[part 1 of 2: package /COM/VECTOR/CFG/WORKFLOW/SYSDESC/SYNC]
AUTOSAR XML (schema 4-2-2)
package /COM/VECTOR/CFG/WORKFLOW/SYSDESC/SYNC
  system SYSTEM
    system mapping MAPPINGS
      data-mappings:
        data-element=COMPOSITIONTYPE.Ford_PwPckTq_D_Stat.Ford_PwPckTq_D_Stat, system-signal=PwPckTq_D_Stat
        data-element=COMPOSITIONTYPE.Ford_Veh_V_ActlBrk.Ford_Veh_V_ActlBrk, system-signal=Veh_V_ActlBrk
        data-element=COMPOSITIONTYPE.Ford_SteMdule_D_Stat.Ford_SteMdule_D_Stat, system-signal=SteMdule_D_Stat
        data-element=COMPOSITIONTYPE.Ford_SteeringColumnTorque.Ford_SteeringColumnTorque, system-signal=SteeringColumnTorque
        data-element=COMPOSITIONTYPE.Ford_VehVActlBrk_No_Cs.Ford_VehVActlBrk_No_Cs, system-signal=VehVActlBrk_No_Cs
        data-element=COMPOSITIONTYPE.Ford_EPAS_Failure.Ford_EPAS_Failure, system-signal=EPAS_Failure
        data-element=COMPOSITIONTYPE.Ford_TrlrHitchLamp_D_Rqst.Ford_TrlrHitchLamp_D_Rqst, system-signal=TrlrHitchLamp_D_Rqst
        data-element=COMPOSITIONTYPE.Ford_SAPPAngleControlStat2.Ford_SAPPAngleControlStat2, system-signal=SAPPAngleControlStat2
        data-element=COMPOSITIONTYPE.Ford_StePinComp_An_Est.Ford_StePinComp_An_Est, system-signal=StePinComp_An_Est
        data-element=COMPOSITIONTYPE.Ford_ElPw_D_Stat.Ford_ElPw_D_Stat, system-signal=ElPw_D_Stat
        data-element=COMPOSITIONTYPE.Ford_Ignition_Status.Ford_Ignition_Status, system-signal=Ignition_Status
        data-element=COMPOSITIONTYPE.Ford_VehVActlBrk_No_Cnt.Ford_VehVActlBrk_No_Cnt, system-signal=VehVActlBrk_No_Cnt
        data-element=COMPOSITIONTYPE.Ford_StePinCompAnEst_D_Qf.Ford_StePinCompAnEst_D_Qf, system-signal=StePinCompAnEst_D_Qf
        data-element=COMPOSITIONTYPE.Ford_VehVTrlrAid_B_Rq.Ford_VehVTrlrAid_B_Rq, system-signal=VehVTrlrAid_B_Rq
        data-element=COMPOSITIONTYPE.Ford_LsmcBrkDecel_D_Stat.Ford_LsmcBrkDecel_D_Stat, system-signal=LsmcBrkDecel_D_Stat
        data-element=COMPOSITIONTYPE.Ford_SteMdule_U_Meas.Ford_SteMdule_U_Meas, system-signal=SteMdule_U_Meas
        data-element=COMPOSITIONTYPE.Ford_StePinAn_No_Cnt.Ford_StePinAn_No_Cnt, system-signal=StePinAn_No_Cnt
        data-element=COMPOSITIONTYPE.Ford_StePinRelInit_An_Sns.Ford_StePinRelInit_An_Sns, system-signal=StePinRelInit_An_Sns
        data-element=COMPOSITIONTYPE.Ford_StePinAn_No_Cs.Ford_StePinAn_No_Cs, system-signal=StePinAn_No_Cs
        data-element=COMPOSITIONTYPE.Ford_Veh_V_RqMxTrlrAid.Ford_Veh_V_RqMxTrlrAid, system-signal=Veh_V_RqMxTrlrAid
        data-element=COMPOSITIONTYPE.Ford_SAPPAngleControlStat5.Ford_SAPPAngleControlStat5, system-signal=SAPPAngleControlStat5
        data-element=COMPOSITIONTYPE.Ford_LatCtlSte_D_Stat.Ford_LatCtlSte_D_Stat, system-signal=LatCtlSte_D_Stat
        data-element=COMPOSITIONTYPE.Ford_StePw_B_Rq.Ford_StePw_B_Rq, system-signal=StePw_B_Rq
        data-element=COMPOSITIONTYPE.Ford_DrvSteActv_B_Stat.Ford_DrvSteActv_B_Stat, system-signal=DrvSteActv_B_Stat
        data-element=COMPOSITIONTYPE.Ford_VehVActlBrk_D_Qf.Ford_VehVActlBrk_D_Qf, system-signal=VehVActlBrk_D_Qf
        data-element=COMPOSITIONTYPE.Ford_ElPw_D_StatStrtStop.Ford_ElPw_D_StatStrtStop, system-signal=ElPw_D_StatStrtStop
        data-element=COMPOSITIONTYPE.Ford_LatCtlLim_D_Stat.Ford_LatCtlLim_D_Stat, system-signal=LatCtlLim_D_Stat
        data-element=COMPOSITIONTYPE.Ford_SteMdule_I_Est.Ford_SteMdule_I_Est, system-signal=SteMdule_I_Est
        data-element=COMPOSITIONTYPE.Ford_SAPPAngleControlStat4.Ford_SAPPAngleControlStat4, system-signal=SAPPAngleControlStat4
        data-element=COMPOSITIONTYPE.Ford_PrplWhlTot2_Tq_Actl.Ford_PrplWhlTot2_Tq_Actl, system-signal=PrplWhlTot2_Tq_Actl
        data-element=COMPOSITIONTYPE.Ford_SAPPAngleControlStat6.Ford_SAPPAngleControlStat6, system-signal=SAPPAngleControlStat6
        data-element=COMPOSITIONTYPE.Ford_SAPPAngleControlStat3.Ford_SAPPAngleControlStat3, system-signal=SAPPAngleControlStat3
        data-element=COMPOSITIONTYPE.Ford_SelDrvMdeSte_D_Stat.Ford_SelDrvMdeSte_D_Stat, system-signal=SelDrvMdeSte_D_Stat
        data-element=COMPOSITIONTYPE.Ford_SAPPAngleControlStat1.Ford_SAPPAngleControlStat1, system-signal=SAPPAngleControlStat1
        data-element=COMPOSITIONTYPE.Ford_BrkTot_Tq_Actl.Ford_BrkTot_Tq_Actl, system-signal=BrkTot_Tq_Actl
        data-element=COMPOSITIONTYPE.Ford_TrlrAidCancl_B_Rq.Ford_TrlrAidCancl_B_Rq, system-signal=TrlrAidCancl_B_Rq
        data-element=COMPOSITIONTYPE.Ford_LaHandsOff_B_Actl.Ford_LaHandsOff_B_Actl, system-signal=LaHandsOff_B_Actl
        data-element=COMPOSITIONTYPE.Ford_CmbbObjDistLong_L_Actl.Ford_CmbbObjDistLong_L_Actl, system-signal=CmbbObjDistLong_L_Actl
        data-element=COMPOSITIONTYPE.Ford_TrlrAidSetup_D2_Stat.Ford_TrlrAidSetup_D2_Stat, system-signal=TrlrAidSetup_D2_Stat
        data-element=COMPOSITIONTYPE.Ford_TrlrAidMsgTxt_D2_Rq.Ford_TrlrAidMsgTxt_D2_Rq, system-signal=TrlrAidMsgTxt_D2_Rq
        data-element=COMPOSITIONTYPE.Ford_DrvSte_Tq_Actl.Ford_DrvSte_Tq_Actl, system-signal=DrvSte_Tq_Actl
        data-element=COMPOSITIONTYPE.Ford_SelDrvMdeChassis2_D_Rq.Ford_SelDrvMdeChassis2_D_Rq, system-signal=SelDrvMdeChassis2_D_Rq
        data-element=COMPOSITIONTYPE.Ford_FileVersionNumber.Ford_FileVersionNumber, system-signal=FileVersionNumber
        data-element=COMPOSITIONTYPE.Ford_LatCtlPath_An_Actl.Ford_LatCtlPath_An_Actl, system-signal=LatCtlPath_An_Actl
        data-element=COMPOSITIONTYPE.Ford_TrlrLampCnnct_B_Actl.Ford_TrlrLampCnnct_B_Actl, system-signal=TrlrLampCnnct_B_Actl
        data-element=COMPOSITIONTYPE.Ford_WhlFr_W_Meas.Ford_WhlFr_W_Meas, system-signal=WhlFr_W_Meas
        data-element=COMPOSITIONTYPE.Ford_WhlRotatFl_No_Cnt.Ford_WhlRotatFl_No_Cnt, system-signal=WhlRotatFl_No_Cnt
        data-element=COMPOSITIONTYPE.Ford_Outside_Air_Temp_Stat.Ford_Outside_Air_Temp_Stat, system-signal=Outside_Air_Temp_Stat
        data-element=COMPOSITIONTYPE.Ford_VehVertComp_A_Actl.Ford_VehVertComp_A_Actl, system-signal=VehVertComp_A_Actl
        data-element=COMPOSITIONTYPE.Ford_TrlrAidEnbl_D2_Rq.Ford_TrlrAidEnbl_D2_Rq, system-signal=TrlrAidEnbl_D2_Rq
        data-element=COMPOSITIONTYPE.Ford_WhlRotatFr_No_Cnt.Ford_WhlRotatFr_No_Cnt, system-signal=WhlRotatFr_No_Cnt
        data-element=COMPOSITIONTYPE.Ford_TurnLghtSwtch_D_Stat.Ford_TurnLghtSwtch_D_Stat, system-signal=TurnLghtSwtch_D_Stat
        data-element=COMPOSITIONTYPE.Ford_CmbbObjRelLat_V_Actl.Ford_CmbbObjRelLat_V_Actl, system-signal=CmbbObjRelLat_V_Actl
        data-element=COMPOSITIONTYPE.Ford_TrlrIdType_D_Stat.Ford_TrlrIdType_D_Stat, system-signal=TrlrIdType_D_Stat
        data-element=COMPOSITIONTYPE.Ford_ApedPos_Pc_ActlArb.Ford_ApedPos_Pc_ActlArb, system-signal=ApedPos_Pc_ActlArb
        data-element=COMPOSITIONTYPE.Ford_StePinOffst_An_Est.Ford_StePinOffst_An_Est, system-signal=StePinOffst_An_Est
        data-element=COMPOSITIONTYPE.Ford_LsmcBrkDecelEnbl_D_Rq.Ford_LsmcBrkDecelEnbl_D_Rq, system-signal=LsmcBrkDecelEnbl_D_Rq
        data-element=COMPOSITIONTYPE.Ford_TrlrHitchYaw_An_Actl.Ford_TrlrHitchYaw_An_Actl, system-signal=TrlrHitchYaw_An_Actl
        data-element=COMPOSITIONTYPE.Ford_StePinOffst_D_Stat.Ford_StePinOffst_D_Stat, system-signal=StePinOffst_D_Stat
        data-element=COMPOSITIONTYPE.Ford_CmbbBrkDis_B_Actl.Ford_CmbbBrkDis_B_Actl, system-signal=CmbbBrkDis_B_Actl
        data-element=COMPOSITIONTYPE.Ford_TrlrAidSetup_D2_Rq.Ford_TrlrAidSetup_D2_Rq, system-signal=TrlrAidSetup_D2_Rq
        data-element=COMPOSITIONTYPE.Ford_Veh_V_ActlEng.Ford_Veh_V_ActlEng, system-signal=Veh_V_ActlEng
        data-element=COMPOSITIONTYPE.Ford_YawStabilityIndex.Ford_YawStabilityIndex, system-signal=YawStabilityIndex
        data-element=COMPOSITIONTYPE.Ford_TrlrTrgtAcquire_D_Stat.Ford_TrlrTrgtAcquire_D_Stat, system-signal=TrlrTrgtAcquire_D_Stat
        data-element=COMPOSITIONTYPE.Ford_CmbbObjDistLat_L_Actl.Ford_CmbbObjDistLat_L_Actl, system-signal=CmbbObjDistLat_L_Actl
        data-element=COMPOSITIONTYPE.Ford_TrlrId_No_Actl.Ford_TrlrId_No_Actl, system-signal=TrlrId_No_Actl
        data-element=COMPOSITIONTYPE.Ford_TrlrYaw_W_Actl.Ford_TrlrYaw_W_Actl, system-signal=TrlrYaw_W_Actl
        data-element=COMPOSITIONTYPE.Ford_BattULo_U_Actl.Ford_BattULo_U_Actl, system-signal=BattULo_U_Actl
        data-element=COMPOSITIONTYPE.Ford_DeliverySubProjectNumber.Ford_DeliverySubProjectNumber, system-signal=DeliverySubProjectNumber
        data-element=COMPOSITIONTYPE.Ford_TrlrBrkActCnnct_B_Actl.Ford_TrlrBrkActCnnct_B_Actl, system-signal=TrlrBrkActCnnct_B_Actl
        data-element=COMPOSITIONTYPE.Ford_FileVersionYear.Ford_FileVersionYear, system-signal=FileVersionYear
        data-element=COMPOSITIONTYPE.Ford_FileVersionMonth.Ford_FileVersionMonth, system-signal=FileVersionMonth
        data-element=COMPOSITIONTYPE.Ford_EsaEnbl_D2_Rq.Ford_EsaEnbl_D2_Rq, system-signal=EsaEnbl_D2_Rq
        data-element=COMPOSITIONTYPE.Ford_StePinOffst_No_Cnt.Ford_StePinOffst_No_Cnt, system-signal=StePinOffst_No_Cnt
        data-element=COMPOSITIONTYPE.Ford_TrlrAidTrgtId_No_Rq.Ford_TrlrAidTrgtId_No_Rq, system-signal=TrlrAidTrgtId_No_Rq
        data-element=COMPOSITIONTYPE.Ford_GearRvrse_D_Actl.Ford_GearRvrse_D_Actl, system-signal=GearRvrse_D_Actl
        data-element=COMPOSITIONTYPE.Ford_TrlrAid_An3_Actl.Ford_TrlrAid_An3_Actl, system-signal=TrlrAid_An3_Actl
        data-element=COMPOSITIONTYPE.Ford_LdwActvStats_D_Req.Ford_LdwActvStats_D_Req, system-signal=LdwActvStats_D_Req
        data-element=COMPOSITIONTYPE.Ford_LsmcBrk_Tq_Rq.Ford_LsmcBrk_Tq_Rq, system-signal=LsmcBrk_Tq_Rq
        data-element=COMPOSITIONTYPE.Ford_VehVActlEng_No_Cs.Ford_VehVActlEng_No_Cs, system-signal=VehVActlEng_No_Cs
        data-element=COMPOSITIONTYPE.Ford_LaActDeny_B_Actl.Ford_LaActDeny_B_Actl, system-signal=LaActDeny_B_Actl
        data-element=COMPOSITIONTYPE.Ford_VehVActlEng_D_Qf.Ford_VehVActlEng_D_Qf, system-signal=VehVActlEng_D_Qf
        data-element=COMPOSITIONTYPE.Ford_TrnRng_D_Rq.Ford_TrnRng_D_Rq, system-signal=TrnRng_D_Rq
        data-element=COMPOSITIONTYPE.Ford_TrlrAnOffstDir_D_Mem.Ford_TrlrAnOffstDir_D_Mem, system-signal=TrlrAnOffstDir_D_Mem
        data-element=COMPOSITIONTYPE.Ford_WhlRotatRr_No_Cnt.Ford_WhlRotatRr_No_Cnt, system-signal=WhlRotatRr_No_Cnt
        data-element=COMPOSITIONTYPE.Ford_GearLvrPos_D_Actl.Ford_GearLvrPos_D_Actl, system-signal=GearLvrPos_D_Actl
        data-element=COMPOSITIONTYPE.Ford_TrlrYawWActl_D_Qf.Ford_TrlrYawWActl_D_Qf, system-signal=TrlrYawWActl_D_Qf
        data-element=COMPOSITIONTYPE.Ford_TrlrRvrse_D_Stat.Ford_TrlrRvrse_D_Stat, system-signal=TrlrRvrse_D_Stat
        data-element=COMPOSITIONTYPE.Ford_LatCtlCurv_No_Actl.Ford_LatCtlCurv_No_Actl, system-signal=LatCtlCurv_No_Actl
        data-element=COMPOSITIONTYPE.Ford_TrlrAn_An_WarnCalc.Ford_TrlrAn_An_WarnCalc, system-signal=TrlrAn_An_WarnCalc
        data-element=COMPOSITIONTYPE.Ford_StePinOffst_No_Cs.Ford_StePinOffst_No_Cs, system-signal=StePinOffst_No_Cs
        data-element=COMPOSITIONTYPE.Ford_BPedDrvAppl_D_QF.Ford_BPedDrvAppl_D_QF, system-signal=BPedDrvAppl_D_QF
        data-element=COMPOSITIONTYPE.Ford_DeliverySipNumber.Ford_DeliverySipNumber, system-signal=DeliverySipNumber
        data-element=COMPOSITIONTYPE.Ford_LatCtlCurv_NoRate_Actl.Ford_LatCtlCurv_NoRate_Actl, system-signal=LatCtlCurv_NoRate_Actl
        data-element=COMPOSITIONTYPE.Ford_LatCtlRng_L_Max.Ford_LatCtlRng_L_Max, system-signal=LatCtlRng_L_Max
        data-element=COMPOSITIONTYPE.Ford_TrlrRvrseCancl_B_Rq.Ford_TrlrRvrseCancl_B_Rq, system-signal=TrlrRvrseCancl_B_Rq
        data-element=COMPOSITIONTYPE.Ford_LaActAvail_D_Actl.Ford_LaActAvail_D_Actl, system-signal=LaActAvail_D_Actl
        data-element=COMPOSITIONTYPE.Ford_TrlrAidSwtch_D_RqDrv.Ford_TrlrAidSwtch_D_RqDrv, system-signal=TrlrAidSwtch_D_RqDrv
        data-element=COMPOSITIONTYPE.Ford_TrlrRvrseMsgTxt_D2_Rq.Ford_TrlrRvrseMsgTxt_D2_Rq, system-signal=TrlrRvrseMsgTxt_D2_Rq
        data-element=COMPOSITIONTYPE.Ford_VehLatComp_A_Actl.Ford_VehLatComp_A_Actl, system-signal=VehLatComp_A_Actl
        data-element=COMPOSITIONTYPE.Ford_DrvSte_D_Stat.Ford_DrvSte_D_Stat, system-signal=DrvSte_D_Stat
        data-element=COMPOSITIONTYPE.Ford_TrlrSnsId_No_Actl.Ford_TrlrSnsId_No_Actl, system-signal=TrlrSnsId_No_Actl
        data-element=COMPOSITIONTYPE.Ford_TrlrAidEnbl_D2_Stat.Ford_TrlrAidEnbl_D2_Stat, system-signal=TrlrAidEnbl_D2_Stat
        data-element=COMPOSITIONTYPE.Ford_GearPos_D_Actl.Ford_GearPos_D_Actl, system-signal=GearPos_D_Actl
        data-element=COMPOSITIONTYPE.Ford_VehYawComp_W_Actl.Ford_VehYawComp_W_Actl, system-signal=VehYawComp_W_Actl
        data-element=COMPOSITIONTYPE.Ford_VehicleGGCCData.Ford_VehicleGGCCData, system-signal=VehicleGGCCData
        data-element=COMPOSITIONTYPE.Ford_LkaDrvOvrrd_D_Rq.Ford_LkaDrvOvrrd_D_Rq, system-signal=LkaDrvOvrrd_D_Rq
        data-element=COMPOSITIONTYPE.Ford_TrlrHitYaw_AnRate_Actl.Ford_TrlrHitYaw_AnRate_Actl, system-signal=TrlrHitYaw_AnRate_Actl
        data-element=COMPOSITIONTYPE.Ford_CmbbDeny_B_ActlBrk.Ford_CmbbDeny_B_ActlBrk, system-signal=CmbbDeny_B_ActlBrk
        data-element=COMPOSITIONTYPE.Ford_OdometerMasterValue.Ford_OdometerMasterValue, system-signal=OdometerMasterValue
        data-element=COMPOSITIONTYPE.Ford_DrvSte_Tq_Rq.Ford_DrvSte_Tq_Rq, system-signal=DrvSte_Tq_Rq
        data-element=COMPOSITIONTYPE.Ford_WhlFl_W_Meas.Ford_WhlFl_W_Meas, system-signal=WhlFl_W_Meas
        data-element=COMPOSITIONTYPE.Ford_TrlrAidTrgtId_No_Actl.Ford_TrlrAidTrgtId_No_Actl, system-signal=TrlrAidTrgtId_No_Actl
        data-element=COMPOSITIONTYPE.Ford_HandsOffCnfm_B_Rq.Ford_HandsOffCnfm_B_Rq, system-signal=HandsOffCnfm_B_Rq
        data-element=COMPOSITIONTYPE.Ford_TrlrAid_D2_Stat.Ford_TrlrAid_D2_Stat, system-signal=TrlrAid_D2_Stat
        data-element=COMPOSITIONTYPE.Ford_CmbbObjColl_T_Actl.Ford_CmbbObjColl_T_Actl, system-signal=CmbbObjColl_T_Actl
        data-element=COMPOSITIONTYPE.Ford_VehLongComp_A_Actl.Ford_VehLongComp_A_Actl, system-signal=VehLongComp_A_Actl
        data-element=COMPOSITIONTYPE.Ford_TrlrHitchYaw_D_Stat.Ford_TrlrHitchYaw_D_Stat, system-signal=TrlrHitchYaw_D_Stat
        data-element=COMPOSITIONTYPE.Ford_TrlrAidCtl_U_RqDrv.Ford_TrlrAidCtl_U_RqDrv, system-signal=TrlrAidCtl_U_RqDrv
        data-element=COMPOSITIONTYPE.Ford_VehOverGnd_V_Est.Ford_VehOverGnd_V_Est, system-signal=VehOverGnd_V_Est
        data-element=COMPOSITIONTYPE.Ford_WhlRotatRl_No_Cnt.Ford_WhlRotatRl_No_Cnt, system-signal=WhlRotatRl_No_Cnt
        data-element=COMPOSITIONTYPE.Ford_EPASExtAngleStatReq.Ford_EPASExtAngleStatReq, system-signal=EPASExtAngleStatReq
        data-element=COMPOSITIONTYPE.Ford_WhlRl_W_Meas.Ford_WhlRl_W_Meas, system-signal=WhlRl_W_Meas
        data-element=COMPOSITIONTYPE.Ford_WhlDirRr_D_Actl.Ford_WhlDirRr_D_Actl, system-signal=WhlDirRr_D_Actl
        data-element=COMPOSITIONTYPE.Ford_TrlrAn_An_MxCalc.Ford_TrlrAn_An_MxCalc, system-signal=TrlrAn_An_MxCalc
        data-element=COMPOSITIONTYPE.Ford_EsaOn_B_Rq.Ford_EsaOn_B_Rq, system-signal=EsaOn_B_Rq
        data-element=COMPOSITIONTYPE.Ford_ExtSteeringAngleReq2.Ford_ExtSteeringAngleReq2, system-signal=ExtSteeringAngleReq2
        data-element=COMPOSITIONTYPE.Ford_WhlDirRl_D_Actl.Ford_WhlDirRl_D_Actl, system-signal=WhlDirRl_D_Actl
        data-element=COMPOSITIONTYPE.Ford_VehVTrlrAid_B_Avail.Ford_VehVTrlrAid_B_Avail, system-signal=VehVTrlrAid_B_Avail
        data-element=COMPOSITIONTYPE.Ford_LatCtlRampType_D_Rq.Ford_LatCtlRampType_D_Rq, system-signal=LatCtlRampType_D_Rq
        data-element=COMPOSITIONTYPE.Ford_AbsActv_B_Actl.Ford_AbsActv_B_Actl, system-signal=AbsActv_B_Actl
        data-element=COMPOSITIONTYPE.Ford_CmbbObjConfdnc_D_Stat.Ford_CmbbObjConfdnc_D_Stat, system-signal=CmbbObjConfdnc_D_Stat
        data-element=COMPOSITIONTYPE.Ford_EngAout_N_Actl.Ford_EngAout_N_Actl, system-signal=EngAout_N_Actl
        data-element=COMPOSITIONTYPE.Ford_LatCtlPathOffst_L_Actl.Ford_LatCtlPathOffst_L_Actl, system-signal=LatCtlPathOffst_L_Actl
        data-element=COMPOSITIONTYPE.Ford_DeliveryNumber.Ford_DeliveryNumber, system-signal=DeliveryNumber
        data-element=COMPOSITIONTYPE.Ford_LifeCycMde_D_Actl.Ford_LifeCycMde_D_Actl, system-signal=LifeCycMde_D_Actl
        data-element=COMPOSITIONTYPE.Ford_SteWhlRelCalib_An_Sns.Ford_SteWhlRelCalib_An_Sns, system-signal=SteWhlRelCalib_An_Sns
        data-element=COMPOSITIONTYPE.Ford_BpedDrvAppl_D_Actl.Ford_BpedDrvAppl_D_Actl, system-signal=BpedDrvAppl_D_Actl
        data-element=COMPOSITIONTYPE.Ford_LaRefAng_No_Req.Ford_LaRefAng_No_Req, system-signal=LaRefAng_No_Req
        data-element=COMPOSITIONTYPE.Ford_TrlrAn_An_TrgtCalc.Ford_TrlrAn_An_TrgtCalc, system-signal=TrlrAn_An_TrgtCalc
        data-element=COMPOSITIONTYPE.Ford_StabCtlBrkActv_B_Actl.Ford_StabCtlBrkActv_B_Actl, system-signal=StabCtlBrkActv_B_Actl
        data-element=COMPOSITIONTYPE.Ford_TrlrAidTrlrId_No_Rq.Ford_TrlrAidTrlrId_No_Rq, system-signal=TrlrAidTrlrId_No_Rq
        data-element=COMPOSITIONTYPE.Ford_TrlrAnOffst_An2_Calc.Ford_TrlrAnOffst_An2_Calc, system-signal=TrlrAnOffst_An2_Calc
        data-element=COMPOSITIONTYPE.Ford_WhlDirFl_D_Actl.Ford_WhlDirFl_D_Actl, system-signal=WhlDirFl_D_Actl
        data-element=COMPOSITIONTYPE.Ford_LaCurvature_No_Calc.Ford_LaCurvature_No_Calc, system-signal=LaCurvature_No_Calc
        data-element=COMPOSITIONTYPE.Ford_VehVActlEng_No_Cnt.Ford_VehVActlEng_No_Cnt, system-signal=VehVActlEng_No_Cnt
        data-element=COMPOSITIONTYPE.Ford_DeliveryIdle.Ford_DeliveryIdle, system-signal=DeliveryIdle
        data-element=COMPOSITIONTYPE.Ford_ApaSys_D_Stat.Ford_ApaSys_D_Stat, system-signal=ApaSys_D_Stat
        data-element=COMPOSITIONTYPE.Ford_LdwActvIntns_D_Req.Ford_LdwActvIntns_D_Req, system-signal=LdwActvIntns_D_Req
        data-element=COMPOSITIONTYPE.Ford_TrlrAidMde_D_Rq.Ford_TrlrAidMde_D_Rq, system-signal=TrlrAidMde_D_Rq
        data-element=COMPOSITIONTYPE.Ford_FileVersionDay.Ford_FileVersionDay, system-signal=FileVersionDay
        data-element=COMPOSITIONTYPE.Ford_HitchToVehAxle_L_Calc.Ford_HitchToVehAxle_L_Calc, system-signal=HitchToVehAxle_L_Calc
        data-element=COMPOSITIONTYPE.Ford_CmbbObjClass_D_Stat.Ford_CmbbObjClass_D_Stat, system-signal=CmbbObjClass_D_Stat
        data-element=COMPOSITIONTYPE.Ford_WhlDirFr_D_Actl.Ford_WhlDirFr_D_Actl, system-signal=WhlDirFr_D_Actl
        data-element=COMPOSITIONTYPE.Ford_LaRampType_B_Req.Ford_LaRampType_B_Req, system-signal=LaRampType_B_Req
        data-element=COMPOSITIONTYPE.Ford_LkaActvStats_D2_Req.Ford_LkaActvStats_D2_Req, system-signal=LkaActvStats_D2_Req
        data-element=COMPOSITIONTYPE.Ford_TrlrAid_AnRate2_Actl.Ford_TrlrAid_AnRate2_Actl, system-signal=TrlrAid_AnRate2_Actl
        data-element=COMPOSITIONTYPE.Ford_HitchToTrlrAxle_L_Calc.Ford_HitchToTrlrAxle_L_Calc, system-signal=HitchToTrlrAxle_L_Calc
        data-element=COMPOSITIONTYPE.Ford_WhlRr_W_Meas.Ford_WhlRr_W_Meas, system-signal=WhlRr_W_Meas
        data-element=COMPOSITIONTYPE.Ford_TrlrRvrseEnbl_D2_Stat.Ford_TrlrRvrseEnbl_D2_Stat, system-signal=TrlrRvrseEnbl_D2_Stat
        data-element=COMPOSITIONTYPE.Ford_LatCtl_D_Rq.Ford_LatCtl_D_Rq, system-signal=LatCtl_D_Rq
        data-element=COMPOSITIONTYPE.Ford_CmbbObjRelLong_V_Actl.Ford_CmbbObjRelLong_V_Actl, system-signal=CmbbObjRelLong_V_Actl
        data-element=COMPOSITIONTYPE.Ford_TjaHandsOnCnfdnc_B_Est.Ford_TjaHandsOnCnfdnc_B_Est, system-signal=TjaHandsOnCnfdnc_B_Est
        data-element=COMPOSITIONTYPE.Ford_ApedPosPcActl_D_Qf.Ford_ApedPosPcActl_D_Qf, system-signal=ApedPosPcActl_D_Qf
        data-element=COMPOSITIONTYPE.Ford_LatCtlPrecision_D_Rq.Ford_LatCtlPrecision_D_Rq, system-signal=LatCtlPrecision_D_Rq
        data-element=COMPOSITIONTYPE.Ford_TrlrAxleToBmpr_L_Actl.Ford_TrlrAxleToBmpr_L_Actl, system-signal=TrlrAxleToBmpr_L_Actl
        data-element=COMPOSITIONTYPE.Ford_EsaOn_B_Stat.Ford_EsaOn_B_Stat, system-signal=EsaOn_B_Stat
        data-element=COMPOSITIONTYPE.Ford_VehYaw_W_Actl.Ford_VehYaw_W_Actl, system-signal=VehYaw_W_Actl
    root-software-compositions:
      root sw composition prototype COMPOSITIONTYPE: flat-map=FLATMAP, software-composition=COMPOSITIONTYPE
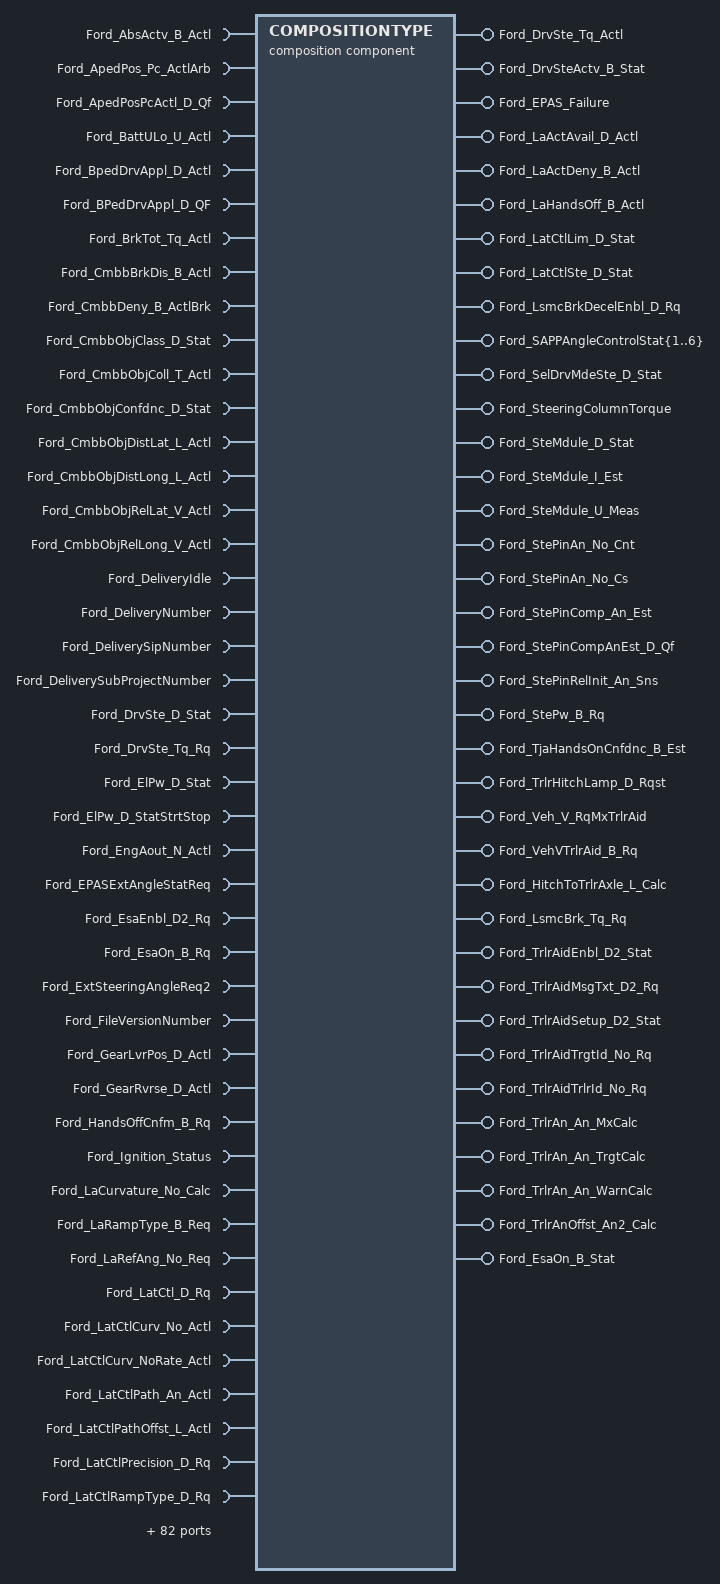
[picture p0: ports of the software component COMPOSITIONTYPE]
  composition sw component type COMPOSITIONTYPE
    30 x provide port:
      Ford_DrvSte_Tq_Actl: nonqueued-sender-com-spec{data-element=Ford_DrvSte_Tq_Actl, init-value=128}, provided-interface=Ford_DrvSte_Tq_Actl
      Ford_DrvSteActv_B_Stat: nonqueued-sender-com-spec{data-element=Ford_DrvSteActv_B_Stat, init-value=0}, provided-interface=Ford_DrvSteActv_B_Stat
      Ford_EPAS_Failure: nonqueued-sender-com-spec{data-element=Ford_EPAS_Failure, init-value=0}, provided-interface=Ford_EPAS_Failure
      Ford_LaActAvail_D_Actl: nonqueued-sender-com-spec{data-element=Ford_LaActAvail_D_Actl, init-value=0}, provided-interface=Ford_LaActAvail_D_Actl
      Ford_LaActDeny_B_Actl: nonqueued-sender-com-spec{data-element=Ford_LaActDeny_B_Actl, init-value=0}, provided-interface=Ford_LaActDeny_B_Actl
      Ford_LaHandsOff_B_Actl: nonqueued-sender-com-spec{data-element=Ford_LaHandsOff_B_Actl, init-value=1}, provided-interface=Ford_LaHandsOff_B_Actl
      Ford_LatCtlLim_D_Stat: nonqueued-sender-com-spec{data-element=Ford_LatCtlLim_D_Stat, init-value=0}, provided-interface=Ford_LatCtlLim_D_Stat
      Ford_LatCtlSte_D_Stat: nonqueued-sender-com-spec{data-element=Ford_LatCtlSte_D_Stat, init-value=0}, provided-interface=Ford_LatCtlSte_D_Stat
      Ford_LsmcBrkDecelEnbl_D_Rq: nonqueued-sender-com-spec{data-element=Ford_LsmcBrkDecelEnbl_D_Rq, init-value=0}, provided-interface=Ford_LsmcBrkDecelEnbl_D_Rq
      Ford_SAPPAngleControlStat{1..6}: nonqueued-sender-com-spec{data-element=Ford_SAPPAngleControlStat{1..6}, init-value=0}, provided-interface=Ford_SAPPAngleControlStat{1..6}
      Ford_SelDrvMdeSte_D_Stat: nonqueued-sender-com-spec{data-element=Ford_SelDrvMdeSte_D_Stat, init-value=0}, provided-interface=Ford_SelDrvMdeSte_D_Stat
      Ford_SteeringColumnTorque: nonqueued-sender-com-spec{data-element=Ford_SteeringColumnTorque, init-value=254}, provided-interface=Ford_SteeringColumnTorque
      Ford_SteMdule_D_Stat: nonqueued-sender-com-spec{data-element=Ford_SteMdule_D_Stat, init-value=0}, provided-interface=Ford_SteMdule_D_Stat
      Ford_SteMdule_I_Est: nonqueued-sender-com-spec{data-element=Ford_SteMdule_I_Est, init-value=4095}, provided-interface=Ford_SteMdule_I_Est
      Ford_SteMdule_U_Meas: nonqueued-sender-com-spec{data-element=Ford_SteMdule_U_Meas, init-value=255}, provided-interface=Ford_SteMdule_U_Meas
      Ford_StePinAn_No_Cnt: nonqueued-sender-com-spec{data-element=Ford_StePinAn_No_Cnt, init-value=0}, provided-interface=Ford_StePinAn_No_Cnt
      Ford_StePinAn_No_Cs: nonqueued-sender-com-spec{data-element=Ford_StePinAn_No_Cs, init-value=0}, provided-interface=Ford_StePinAn_No_Cs
      Ford_StePinComp_An_Est: nonqueued-sender-com-spec{data-element=Ford_StePinComp_An_Est, init-value=16000}, provided-interface=Ford_StePinComp_An_Est
      Ford_StePinCompAnEst_D_Qf: nonqueued-sender-com-spec{data-element=Ford_StePinCompAnEst_D_Qf, init-value=1}, provided-interface=Ford_StePinCompAnEst_D_Qf
      Ford_StePinRelInit_An_Sns: nonqueued-sender-com-spec{data-element=Ford_StePinRelInit_An_Sns, init-value=65535}, provided-interface=Ford_StePinRelInit_An_Sns
      Ford_StePw_B_Rq: nonqueued-sender-com-spec{data-element=Ford_StePw_B_Rq, init-value=0}, provided-interface=Ford_StePw_B_Rq
      Ford_TjaHandsOnCnfdnc_B_Est: nonqueued-sender-com-spec{data-element=Ford_TjaHandsOnCnfdnc_B_Est, init-value=1}, provided-interface=Ford_TjaHandsOnCnfdnc_B_Est
      Ford_TrlrHitchLamp_D_Rqst: nonqueued-sender-com-spec{data-element=Ford_TrlrHitchLamp_D_Rqst, init-value=0}, provided-interface=Ford_TrlrHitchLamp_D_Rqst
      Ford_Veh_V_RqMxTrlrAid: nonqueued-sender-com-spec{data-element=Ford_Veh_V_RqMxTrlrAid, init-value=255}, provided-interface=Ford_Veh_V_RqMxTrlrAid
      Ford_VehVTrlrAid_B_Rq: nonqueued-sender-com-spec{data-element=Ford_VehVTrlrAid_B_Rq, init-value=0}, provided-interface=Ford_VehVTrlrAid_B_Rq
    95 x require port:
      Ford_AbsActv_B_Actl: nonqueued-receiver-com-spec{data-element=Ford_AbsActv_B_Actl, filter=data-filter-type=ALWAYS, init-value=0}, required-interface=Ford_AbsActv_B_Actl
      Ford_ApedPos_Pc_ActlArb: nonqueued-receiver-com-spec{data-element=Ford_ApedPos_Pc_ActlArb, filter=data-filter-type=ALWAYS, init-value=0}, required-interface=Ford_ApedPos_Pc_ActlArb
      Ford_ApedPosPcActl_D_Qf: nonqueued-receiver-com-spec{data-element=Ford_ApedPosPcActl_D_Qf, filter=data-filter-type=ALWAYS, init-value=1}, required-interface=Ford_ApedPosPcActl_D_Qf
      Ford_BattULo_U_Actl: nonqueued-receiver-com-spec{data-element=Ford_BattULo_U_Actl, filter=data-filter-type=ALWAYS, init-value=255}, required-interface=Ford_BattULo_U_Actl
      Ford_BpedDrvAppl_D_Actl: nonqueued-receiver-com-spec{data-element=Ford_BpedDrvAppl_D_Actl, filter=data-filter-type=ALWAYS, init-value=1}, required-interface=Ford_BpedDrvAppl_D_Actl
      Ford_BPedDrvAppl_D_QF: nonqueued-receiver-com-spec{data-element=Ford_BPedDrvAppl_D_QF, filter=data-filter-type=ALWAYS, init-value=1}, required-interface=Ford_BPedDrvAppl_D_QF
      Ford_BrkTot_Tq_Actl: nonqueued-receiver-com-spec{data-element=Ford_BrkTot_Tq_Actl, filter=data-filter-type=ALWAYS, init-value=0}, required-interface=Ford_BrkTot_Tq_Actl
      Ford_CmbbBrkDis_B_Actl: nonqueued-receiver-com-spec{data-element=Ford_CmbbBrkDis_B_Actl, filter=data-filter-type=ALWAYS, init-value=0}, required-interface=Ford_CmbbBrkDis_B_Actl
      Ford_CmbbDeny_B_ActlBrk: nonqueued-receiver-com-spec{data-element=Ford_CmbbDeny_B_ActlBrk, filter=data-filter-type=ALWAYS, init-value=0}, required-interface=Ford_CmbbDeny_B_ActlBrk
      Ford_CmbbObjClass_D_Stat: nonqueued-receiver-com-spec{data-element=Ford_CmbbObjClass_D_Stat, filter=data-filter-type=ALWAYS, init-value=0}, required-interface=Ford_CmbbObjClass_D_Stat
      Ford_CmbbObjColl_T_Actl: nonqueued-receiver-com-spec{data-element=Ford_CmbbObjColl_T_Actl, filter=data-filter-type=ALWAYS, init-value=126}, required-interface=Ford_CmbbObjColl_T_Actl
      Ford_CmbbObjConfdnc_D_Stat: nonqueued-receiver-com-spec{data-element=Ford_CmbbObjConfdnc_D_Stat, filter=data-filter-type=ALWAYS, init-value=0}, required-interface=Ford_CmbbObjConfdnc_D_Stat
      Ford_CmbbObjDistLat_L_Actl: nonqueued-receiver-com-spec{data-element=Ford_CmbbObjDistLat_L_Actl, filter=data-filter-type=ALWAYS, init-value=510}, required-interface=Ford_CmbbObjDistLat_L_Actl
      Ford_CmbbObjDistLong_L_Actl: nonqueued-receiver-com-spec{data-element=Ford_CmbbObjDistLong_L_Actl, filter=data-filter-type=ALWAYS, init-value=1022}, required-interface=Ford_CmbbObjDistLong_L_Actl
      Ford_CmbbObjRelLat_V_Actl: nonqueued-receiver-com-spec{data-element=Ford_CmbbObjRelLat_V_Actl, filter=data-filter-type=ALWAYS, init-value=510}, required-interface=Ford_CmbbObjRelLat_V_Actl
      Ford_CmbbObjRelLong_V_Actl: nonqueued-receiver-com-spec{data-element=Ford_CmbbObjRelLong_V_Actl, filter=data-filter-type=ALWAYS, init-value=1022}, required-interface=Ford_CmbbObjRelLong_V_Actl
      Ford_DeliveryIdle: nonqueued-receiver-com-spec{data-element=Ford_DeliveryIdle, filter=data-filter-type=ALWAYS, init-value=0}, required-interface=Ford_DeliveryIdle
      Ford_DeliveryNumber: nonqueued-receiver-com-spec{data-element=Ford_DeliveryNumber, filter=data-filter-type=ALWAYS, init-value=0}, required-interface=Ford_DeliveryNumber
      Ford_DeliverySipNumber: nonqueued-receiver-com-spec{data-element=Ford_DeliverySipNumber, filter=data-filter-type=ALWAYS, init-value=1507332}, required-interface=Ford_DeliverySipNumber
      Ford_DeliverySubProjectNumber: nonqueued-receiver-com-spec{data-element=Ford_DeliverySubProjectNumber, filter=data-filter-type=ALWAYS, init-value=23072854}, required-interface=Ford_DeliverySubProjectNumber
      Ford_DrvSte_D_Stat: nonqueued-receiver-com-spec{data-element=Ford_DrvSte_D_Stat, filter=data-filter-type=ALWAYS, init-value=0}, required-interface=Ford_DrvSte_D_Stat
      Ford_DrvSte_Tq_Rq: nonqueued-receiver-com-spec{data-element=Ford_DrvSte_Tq_Rq, filter=data-filter-type=ALWAYS, init-value=128}, required-interface=Ford_DrvSte_Tq_Rq
      Ford_ElPw_D_Stat: nonqueued-receiver-com-spec{data-element=Ford_ElPw_D_Stat, filter=data-filter-type=ALWAYS, init-value=0}, required-interface=Ford_ElPw_D_Stat
      Ford_ElPw_D_StatStrtStop: nonqueued-receiver-com-spec{data-element=Ford_ElPw_D_StatStrtStop, filter=data-filter-type=ALWAYS, init-value=0}, required-interface=Ford_ElPw_D_StatStrtStop
      Ford_EngAout_N_Actl: nonqueued-receiver-com-spec{data-element=Ford_EngAout_N_Actl, filter=data-filter-type=ALWAYS, init-value=0}, required-interface=Ford_EngAout_N_Actl
      Ford_EPASExtAngleStatReq: nonqueued-receiver-com-spec{data-element=Ford_EPASExtAngleStatReq, filter=data-filter-type=ALWAYS, init-value=0}, required-interface=Ford_EPASExtAngleStatReq
      Ford_EsaEnbl_D2_Rq: nonqueued-receiver-com-spec{data-element=Ford_EsaEnbl_D2_Rq, filter=data-filter-type=ALWAYS, init-value=0}, required-interface=Ford_EsaEnbl_D2_Rq
      Ford_EsaOn_B_Rq: nonqueued-receiver-com-spec{data-element=Ford_EsaOn_B_Rq, filter=data-filter-type=ALWAYS, init-value=1}, required-interface=Ford_EsaOn_B_Rq
      Ford_ExtSteeringAngleReq2: nonqueued-receiver-com-spec{data-element=Ford_ExtSteeringAngleReq2, filter=data-filter-type=ALWAYS, init-value=0}, required-interface=Ford_ExtSteeringAngleReq2
      Ford_FileVersionNumber: nonqueued-receiver-com-spec{data-element=Ford_FileVersionNumber, filter=data-filter-type=ALWAYS, init-value=5}, required-interface=Ford_FileVersionNumber
      Ford_GearLvrPos_D_Actl: nonqueued-receiver-com-spec{data-element=Ford_GearLvrPos_D_Actl, filter=data-filter-type=ALWAYS, init-value=14}, required-interface=Ford_GearLvrPos_D_Actl
      Ford_GearRvrse_D_Actl: nonqueued-receiver-com-spec{data-element=Ford_GearRvrse_D_Actl, filter=data-filter-type=ALWAYS, init-value=7}, required-interface=Ford_GearRvrse_D_Actl
      Ford_HandsOffCnfm_B_Rq: nonqueued-receiver-com-spec{data-element=Ford_HandsOffCnfm_B_Rq, filter=data-filter-type=ALWAYS, init-value=0}, required-interface=Ford_HandsOffCnfm_B_Rq
      Ford_Ignition_Status: nonqueued-receiver-com-spec{data-element=Ford_Ignition_Status, filter=data-filter-type=ALWAYS, init-value=0}, required-interface=Ford_Ignition_Status
      Ford_LaCurvature_No_Calc: nonqueued-receiver-com-spec{data-element=Ford_LaCurvature_No_Calc, filter=data-filter-type=ALWAYS, init-value=2048}, required-interface=Ford_LaCurvature_No_Calc
      Ford_LaRampType_B_Req: nonqueued-receiver-com-spec{data-element=Ford_LaRampType_B_Req, filter=data-filter-type=ALWAYS, init-value=0}, required-interface=Ford_LaRampType_B_Req
      Ford_LaRefAng_No_Req: nonqueued-receiver-com-spec{data-element=Ford_LaRefAng_No_Req, filter=data-filter-type=ALWAYS, init-value=2048}, required-interface=Ford_LaRefAng_No_Req
      Ford_LatCtl_D_Rq: nonqueued-receiver-com-spec{data-element=Ford_LatCtl_D_Rq, filter=data-filter-type=ALWAYS, init-value=0}, required-interface=Ford_LatCtl_D_Rq
      Ford_LatCtlCurv_No_Actl: nonqueued-receiver-com-spec{data-element=Ford_LatCtlCurv_No_Actl, filter=data-filter-type=ALWAYS, init-value=1000}, required-interface=Ford_LatCtlCurv_No_Actl
      Ford_LatCtlCurv_NoRate_Actl: nonqueued-receiver-com-spec{data-element=Ford_LatCtlCurv_NoRate_Actl, filter=data-filter-type=ALWAYS, init-value=4096}, required-interface=Ford_LatCtlCurv_NoRate_Actl
      Ford_LatCtlPath_An_Actl: nonqueued-receiver-com-spec{data-element=Ford_LatCtlPath_An_Actl, filter=data-filter-type=ALWAYS, init-value=1000}, required-interface=Ford_LatCtlPath_An_Actl
      Ford_LatCtlPathOffst_L_Actl: nonqueued-receiver-com-spec{data-element=Ford_LatCtlPathOffst_L_Actl, filter=data-filter-type=ALWAYS, init-value=512}, required-interface=Ford_LatCtlPathOffst_L_Actl
      Ford_LatCtlPrecision_D_Rq: nonqueued-receiver-com-spec{data-element=Ford_LatCtlPrecision_D_Rq, filter=data-filter-type=ALWAYS, init-value=0}, required-interface=Ford_LatCtlPrecision_D_Rq
      Ford_LatCtlRampType_D_Rq: nonqueued-receiver-com-spec{data-element=Ford_LatCtlRampType_D_Rq, filter=data-filter-type=ALWAYS, init-value=0}, required-interface=Ford_LatCtlRampType_D_Rq
      Ford_LdwActvIntns_D_Req: nonqueued-receiver-com-spec{data-element=Ford_LdwActvIntns_D_Req, filter=data-filter-type=ALWAYS, init-value=0}, required-interface=Ford_LdwActvIntns_D_Req
      Ford_LdwActvStats_D_Req: nonqueued-receiver-com-spec{data-element=Ford_LdwActvStats_D_Req, filter=data-filter-type=ALWAYS, init-value=0}, required-interface=Ford_LdwActvStats_D_Req
      Ford_LkaActvStats_D2_Req: nonqueued-receiver-com-spec{data-element=Ford_LkaActvStats_D2_Req, filter=data-filter-type=ALWAYS, init-value=0}, required-interface=Ford_LkaActvStats_D2_Req
      Ford_LsmcBrkDecel_D_Stat: nonqueued-receiver-com-spec{data-element=Ford_LsmcBrkDecel_D_Stat, filter=data-filter-type=ALWAYS, init-value=0}, required-interface=Ford_LsmcBrkDecel_D_Stat
      Ford_OdometerMasterValue: nonqueued-receiver-com-spec{data-element=Ford_OdometerMasterValue, filter=data-filter-type=ALWAYS, init-value=0}, required-interface=Ford_OdometerMasterValue
      Ford_Outside_Air_Temp_Stat: nonqueued-receiver-com-spec{data-element=Ford_Outside_Air_Temp_Stat, filter=data-filter-type=ALWAYS, init-value=254}, required-interface=Ford_Outside_Air_Temp_Stat
      Ford_PrplWhlTot2_Tq_Actl: nonqueued-receiver-com-spec{data-element=Ford_PrplWhlTot2_Tq_Actl, filter=data-filter-type=ALWAYS, init-value=0}, required-interface=Ford_PrplWhlTot2_Tq_Actl
      Ford_PwPckTq_D_Stat: nonqueued-receiver-com-spec{data-element=Ford_PwPckTq_D_Stat, filter=data-filter-type=ALWAYS, init-value=0}, required-interface=Ford_PwPckTq_D_Stat
      Ford_StabCtlBrkActv_B_Actl: nonqueued-receiver-com-spec{data-element=Ford_StabCtlBrkActv_B_Actl, filter=data-filter-type=ALWAYS, init-value=0}, required-interface=Ford_StabCtlBrkActv_B_Actl
      Ford_StePinOffst_An_Est: nonqueued-receiver-com-spec{data-element=Ford_StePinOffst_An_Est, filter=data-filter-type=ALWAYS, init-value=65534}, required-interface=Ford_StePinOffst_An_Est
      Ford_StePinOffst_D_Stat: nonqueued-receiver-com-spec{data-element=Ford_StePinOffst_D_Stat, filter=data-filter-type=ALWAYS, init-value=0}, required-interface=Ford_StePinOffst_D_Stat
      Ford_SteWhlRelCalib_An_Sns: nonqueued-receiver-com-spec{data-element=Ford_SteWhlRelCalib_An_Sns, filter=data-filter-type=ALWAYS, init-value=0}, required-interface=Ford_SteWhlRelCalib_An_Sns
      Ford_TrlrAidCancl_B_Rq: nonqueued-receiver-com-spec{data-element=Ford_TrlrAidCancl_B_Rq, filter=data-filter-type=ALWAYS, init-value=0}, required-interface=Ford_TrlrAidCancl_B_Rq
      Ford_TrlrAidCtl_U_RqDrv: nonqueued-receiver-com-spec{data-element=Ford_TrlrAidCtl_U_RqDrv, filter=data-filter-type=ALWAYS, init-value=4094}, required-interface=Ford_TrlrAidCtl_U_RqDrv
      Ford_TrlrAidSwtch_D_RqDrv: nonqueued-receiver-com-spec{data-element=Ford_TrlrAidSwtch_D_RqDrv, filter=data-filter-type=ALWAYS, init-value=0}, required-interface=Ford_TrlrAidSwtch_D_RqDrv
      Ford_TrlrAnOffstDir_D_Mem: nonqueued-receiver-com-spec{data-element=Ford_TrlrAnOffstDir_D_Mem, filter=data-filter-type=ALWAYS, init-value=0}, required-interface=Ford_TrlrAnOffstDir_D_Mem
      Ford_TrlrAxleToBmpr_L_Actl: nonqueued-receiver-com-spec{data-element=Ford_TrlrAxleToBmpr_L_Actl, filter=data-filter-type=ALWAYS, init-value=0}, required-interface=Ford_TrlrAxleToBmpr_L_Actl
      Ford_TrlrBrkActCnnct_B_Actl: nonqueued-receiver-com-spec{data-element=Ford_TrlrBrkActCnnct_B_Actl, filter=data-filter-type=ALWAYS, init-value=0}, required-interface=Ford_TrlrBrkActCnnct_B_Actl
      Ford_TrlrId_No_Actl: nonqueued-receiver-com-spec{data-element=Ford_TrlrId_No_Actl, filter=data-filter-type=ALWAYS, init-value=0}, required-interface=Ford_TrlrId_No_Actl
      Ford_TrlrLampCnnct_B_Actl: nonqueued-receiver-com-spec{data-element=Ford_TrlrLampCnnct_B_Actl, filter=data-filter-type=ALWAYS, init-value=0}, required-interface=Ford_TrlrLampCnnct_B_Actl
      Ford_TrlrTrgtAcquire_D_Stat: nonqueued-receiver-com-spec{data-element=Ford_TrlrTrgtAcquire_D_Stat, filter=data-filter-type=ALWAYS, init-value=0}, required-interface=Ford_TrlrTrgtAcquire_D_Stat
      Ford_TrnRng_D_Rq: nonqueued-receiver-com-spec{data-element=Ford_TrnRng_D_Rq, filter=data-filter-type=ALWAYS, init-value=14}, required-interface=Ford_TrnRng_D_Rq
      Ford_TurnLghtSwtch_D_Stat: nonqueued-receiver-com-spec{data-element=Ford_TurnLghtSwtch_D_Stat, filter=data-filter-type=ALWAYS, init-value=0}, required-interface=Ford_TurnLghtSwtch_D_Stat
      Ford_Veh_V_ActlBrk: nonqueued-receiver-com-spec{data-element=Ford_Veh_V_ActlBrk, filter=data-filter-type=ALWAYS, init-value=0}, required-interface=Ford_Veh_V_ActlBrk
      Ford_Veh_V_ActlEng: nonqueued-receiver-com-spec{data-element=Ford_Veh_V_ActlEng, filter=data-filter-type=ALWAYS, init-value=0}, required-interface=Ford_Veh_V_ActlEng
      Ford_VehicleGGCCData: nonqueued-receiver-com-spec{data-element=Ford_VehicleGGCCData, filter=data-filter-type=ALWAYS}, required-interface=Ford_VehicleGGCCData
      Ford_VehLatComp_A_Actl: nonqueued-receiver-com-spec{data-element=Ford_VehLatComp_A_Actl, filter=data-filter-type=ALWAYS, init-value=1022}, required-interface=Ford_VehLatComp_A_Actl
      Ford_VehLongComp_A_Actl: nonqueued-receiver-com-spec{data-element=Ford_VehLongComp_A_Actl, filter=data-filter-type=ALWAYS, init-value=1022}, required-interface=Ford_VehLongComp_A_Actl
      Ford_VehOverGnd_V_Est: nonqueued-receiver-com-spec{data-element=Ford_VehOverGnd_V_Est, filter=data-filter-type=ALWAYS, init-value=0}, required-interface=Ford_VehOverGnd_V_Est
      Ford_VehVActlBrk_D_Qf: nonqueued-receiver-com-spec{data-element=Ford_VehVActlBrk_D_Qf, filter=data-filter-type=ALWAYS, init-value=0}, required-interface=Ford_VehVActlBrk_D_Qf
      Ford_VehVActlBrk_No_Cnt: nonqueued-receiver-com-spec{data-element=Ford_VehVActlBrk_No_Cnt, filter=data-filter-type=ALWAYS, init-value=0}, required-interface=Ford_VehVActlBrk_No_Cnt
      Ford_VehVActlBrk_No_Cs: nonqueued-receiver-com-spec{data-element=Ford_VehVActlBrk_No_Cs, filter=data-filter-type=ALWAYS, init-value=0}, required-interface=Ford_VehVActlBrk_No_Cs
      Ford_VehVActlEng_D_Qf: nonqueued-receiver-com-spec{data-element=Ford_VehVActlEng_D_Qf, filter=data-filter-type=ALWAYS, init-value=0}, required-interface=Ford_VehVActlEng_D_Qf
      Ford_VehVActlEng_No_Cnt: nonqueued-receiver-com-spec{data-element=Ford_VehVActlEng_No_Cnt, filter=data-filter-type=ALWAYS, init-value=0}, required-interface=Ford_VehVActlEng_No_Cnt
      Ford_VehVActlEng_No_Cs: nonqueued-receiver-com-spec{data-element=Ford_VehVActlEng_No_Cs, filter=data-filter-type=ALWAYS, init-value=0}, required-interface=Ford_VehVActlEng_No_Cs
      Ford_VehVertComp_A_Actl: nonqueued-receiver-com-spec{data-element=Ford_VehVertComp_A_Actl, filter=data-filter-type=ALWAYS, init-value=1022}, required-interface=Ford_VehVertComp_A_Actl
      Ford_VehVTrlrAid_B_Avail: nonqueued-receiver-com-spec{data-element=Ford_VehVTrlrAid_B_Avail, filter=data-filter-type=ALWAYS, init-value=0}, required-interface=Ford_VehVTrlrAid_B_Avail
      Ford_VehYawComp_W_Actl: nonqueued-receiver-com-spec{data-element=Ford_VehYawComp_W_Actl, filter=data-filter-type=ALWAYS, init-value=4094}, required-interface=Ford_VehYawComp_W_Actl
      Ford_WhlDirFl_D_Actl: nonqueued-receiver-com-spec{data-element=Ford_WhlDirFl_D_Actl, filter=data-filter-type=ALWAYS, init-value=0}, required-interface=Ford_WhlDirFl_D_Actl
      Ford_WhlDirFr_D_Actl: nonqueued-receiver-com-spec{data-element=Ford_WhlDirFr_D_Actl, filter=data-filter-type=ALWAYS, init-value=0}, required-interface=Ford_WhlDirFr_D_Actl
      Ford_WhlDirRl_D_Actl: nonqueued-receiver-com-spec{data-element=Ford_WhlDirRl_D_Actl, filter=data-filter-type=ALWAYS, init-value=0}, required-interface=Ford_WhlDirRl_D_Actl
      Ford_WhlDirRr_D_Actl: nonqueued-receiver-com-spec{data-element=Ford_WhlDirRr_D_Actl, filter=data-filter-type=ALWAYS, init-value=0}, required-interface=Ford_WhlDirRr_D_Actl
      Ford_WhlFl_W_Meas: nonqueued-receiver-com-spec{data-element=Ford_WhlFl_W_Meas, filter=data-filter-type=ALWAYS, init-value=0}, required-interface=Ford_WhlFl_W_Meas
      Ford_WhlFr_W_Meas: nonqueued-receiver-com-spec{data-element=Ford_WhlFr_W_Meas, filter=data-filter-type=ALWAYS, init-value=0}, required-interface=Ford_WhlFr_W_Meas
      Ford_WhlRl_W_Meas: nonqueued-receiver-com-spec{data-element=Ford_WhlRl_W_Meas, filter=data-filter-type=ALWAYS, init-value=0}, required-interface=Ford_WhlRl_W_Meas
      Ford_WhlRotatFl_No_Cnt: nonqueued-receiver-com-spec{data-element=Ford_WhlRotatFl_No_Cnt, filter=data-filter-type=ALWAYS, init-value=0}, required-interface=Ford_WhlRotatFl_No_Cnt
      Ford_WhlRotatFr_No_Cnt: nonqueued-receiver-com-spec{data-element=Ford_WhlRotatFr_No_Cnt, filter=data-filter-type=ALWAYS, init-value=0}, required-interface=Ford_WhlRotatFr_No_Cnt
      Ford_WhlRotatRl_No_Cnt: nonqueued-receiver-com-spec{data-element=Ford_WhlRotatRl_No_Cnt, filter=data-filter-type=ALWAYS, init-value=0}, required-interface=Ford_WhlRotatRl_No_Cnt
      Ford_WhlRotatRr_No_Cnt: nonqueued-receiver-com-spec{data-element=Ford_WhlRotatRr_No_Cnt, filter=data-filter-type=ALWAYS, init-value=0}, required-interface=Ford_WhlRotatRr_No_Cnt
      Ford_WhlRr_W_Meas: nonqueued-receiver-com-spec{data-element=Ford_WhlRr_W_Meas, filter=data-filter-type=ALWAYS, init-value=0}, required-interface=Ford_WhlRr_W_Meas
      Ford_YawStabilityIndex: nonqueued-receiver-com-spec{data-element=Ford_YawStabilityIndex, filter=data-filter-type=ALWAYS, init-value=256}, required-interface=Ford_YawStabilityIndex
    11 x provide port:
      Ford_HitchToTrlrAxle_L_Calc: nonqueued-sender-com-spec{data-element=Ford_HitchToTrlrAxle_L_Calc, init-value=0}, provided-interface=Ford_HitchToTrlrAxle_L_Calc
      Ford_LsmcBrk_Tq_Rq: nonqueued-sender-com-spec{data-element=Ford_LsmcBrk_Tq_Rq, init-value=0}, provided-interface=Ford_LsmcBrk_Tq_Rq
      Ford_TrlrAidEnbl_D2_Stat: nonqueued-sender-com-spec{data-element=Ford_TrlrAidEnbl_D2_Stat, init-value=0}, provided-interface=Ford_TrlrAidEnbl_D2_Stat
      Ford_TrlrAidMsgTxt_D2_Rq: nonqueued-sender-com-spec{data-element=Ford_TrlrAidMsgTxt_D2_Rq, init-value=0}, provided-interface=Ford_TrlrAidMsgTxt_D2_Rq
      Ford_TrlrAidSetup_D2_Stat: nonqueued-sender-com-spec{data-element=Ford_TrlrAidSetup_D2_Stat, init-value=0}, provided-interface=Ford_TrlrAidSetup_D2_Stat
      Ford_TrlrAidTrgtId_No_Rq: nonqueued-sender-com-spec{data-element=Ford_TrlrAidTrgtId_No_Rq, init-value=0}, provided-interface=Ford_TrlrAidTrgtId_No_Rq
      Ford_TrlrAidTrlrId_No_Rq: nonqueued-sender-com-spec{data-element=Ford_TrlrAidTrlrId_No_Rq, init-value=0}, provided-interface=Ford_TrlrAidTrlrId_No_Rq
      Ford_TrlrAn_An_MxCalc: nonqueued-sender-com-spec{data-element=Ford_TrlrAn_An_MxCalc, init-value=0}, provided-interface=Ford_TrlrAn_An_MxCalc
      Ford_TrlrAn_An_TrgtCalc: nonqueued-sender-com-spec{data-element=Ford_TrlrAn_An_TrgtCalc, init-value=128}, provided-interface=Ford_TrlrAn_An_TrgtCalc
      Ford_TrlrAn_An_WarnCalc: nonqueued-sender-com-spec{data-element=Ford_TrlrAn_An_WarnCalc, init-value=0}, provided-interface=Ford_TrlrAn_An_WarnCalc
      Ford_TrlrAnOffst_An2_Calc: nonqueued-sender-com-spec{data-element=Ford_TrlrAnOffst_An2_Calc, init-value=128}, provided-interface=Ford_TrlrAnOffst_An2_Calc
    31 x require port:
      Ford_ApaSys_D_Stat: nonqueued-receiver-com-spec{data-element=Ford_ApaSys_D_Stat, filter=data-filter-type=ALWAYS, init-value=0}, required-interface=Ford_ApaSys_D_Stat
      Ford_GearPos_D_Actl: nonqueued-receiver-com-spec{data-element=Ford_GearPos_D_Actl, filter=data-filter-type=ALWAYS, init-value=15}, required-interface=Ford_GearPos_D_Actl
      Ford_HitchToVehAxle_L_Calc: nonqueued-receiver-com-spec{data-element=Ford_HitchToVehAxle_L_Calc, filter=data-filter-type=ALWAYS, init-value=255}, required-interface=Ford_HitchToVehAxle_L_Calc
      Ford_LatCtlRng_L_Max: nonqueued-receiver-com-spec{data-element=Ford_LatCtlRng_L_Max, filter=data-filter-type=ALWAYS, init-value=0}, required-interface=Ford_LatCtlRng_L_Max
      Ford_LifeCycMde_D_Actl: nonqueued-receiver-com-spec{data-element=Ford_LifeCycMde_D_Actl, filter=data-filter-type=ALWAYS, init-value=0}, required-interface=Ford_LifeCycMde_D_Actl
      Ford_LkaDrvOvrrd_D_Rq: nonqueued-receiver-com-spec{data-element=Ford_LkaDrvOvrrd_D_Rq, filter=data-filter-type=ALWAYS, init-value=0}, required-interface=Ford_LkaDrvOvrrd_D_Rq
      Ford_SelDrvMdeChassis2_D_Rq: nonqueued-receiver-com-spec{data-element=Ford_SelDrvMdeChassis2_D_Rq, filter=data-filter-type=ALWAYS, init-value=0}, required-interface=Ford_SelDrvMdeChassis2_D_Rq
      Ford_StePinOffst_No_Cnt: nonqueued-receiver-com-spec{data-element=Ford_StePinOffst_No_Cnt, filter=data-filter-type=ALWAYS, init-value=0}, required-interface=Ford_StePinOffst_No_Cnt
      Ford_StePinOffst_No_Cs: nonqueued-receiver-com-spec{data-element=Ford_StePinOffst_No_Cs, filter=data-filter-type=ALWAYS, init-value=0}, required-interface=Ford_StePinOffst_No_Cs
      Ford_TrlrAid_An3_Actl: nonqueued-receiver-com-spec{data-element=Ford_TrlrAid_An3_Actl, filter=data-filter-type=ALWAYS, init-value=720}, required-interface=Ford_TrlrAid_An3_Actl
      Ford_TrlrAid_AnRate2_Actl: nonqueued-receiver-com-spec{data-element=Ford_TrlrAid_AnRate2_Actl, filter=data-filter-type=ALWAYS, init-value=400}, required-interface=Ford_TrlrAid_AnRate2_Actl
      Ford_TrlrAid_D2_Stat: nonqueued-receiver-com-spec{data-element=Ford_TrlrAid_D2_Stat, filter=data-filter-type=ALWAYS, init-value=0}, required-interface=Ford_TrlrAid_D2_Stat
      Ford_TrlrAidEnbl_D2_Rq: nonqueued-receiver-com-spec{data-element=Ford_TrlrAidEnbl_D2_Rq, filter=data-filter-type=ALWAYS, init-value=0}, required-interface=Ford_TrlrAidEnbl_D2_Rq
      Ford_TrlrAidMde_D_Rq: nonqueued-receiver-com-spec{data-element=Ford_TrlrAidMde_D_Rq, filter=data-filter-type=ALWAYS, init-value=0}, required-interface=Ford_TrlrAidMde_D_Rq
      Ford_TrlrAidSetup_D2_Rq: nonqueued-receiver-com-spec{data-element=Ford_TrlrAidSetup_D2_Rq, filter=data-filter-type=ALWAYS, init-value=0}, required-interface=Ford_TrlrAidSetup_D2_Rq
      Ford_TrlrAidTrgtId_No_Actl: nonqueued-receiver-com-spec{data-element=Ford_TrlrAidTrgtId_No_Actl, filter=data-filter-type=ALWAYS, init-value=0}, required-interface=Ford_TrlrAidTrgtId_No_Actl
      Ford_TrlrHitchYaw_An_Actl: nonqueued-receiver-com-spec{data-element=Ford_TrlrHitchYaw_An_Actl, filter=data-filter-type=ALWAYS, init-value=4094}, required-interface=Ford_TrlrHitchYaw_An_Actl
      Ford_TrlrHitchYaw_D_Stat: nonqueued-receiver-com-spec{data-element=Ford_TrlrHitchYaw_D_Stat, filter=data-filter-type=ALWAYS, init-value=0}, required-interface=Ford_TrlrHitchYaw_D_Stat
      Ford_TrlrHitYaw_AnRate_Actl: nonqueued-receiver-com-spec{data-element=Ford_TrlrHitYaw_AnRate_Actl, filter=data-filter-type=ALWAYS, init-value=4094}, required-interface=Ford_TrlrHitYaw_AnRate_Actl
      Ford_TrlrIdType_D_Stat: nonqueued-receiver-com-spec{data-element=Ford_TrlrIdType_D_Stat, filter=data-filter-type=ALWAYS, init-value=0}, required-interface=Ford_TrlrIdType_D_Stat
      Ford_TrlrRvrse_D_Stat: nonqueued-receiver-com-spec{data-element=Ford_TrlrRvrse_D_Stat, filter=data-filter-type=ALWAYS, init-value=0}, required-interface=Ford_TrlrRvrse_D_Stat
      Ford_TrlrRvrseCancl_B_Rq: nonqueued-receiver-com-spec{data-element=Ford_TrlrRvrseCancl_B_Rq, filter=data-filter-type=ALWAYS, init-value=0}, required-interface=Ford_TrlrRvrseCancl_B_Rq
      Ford_TrlrRvrseEnbl_D2_Stat: nonqueued-receiver-com-spec{data-element=Ford_TrlrRvrseEnbl_D2_Stat, filter=data-filter-type=ALWAYS, init-value=0}, required-interface=Ford_TrlrRvrseEnbl_D2_Stat
      Ford_TrlrRvrseMsgTxt_D2_Rq: nonqueued-receiver-com-spec{data-element=Ford_TrlrRvrseMsgTxt_D2_Rq, filter=data-filter-type=ALWAYS, init-value=0}, required-interface=Ford_TrlrRvrseMsgTxt_D2_Rq
      Ford_TrlrSnsId_No_Actl: nonqueued-receiver-com-spec{data-element=Ford_TrlrSnsId_No_Actl, filter=data-filter-type=ALWAYS}, required-interface=Ford_TrlrSnsId_No_Actl
      Ford_TrlrYaw_W_Actl: nonqueued-receiver-com-spec{data-element=Ford_TrlrYaw_W_Actl, filter=data-filter-type=ALWAYS, init-value=65534}, required-interface=Ford_TrlrYaw_W_Actl
      Ford_TrlrYawWActl_D_Qf: nonqueued-receiver-com-spec{data-element=Ford_TrlrYawWActl_D_Qf, filter=data-filter-type=ALWAYS, init-value=1}, required-interface=Ford_TrlrYawWActl_D_Qf
      Ford_FileVersionDay: nonqueued-receiver-com-spec{data-element=Ford_FileVersionDay, filter=data-filter-type=ALWAYS, init-value=48}, required-interface=Ford_FileVersionDay
      Ford_FileVersionMonth: nonqueued-receiver-com-spec{data-element=Ford_FileVersionMonth, filter=data-filter-type=ALWAYS, init-value=17}, required-interface=Ford_FileVersionMonth
      Ford_FileVersionYear: nonqueued-receiver-com-spec{data-element=Ford_FileVersionYear, filter=data-filter-type=ALWAYS, init-value=23}, required-interface=Ford_FileVersionYear
      Ford_VehYaw_W_Actl: required-interface=Ford_VehYaw_W_Actl
    provide port Ford_EsaOn_B_Stat: provided-interface=Ford_EsaOn_B_Stat
    219 x component:
      BswM: type=BswM
      CDD_ChkPtAppl10: type=CDD_ChkPtAppl10
      ComM: type=ComM
      Dem: type=Dem
      Det: type=Det
      EcuM: type=EcuM
      NvM: type=NvM
      Dcm: type=Dcm
      Os_OsCore_CORE0_swc: type=Os_OsCore_CORE0_swc
      WdgM_Appl10: type=WdgM_Appl10
      NxtrMath: type=NxtrMath
      CDD_NvMProxy: type=CDD_NvMProxy
      NvMProxy: type=NvMProxy
      DiagcMgrStub: type=DiagcMgrStub
      DiagcMgrProxyAppl10: type=DiagcMgrProxyAppl10
      DiagcMgr: type=DiagcMgr
      CalRegn01CmnGroupA: type=CalRegn01CmnGroupA
      SysStMod: type=SysStMod
      PwrUpSeq: type=PwrUpSeq
      ShtdwnMech: type=ShtdwnMech
      CDD_FordT3T6McuCfg: type=CDD_FordT3T6McuCfg
      IoHwAb: type=IoHwAb
      PolarityCfg: type=PolarityCfg
      MotAgCorrln: type=MotAgCorrln
      MotAg2Meas: type=MotAg2Meas
      CDD_MotAgCmp: type=CDD_MotAgCmp
      CDD_MotAgArbn: type=CDD_MotAgArbn
      FltInj: type=FltInj
      VehSigCdng: type=VehSigCdng
      CDD_MotVel: type=CDD_MotVel
      CalRegn01Inin00GroupA: type=CalRegn01Inin00GroupA
      CurrMeasCorrln: type=CurrMeasCorrln
      CDD_CurrMeasArbn: type=CDD_CurrMeasArbn
      CDD_CurrMeas: type=CDD_CurrMeas
      DualEcuIdn: type=DualEcuIdn
      BattVltgCorrln: type=BattVltgCorrln
      BattVltg: type=BattVltg
      MotQuadDetn: type=MotQuadDetn
      MotCtrlPrmEstimn: type=MotCtrlPrmEstimn
      HwAgSysArbn: type=HwAgSysArbn
      HwAgSnsrls: type=HwAgSnsrls
      CDD_DmaCfgAndUse: type=CDD_DmaCfgAndUse
      CDD_Adcf0CfgAndUse: type=CDD_Adcf0CfgAndUse
      Adcf1CfgAndUse: type=Adcf1CfgAndUse
      PwrDiscnct: type=PwrDiscnct
      StabyCmp: type=StabyCmp
      RtnPahFwl: type=RtnPahFwl
      Rtn: type=Rtn
      InertiaCmpVel: type=InertiaCmpVel
      DampgPahSum: type=DampgPahSum
      Dampg: type=Dampg
      AssiSumLim: type=AssiSumLim
      AssiPahSum: type=AssiPahSum
      AssiHiFrq: type=AssiHiFrq
      Assi: type=Assi
      VehSpdLimr: type=VehSpdLimr
      TqLoa: type=TqLoa
      HysCmp: type=HysCmp
      EotProtn: type=EotProtn
      EotLrng: type=EotLrng
      SysPrfmncSts: type=SysPrfmncSts
      SysFricLrng: type=SysFricLrng
      PosnTrakgServo: type=PosnTrakgServo
      MotRplCoggCfg: type=MotRplCoggCfg
      DrvrTqEstimn: type=DrvrTqEstimn
      CmplncErr: type=CmplncErr
      CDD_MotRplCoggCmd: type=CDD_MotRplCoggCmd
      CDD_MotCtrlMgr: type=CDD_MotCtrlMgr
      Swp: type=Swp
      StOutpCtrl: type=StOutpCtrl
      CDD_NxtrTi: type=CDD_NxtrTi
      TunSelnAuthy: type=TunSelnAuthy
      CDD_VrfyCritReg: type=CDD_VrfyCritReg
      HwAg1Meas: type=HwAg1Meas
      CDD_McuDiagc: type=CDD_McuDiagc
      MotRefMdl: type=MotRefMdl
      MotCurrRegCfg: type=MotCurrRegCfg
      MotCurrPeakEstimn: type=MotCurrPeakEstimn
      CDD_MotCurrRegVltgLimr: type=CDD_MotCurrRegVltgLimr
      TmplMonr: type=TmplMonr
      PwrSply: type=PwrSply
      GateDrv0Ctrl: type=GateDrv0Ctrl
      CDD_MotAg6Meas: type=CDD_MotAg6Meas
      CDD_MotAg5Meas: type=CDD_MotAg5Meas
      HwTqCorrln: type=HwTqCorrln
      HwTqArbn: type=HwTqArbn
      TEstimn: type=TEstimn
      PwrLimr: type=PwrLimr
      LimrCdng: type=LimrCdng
      HiLoadStallLimr: type=HiLoadStallLimr
      EotProtnFwl: type=EotProtnFwl
      DutyCycThermProtn: type=DutyCycThermProtn
      MotTqTranlDampg: type=MotTqTranlDampg
      MotTqCmdSca: type=MotTqCmdSca
      CmnMfgSrv: type=CmnMfgSrv
      DiagSrv: type=DiagSrv
      TunSelnMngt: type=TunSelnMngt
      NxtrSwIds: type=NxtrSwIds
      CDD_XcpIf: type=CDD_XcpIf
      ImcSigArbn: type=ImcSigArbn
      ImcArbn: type=ImcArbn
      CDD_Uart1CfgAndUse: type=CDD_Uart1CfgAndUse
      CDD_Uart0CfgAndUse: type=CDD_Uart0CfgAndUse
      CDD_SinVltgGenn: type=CDD_SinVltgGenn
      LoaMgr: type=LoaMgr
      HwAgCorrln: type=HwAgCorrln
      HwAgArbn: type=HwAgArbn
      ElecPwrCns: type=ElecPwrCns
      DualCtrlrOutpMgr: type=DualCtrlrOutpMgr
      EcuTMeas: type=EcuTMeas
      CDD_MotAgSwCal: type=CDD_MotAgSwCal
      CDD_HwTq1Meas: type=CDD_HwTq1Meas
      MotVelCtrl: type=MotVelCtrl
      CDD_HwTq8Meas: type=CDD_HwTq8Meas
      CDD_GtmCfgAndUse: type=CDD_GtmCfgAndUse
      FordMsg5B5BusHiSpd: type=FordMsg5B5BusHiSpd
      FordMsg430BusHiSpd: type=FordMsg430BusHiSpd
      FordMsg41EBusHiSpd: type=FordMsg41EBusHiSpd
      FordMsg41ABusHiSpd: type=FordMsg41ABusHiSpd
      FordMsg417BusHiSpd: type=FordMsg417BusHiSpd
      FordMsg415BusHiSpd: type=FordMsg415BusHiSpd
      FordMsg40ABusHiSpd: type=FordMsg40ABusHiSpd
      FordMsg3B3BusHiSpd: type=FordMsg3B3BusHiSpd
      FordMsg217BusHiSpd: type=FordMsg217BusHiSpd
      FordMsg167BusHiSpd: type=FordMsg167BusHiSpd
      FordMsg082BusHiSpd: type=FordMsg082BusHiSpd
      FordMsg07EBusHiSpd: type=FordMsg07EBusHiSpd
      CDD_SyncCrc: type=CDD_SyncCrc
      CDD_RamMem: type=CDD_RamMem
      CDD_McuCoreCfgAndDiagc: type=CDD_McuCoreCfgAndDiagc
      CDD_GuardCfgAndDiagc: type=CDD_GuardCfgAndDiagc
      CDD_FlsMem: type=CDD_FlsMem
      CDD_ExcpnHndlg: type=CDD_ExcpnHndlg
      CDD_EcmOutpAndDiagc: type=CDD_EcmOutpAndDiagc
      CDD_ClkCfgAndMon: type=CDD_ClkCfgAndMon
      FordMsg414BusHiSpd: type=FordMsg414BusHiSpd
      FordMsg202BusHiSpd: type=FordMsg202BusHiSpd
      HwTq9Meas: type=HwTq9Meas
      HwTq10Meas: type=HwTq10Meas
      CustDiag: type=CustDiag
      CalRegn02Rt05GroupA: type=CalRegn02Rt05GroupA
      CalRegn02Rt04GroupA: type=CalRegn02Rt04GroupA
      CalRegn02Rt03GroupA: type=CalRegn02Rt03GroupA
      CalRegn02Rt02GroupA: type=CalRegn02Rt02GroupA
      CalRegn02Rt01GroupA: type=CalRegn02Rt01GroupA
      CalRegn02Rt00GroupA: type=CalRegn02Rt00GroupA
      CalRegn02Inin00GroupA: type=CalRegn02Inin00GroupA
      CalRegn02CmnGroupA: type=CalRegn02CmnGroupA
      AAACalRegn02Rt05GroupA_Dummy: type=AAACalRegn02Rt01GroupA_Dummy
      AAACalRegn02Rt04GroupA_Dummy: type=AAACalRegn02Rt01GroupA_Dummy
      AAACalRegn02Rt03GroupA_Dummy: type=AAACalRegn02Rt01GroupA_Dummy
      AAACalRegn02Rt02GroupA_Dummy: type=AAACalRegn02Rt01GroupA_Dummy
      AAACalRegn02Rt01GroupA_Dummy: type=AAACalRegn02Rt01GroupA_Dummy
      AAACalRegn02Rt00GroupA_Dummy: type=AAACalRegn02Rt01GroupA_Dummy
      FordVltgIf: type=FordVltgIf
      FordVehSpdArbn: type=FordVehSpdArbn
      FordSysSt: type=FordSysSt
      FordHwTqCdng: type=FordHwTqCdng
      FordHwAgArbn: type=FordHwAgArbn
      FordCanDtcInhb: type=FordCanDtcInhb
      NxtrCalIds: type=NxtrCalIds
      StackMeas: type=StackMeas
      FordDualEcuFltDiagcCom: type=FordDualEcuFltDiagcCom
      CDD_CoreVltgMonr: type=CDD_CoreVltgMonr
      CalRegn02Rt05GroupB: type=CalRegn02Rt05GroupB
      CalRegn02Rt04GroupB: type=CalRegn02Rt04GroupB
      CalRegn02Rt03GroupB: type=CalRegn02Rt03GroupB
      CalRegn02Rt02GroupB: type=CalRegn02Rt02GroupB
      CalRegn02Rt01GroupB: type=CalRegn02Rt01GroupB
      CalRegn02Rt00GroupB: type=CalRegn02Rt00GroupB
      CalRegn02Inin00GroupB: type=CalRegn02Inin00GroupB
      CalRegn02Inin00: type=CalRegn02Inin00
      CalRegn02CmnGroupB: type=CalRegn02CmnGroupB
      CalRegn02Cmn: type=CalRegn02Cmn
      CalRegn01Rt05: type=CalRegn01Rt05
      CalRegn01Rt04: type=CalRegn01Rt04
      CalRegn01Rt03: type=CalRegn01Rt03
      CalRegn01Rt02: type=CalRegn01Rt02
      CalRegn01Rt01: type=CalRegn01Rt01
      CalRegn01Rt00: type=CalRegn01Rt00
      CalRegn01Inin00GroupD: type=CalRegn01Inin00GroupD
      CalRegn01Inin00GroupB: type=CalRegn01Inin00GroupB
      CalRegn01Inin00: type=CalRegn01Inin00
      CalRegn01Cmn: type=CalRegn01Cmn
      AAACalRegn02Rt05GroupB_Dummy: type=AAACalRegn02Rt01GroupB_Dummy
      AAACalRegn02Rt04GroupB_Dummy: type=AAACalRegn02Rt01GroupB_Dummy
      AAACalRegn02Rt03GroupB_Dummy: type=AAACalRegn02Rt01GroupB_Dummy
      AAACalRegn02Rt02GroupB_Dummy: type=AAACalRegn02Rt01GroupB_Dummy
      AAACalRegn02Rt01GroupB_Dummy: type=AAACalRegn02Rt01GroupB_Dummy
      AAACalRegn02Rt00GroupB_Dummy: type=AAACalRegn02Rt01GroupB_Dummy
      AAACalRegn01Rt05_Dummy: type=AAACalRegn01Rt01_Dummy
      AAACalRegn01Rt04_Dummy: type=AAACalRegn01Rt01_Dummy
      AAACalRegn01Rt03_Dummy: type=AAACalRegn01Rt01_Dummy
      AAACalRegn01Rt02_Dummy: type=AAACalRegn01Rt01_Dummy
      AAACalRegn01Rt01_Dummy: type=AAACalRegn01Rt01_Dummy
      AAACalRegn01Rt00_Dummy: type=AAACalRegn01Rt01_Dummy
      FordMsg3D3BusHiSpd: type=FordMsg3D3BusHiSpd
      FordMsg213BusHiSpd: type=FordMsg213BusHiSpd
      FordMsg091BusHiSpd: type=FordMsg091BusHiSpd
      FordMsg083BusHiSpd: type=FordMsg083BusHiSpd
      FordMsg443BusHiSpd: type=FordMsg443BusHiSpd
      FordMsg3CCBusHiSpd: type=FordMsg3CCBusHiSpd
      FordMsg3CABusHiSpd: type=FordMsg3CABusHiSpd
      FordMsg07DBusHiSpd: type=FordMsg07DBusHiSpd
      CDD_FordBlaBoxIfCmp2: type=CDD_FordBlaBoxIfCmp2
      CDD_FordBlaBoxIfCmp1: type=CDD_FordBlaBoxIfCmp1
      CDD_FordBlaBoxIfCmn: type=CDD_FordBlaBoxIfCmn
      FordMsg230BusHiSpd: type=FordMsg230BusHiSpd
      FordMsg216BusHiSpd: type=FordMsg216BusHiSpd
      FordMsg47ABusHiSpd: type=FordMsg47ABusHiSpd
      FordMsg459BusHiSpd: type=FordMsg459BusHiSpd
      FordMsg215BusHiSpd: type=FordMsg215BusHiSpd
      FordMsg3D7BusHiSpd: type=FordMsg3D7BusHiSpd
      FordMotTqCmdOvrlLimr: type=FordMotTqCmdOvrlLimr
      FordHwTqCmdOvrlLimr: type=FordHwTqCmdOvrlLimr
      FordCmdArbn: type=FordCmdArbn
      FordMsg2FDBusHiSpd: type=FordMsg2FDBusHiSpd
      FordMsg077BusHiSpd: type=FordMsg077BusHiSpd
      FordMsg4B0BusHiSpd: type=FordMsg4B0BusHiSpd
    connect WdgM_Appl10.alive_SE_100ms_Appl10_ChkPt_100ms_Appl10_End -> CDD_ChkPtAppl10.ChkPt_100ms_Appl10_End
    connect WdgM_Appl10.alive_SE_100ms_Appl10_ChkPt_100ms_Appl10_Strt -> CDD_ChkPtAppl10.ChkPt_100ms_Appl10_Strt
    connect WdgM_Appl10.alive_SE_10ms_Appl10_ChkPt_10ms_Appl10_End -> CDD_ChkPtAppl10.ChkPt_10ms_Appl10_End
    connect WdgM_Appl10.alive_SE_10ms_Appl10_ChkPt_10ms_Appl10_Strt -> CDD_ChkPtAppl10.ChkPt_10ms_Appl10_Strt
    connect WdgM_Appl10.alive_SE_2ms_Appl10_ChkPt_2ms_Appl10_End -> CDD_ChkPtAppl10.ChkPt_2ms_Appl10_End
    connect WdgM_Appl10.alive_SE_2ms_Appl10_ChkPt_2ms_Appl10_Strt -> CDD_ChkPtAppl10.ChkPt_2ms_Appl10_Strt
    connect WdgM_Appl10.alive_SE_4ms_Appl10_ChkPt_4ms_Appl10_End -> CDD_ChkPtAppl10.ChkPt_4ms_Appl10_End
    connect WdgM_Appl10.alive_SE_4ms_Appl10_ChkPt_4ms_Appl10_Strt -> CDD_ChkPtAppl10.ChkPt_4ms_Appl10_Strt
    connect NvMProxy.PSProxy_Rte_NvmBlock_CDD_NvMProxy_ShtdwnClsChk -> CDD_NvMProxy.ShtdwnClsChkBlk
    connect DiagcMgr.ClrDiagcFlgProxy -> DiagcMgrProxyAppl10.ClrDiagcFlgProxy
    connect DiagcMgr.DiagcMgrIninCore -> DiagcMgrProxyAppl10.DiagcMgrIninCore
    connect DiagcMgr.GetNtcActvCore -> DiagcMgrProxyAppl10.GetNtcActvCore
    connect DiagcMgr.GetNtcQlfrStsCore -> DiagcMgrProxyAppl10.GetNtcQlfrStsCore
    connect DiagcMgr.GetNtcStsCore -> DiagcMgrProxyAppl10.GetNtcStsCore
    connect DiagcMgr.SetNtcStsCore -> DiagcMgrProxyAppl10.SetNtcStsCore
    connect DiagcMgrProxyAppl10.SetNtcSts10 -> CDD_NvMProxy.SetNtcSts
    connect DiagcMgrProxyAppl10.GetDiagcDataAppl10 -> DiagcMgr.GetDiagcDataAppl10
    connect DiagcMgrProxyAppl10.GetNtcDebCntrAppl10 -> DiagcMgr.GetNtcDebCntrAppl10
    connect DiagcMgrProxyAppl10.GetNtcInfoAppl10 -> DiagcMgr.GetNtcInfoAppl10
    connect DiagcMgrProxyAppl10.SetNtcSts10 -> NxtrMath.SetNtcSts
    connect DiagcMgrStub.GetDiagcDataStub -> DiagcMgr.GetDiagcDataAppl{0..9}
    connect DiagcMgrStub.GetNtcDebCntrStub -> DiagcMgr.GetNtcDebCntrAppl{0..9}
    connect DiagcMgrStub.GetNtcInfoStub -> DiagcMgr.GetNtcInfoAppl{0..9}
    connect NvMProxy.PSProxy_Rte_NvmBlock_DiagcMgr_DiagcMgrLtchCntrAry -> DiagcMgr.DiagcMgrLtchCntrAry
    connect NvMProxy.PSProxy_Rte_NvmBlock_DiagcMgr_DiagcMgrNtcFltAry -> DiagcMgr.DiagcMgrNtcFltAry
    connect NvMProxy.PSProxy_SnpshtDataAry -> DiagcMgr.SnpshtDataAry
    connect DiagcMgrProxyAppl10.SetNtcSts10 -> DiagcMgr.SetNtcSts
    connect DiagcMgr.SysStFltOutpReqDi -> SysStMod.SysStFltOutpReqDi
    connect PwrUpSeq.StrtUpSt -> SysStMod.StrtUpSt
    connect PwrUpSeq.SysStWrmIninCmpl -> SysStMod.SysStWrmIninCmpl
    connect SysStMod.SysSt -> PwrUpSeq.SysSt
    connect PwrUpSeq.StrtUpSt -> ShtdwnMech.StrtUpSt
    connect IoHwAb.SetGpioPwrTurnOffCtrl -> PwrUpSeq.IoHwAb_SetGpioPwrTurnOffCtrl
    connect IoHwAb.SetGpioSysFlt2A -> ShtdwnMech.IoHwAb_SetGpioSysFlt2A
    connect CDD_FordT3T6McuCfg.MotAg2Cos -> MotAg2Meas.MotAg2Cos
    connect CDD_FordT3T6McuCfg.MotAg2CosAdcFaild -> MotAg2Meas.MotAg2CosAdcFaild
    connect CDD_FordT3T6McuCfg.MotAg2Sin -> MotAg2Meas.MotAg2Sin
    connect CDD_FordT3T6McuCfg.MotAg2SinAdcFaild -> MotAg2Meas.MotAg2SinAdcFaild
    connect DiagcMgrProxyAppl10.GetNtcQlfrSts10 -> MotAg2Meas.GetNtcQlfrSts
    connect DiagcMgrProxyAppl10.SetNtcSts10 -> MotAg2Meas.SetNtcSts
    connect DiagcMgrProxyAppl10.GetNtcQlfrSts10 -> MotAgCorrln.GetNtcQlfrSts
    connect DiagcMgrProxyAppl10.SetNtcSts10 -> MotAgCorrln.SetNtcSts
    connect MotAg2Meas.MotAg2Mecl -> MotAgCorrln.MotAgCMecl
    connect MotAg2Meas.MotAg2MeclQlfr -> MotAgCorrln.MotAgCMeclQlfr
    connect MotAg2Meas.MotAg2MeclRollgCntr -> MotAgCorrln.MotAgCMeclRollgCntr
    connect PolarityCfg.AssiMechPolarity -> CDD_MotAgCmp.AssiMechPolarity
    connect PolarityCfg.MotAgMecl2Polarity -> MotAg2Meas.MotAgMecl2Polarity
    connect NvMProxy.PSProxy_Rte_NvmBlock_PolarityCfg_PolarityCfgSaved -> PolarityCfg.PolarityCfgSaved
    connect FltInj.FltInj_f32 -> MotAg2Meas.FltInj_f32
    connect FltInj.FltInj_u08 -> MotAgCorrln.FltInj_u08
    connect FltInj.FltInj_f32 -> VehSigCdng.FltInj_f32
    connect PolarityCfg.AssiMechPolarity -> CDD_MotVel.AssiMechPolarity
    connect CDD_CurrMeas.MotCurrEolCalSt -> CurrMeasCorrln.MotCurrEolCalSt
    connect CDD_CurrMeas.CurrMeasWrmIninTestCmpl -> PwrUpSeq.CurrMeasWrmIninTestCmpl
    connect CDD_MotVel.MotVelMrf -> CDD_CurrMeas.MotVelMrf
    connect DiagcMgrProxyAppl10.GetNtcQlfrSts10 -> CDD_CurrMeas.GetNtcQlfrSts
    connect DiagcMgrProxyAppl10.SetNtcSts10 -> CDD_CurrMeas.SetNtcSts
    connect FltInj.FltInj_f32 -> CDD_CurrMeas.FltInj_f32
    connect FltInj.FltInj_u08 -> CDD_CurrMeas.FltInj_u08
    connect FltInj.FltInj_u08 -> CurrMeasCorrln.FltInj_u08
    connect PwrUpSeq.StrtUpSt -> CDD_CurrMeas.StrtUpSt
    connect SysStMod.SysSt -> CDD_CurrMeas.SysSt
    connect SysStMod.SysSt -> CurrMeasCorrln.SysSt
    connect VehSigCdng.VehSpdVld -> CDD_CurrMeas.VehSpdVld
    connect DiagcMgrProxyAppl10.GetNtcQlfrSts10 -> CurrMeasCorrln.GetNtcQlfrSts
    connect DiagcMgrProxyAppl10.SetNtcSts10 -> CurrMeasCorrln.SetNtcSts
    connect BattVltg.BrdgVltg -> CDD_CurrMeas.BrdgVltg
    connect BattVltg.BrdgVltg -> DiagcMgr.BrdgVltg
    connect BattVltgCorrln.BattSwdVltgCorrlnSts -> BattVltg.BattSwdVltgCorrlnSts
    connect CDD_FordT3T6McuCfg.BattVltg -> BattVltg.BattVltg
    connect CDD_FordT3T6McuCfg.BattVltgSwd1 -> BattVltg.BattVltgSwd1
    connect CDD_FordT3T6McuCfg.BattVltg -> BattVltgCorrln.BattVltg
    connect CDD_FordT3T6McuCfg.BattVltgAdcFaild -> BattVltgCorrln.BattVltgAdcFaild
    connect CDD_FordT3T6McuCfg.BattVltgSwd1 -> BattVltgCorrln.BattVltgSwd1
    connect CDD_FordT3T6McuCfg.BattVltgSwd1AdcFaild -> BattVltgCorrln.BattVltgSwd1AdcFaild
    connect DiagcMgrProxyAppl10.GetNtcQlfrSts10 -> BattVltgCorrln.GetNtcQlfrSts
    connect DiagcMgrProxyAppl10.SetNtcSts10 -> BattVltgCorrln.SetNtcSts
    connect DiagcMgrProxyAppl10.SetNtcSts10 -> DualEcuIdn.SetNtcSts
    connect DualEcuIdn.EcuId -> CDD_FordT3T6McuCfg.EcuId
    connect IoHwAb.GetGpioEcuIdnPin1 -> DualEcuIdn.IoHwAb_GetGpioEcuIdnPin1
    connect IoHwAb.GetGpioEcuIdnPin2 -> DualEcuIdn.IoHwAb_GetGpioEcuIdnPin2
    connect PwrUpSeq.StrtUpSt -> BattVltgCorrln.StrtUpSt
    connect SysStMod.SysSt -> BattVltgCorrln.SysSt
    connect CDD_MotAgCmp.MotAgCumvAlgndCrf -> HwAgSnsrls.MotAgCumvAlgndCrf
    connect CDD_MotAgCmp.MotAgCumvAlgndVld -> HwAgSnsrls.MotAgCumvAlgndVld
    connect CDD_MotAgCmp.MotAgCumvAlgndMrf -> MotQuadDetn.MotAgCumvAlgndMrf
    connect DiagcMgrProxyAppl10.GetNtcQlfrSts10 -> HwAgSnsrls.GetNtcQlfrSts
    connect DiagcMgrProxyAppl10.SetNtcSts10 -> HwAgSysArbn.SetNtcSts
    connect FltInj.FltInj_f32 -> HwAgSysArbn.FltInj_f32
    connect HwAgSnsrls.HwAgSnsrls -> HwAgSysArbn.HwAgSnsrls
    connect HwAgSnsrls.HwAgSnsrlsConf -> HwAgSysArbn.HwAgSnsrlsConf
    connect HwAgSysArbn.HwVel -> FltInj.HwVel
    connect HwAgSysArbn.PinionAg -> HwAgSnsrls.PinionAg
    connect HwAgSysArbn.PinionAgConf -> HwAgSnsrls.PinionAgConf
    connect VehSigCdng.VehSpdVld -> HwAgSnsrls.VehSpdVld
    connect VehSigCdng.VehYawRate -> HwAgSnsrls.VehYawRate
    connect NvMProxy.PSProxy_Rte_NvmBlock_CDD_CurrMeas_CurrMeasEolGainCalSetABC -> CDD_CurrMeas.CurrMeasEolGainCalSetABC
    connect NvMProxy.PSProxy_Rte_NvmBlock_CDD_CurrMeas_CurrMeasEolOffsCalSetABC -> CDD_CurrMeas.CurrMeasEolOffsCalSetABC
    connect NvMProxy.PSProxy_Rte_NvmBlock_CDD_MotAgCmp_MotAgCmpMotAgBackEmf -> CDD_MotAgCmp.MotAgCmpMotAgBackEmf
    connect NvMProxy.PSProxy_Rte_NvmBlock_HwAgSnsrls_StordLstPrm -> HwAgSnsrls.NvmStordLstPrm
    connect NvMProxy.PSProxy_Rte_NvmBlock_MotAg2Meas_MotAg2EolPrm -> MotAg2Meas.MotAg2EolPrm
    connect Adcf1CfgAndUse.Adcf1EnaCnvn -> CDD_DmaCfgAndUse.Adc1CfgAndUseAdc1EnaCnvn
    connect DiagcMgr.CnvSnpshtData_f32 -> PwrDiscnct.CnvSnpshtData_f32
    connect DiagcMgrProxyAppl10.SetNtcStsAndSnpshtData10 -> PwrDiscnct.SetNtcStsAndSnpshtData
    connect PwrDiscnct.PwrDiscnctATestCmpl -> PwrUpSeq.PwrDiscnctATestCmpl
    connect PwrDiscnct.PwrDiscnctBTestCmpl -> PwrUpSeq.PwrDiscnctBTestCmpl
    connect PwrUpSeq.StrtUpSt -> PwrDiscnct.StrtUpSt
    connect SysStMod.SysSt -> PwrDiscnct.SysSt
    connect CDD_FordT3T6McuCfg.BattVltgAdcFaild -> PwrDiscnct.BattVltgAdcFaild
    connect CDD_FordT3T6McuCfg.BattVltgSwd1 -> PwrDiscnct.BattVltgSwd1
    connect CDD_FordT3T6McuCfg.ChrgPmpDiag -> PwrDiscnct.ChrgPmpDiag
    connect CDD_FordT3T6McuCfg.ChrgPmpDiagAdcFaild -> PwrDiscnct.ChrgPmpDiagAdcFaild
    connect CDD_FordT3T6McuCfg.PwrDiscnctSwtDiag -> PwrDiscnct.PwrDiscnctSwtDiag
    connect CDD_MotVel.MotVelMrf -> PwrDiscnct.MotVelMrf
    connect CDD_FordT3T6McuCfg.BattVltg -> PwrDiscnct.BattVltg
    connect Assi.AssiCmdBas -> AssiPahSum.AssiCmdBas
    connect Assi.AssiCmdBas -> Dampg.AssiCmdBas
    connect Assi.AssiCmdBas -> InertiaCmpVel.AssiCmdBas
    connect AssiHiFrq.AssiHiFrqCmd -> AssiPahSum.AssiHiFrqCmd
    connect AssiPahSum.AssiCmdSum -> StabyCmp.AssiCmdSum
    connect CalRegn01CmnGroupA.DampgQuadHwTqBacklsh -> Dampg.DampgQuadHwTqBacklsh
    connect CalRegn01CmnGroupA.DampgQuadMotVelBacklsh -> Dampg.DampgQuadMotVelBacklsh
    connect CalRegn01Inin00GroupA.AssiPahSumHysCmpLim -> AssiPahSum.AssiPahSumHysCmpLim
    connect CalRegn01Inin00GroupA.DampgHydBasCoeff{1..4} -> Dampg.DampgHydBasCoeff{1..4}
    connect CalRegn01Inin00GroupA.DampgHydOutpLim -> Dampg.DampgHydOutpLim
    connect CalRegn01Inin00GroupA.DampgMotVelLpFilFrq -> Dampg.DampgMotVelLpFilFrq
    connect CalRegn01Inin00GroupA.DampgQuad13Mplr -> Dampg.DampgQuad13Mplr
    connect CalRegn01Inin00GroupA.DampgQuad24Mplr -> Dampg.DampgQuad24Mplr
    connect CalRegn01Inin00GroupA.DampgQuadHwTqLpFilFrq -> Dampg.DampgQuadHwTqLpFilFrq
    connect CalRegn01Inin00GroupA.DampgQuadMotVelLpFilFrq -> Dampg.DampgQuadMotVelLpFilFrq
    connect CalRegn01Inin00GroupA.DampgQuadScaLpFilFrq -> Dampg.DampgQuadScaLpFilFrq
    connect CalRegn01Inin00GroupA.DampgTScaX -> Dampg.DampgTScaX
    connect CalRegn01Inin00GroupA.DampgTScaY -> Dampg.DampgTScaY
    connect CDD_MotVel.MotVelMrf -> AssiSumLim.MotVelMrf
    connect Dampg.DampgCmdBas -> DampgPahSum.DampgCmdBas
    connect DampgPahSum.DampgCmd -> AssiSumLim.DampgCmd
    connect DiagcMgrProxyAppl10.GetNtcQlfrSts10 -> AssiSumLim.GetNtcQlfrSts
    connect DiagcMgrProxyAppl10.SetNtcSts10 -> AssiSumLim.SetNtcSts
    connect DiagcMgrProxyAppl10.SetNtcSts10 -> RtnPahFwl.SetNtcSts
    connect FltInj.FltInj_f32 -> Assi.FltInj_f32
    connect FltInj.FltInj_f32 -> Dampg.FltInj_f32
    connect FltInj.FltInj_f32 -> InertiaCmpVel.FltInj_f32
    connect FltInj.FltInj_f32 -> Rtn.FltInj_f32
    connect FltInj.FltInj_f32 -> StabyCmp.FltInj_f32
    connect HwAgSysArbn.HwVel -> Rtn.HwVel
    connect InertiaCmpVel.InertiaCmpVelCmd -> DampgPahSum.InertiaCmpVelCmd
    connect Rtn.RtnCmd -> RtnPahFwl.RtnCmd
    connect RtnPahFwl.RtnCmdLimd -> AssiSumLim.RtnCmd
    connect StabyCmp.AssiCmd -> AssiSumLim.AssiCmd
    connect VehSigCdng.VehLgtA -> InertiaCmpVel.VehLgtA
    connect VehSigCdng.VehSpdVld -> Rtn.VehSpdVld
    connect Assi.AssiCmdBas -> HysCmp.AssiCmdBas
    connect DiagcMgrProxyAppl10.GetNtcQlfrSts10 -> EotLrng.GetNtcQlfrSts
    connect DiagcMgrProxyAppl10.SetNtcSts10 -> EotLrng.SetNtcSts
    connect EotLrng.HwAgCcwDetd -> EotProtn.HwAgCcwDetd
    connect EotLrng.HwAgCwDetd -> EotProtn.HwAgCwDetd
    connect EotLrng.HwAgEotCcw -> EotProtn.HwAgEotCcw
    connect EotLrng.HwAgEotCw -> EotProtn.HwAgEotCw
    connect EotLrng.HwAgEotCcw -> VehSpdLimr.HwAgEotCcw
    connect EotLrng.HwAgEotCw -> VehSpdLimr.HwAgEotCw
    connect FltInj.FltInj_f32 -> HysCmp.FltInj_f32
    connect HwAgSysArbn.PinionAgConf -> TqLoa.PinionAgConf
    connect HysCmp.HysCmpCmd -> AssiPahSum.HysCmpCmd
    connect TqLoa.TqLoaCmd -> AssiSumLim.TqLoaCmd
    connect VehSigCdng.VehLatA -> TqLoa.VehLatA
    connect VehSigCdng.VehLatAVld -> TqLoa.VehLatAVld
    connect VehSigCdng.VehSpdVld -> TqLoa.VehSpdVld
    connect NvMProxy.PSProxy_Rte_NvmBlock_EotLrng_EotNvmData -> EotLrng.EotNvmData
    connect NvMProxy.PSProxy_Rte_NvmBlock_EotLrng_MaxHwAgCwAndCcw -> EotLrng.MaxHwAgCwAndCcw
    connect CDD_FordT3T6McuCfg.BattVltg -> SysPrfmncSts.BattVltg
    connect CDD_MotVel.MotVelMrf -> MotRplCoggCfg.MotVelMrf
    connect CmplncErr.CmplncErrMotToPinion -> HwAgSnsrls.CmplncErrMotToPinion
    connect CmplncErr.CmplncErrPinionToHw -> HwAgSysArbn.CmplncErrPinionToHw
    connect DiagcMgrProxyAppl10.GetNtcQlfrSts10 -> SysFricLrng.GetNtcQlfrSts
    connect DiagcMgrProxyAppl10.SetNtcSts10 -> SysFricLrng.SetNtcSts
    connect DiagcMgrProxyAppl10.GetNtcQlfrSts10 -> SysPrfmncSts.GetNtcQlfrSts
    connect FltInj.FltInj_f32 -> SysFricLrng.FltInj_f32
    connect HwAgSysArbn.HwVel -> SysFricLrng.HwVel
    connect MotCtrlPrmEstimn.MotBackEmfConEstimd -> MotRplCoggCfg.MotBackEmfConEstimd
    connect MotCtrlPrmEstimn.MotInduDaxEstimd -> MotRplCoggCfg.MotInduDaxEstimd
    connect MotCtrlPrmEstimn.MotInduQaxEstimd -> MotRplCoggCfg.MotInduQaxEstimd
    connect PolarityCfg.AssiMechPolarity -> DrvrTqEstimn.AssiMechPolarity
    connect SysFricLrng.SysFricOffs -> HysCmp.SysFricOffs
    connect SysStMod.SysSt -> SysPrfmncSts.SysSt
    connect VehSigCdng.VehLatA -> SysFricLrng.VehLatA
    connect VehSigCdng.VehSpdVld -> SysFricLrng.VehSpdVld
    connect VehSigCdng.VehSpdVld -> SysPrfmncSts.VehSpdVld
    connect NvMProxy.PSProxy_Rte_NvmBlock_CDD_MotRplCoggCmd_MotCoggCmdY -> CDD_MotRplCoggCmd.MotCoggCmdY
    connect NvMProxy.PSProxy_Rte_NvmBlock_MotRplCoggCfg_MotRplCoggPrm -> MotRplCoggCfg.MotRplCoggPrm
    connect NvMProxy.PSProxy_Rte_NvmBlock_SysFricLrng_FricLrngData -> SysFricLrng.FricLrngData
    connect NvMProxy.PSProxy_Rte_NvmBlock_SysFricLrng_FricNonLrngData -> SysFricLrng.FricNonLrngData
    connect BattVltg.BrdgVltg -> CDD_MotCtrlMgr.BrdgVltg
    connect CDD_CurrMeas.CurrMeasWrmIninTestCmpl -> CDD_MotCtrlMgr.CurrMeasWrmIninTestCmpl
    connect CDD_CurrMeas.MotCurrQlfr1 -> CDD_MotCtrlMgr.MotCurrQlfr1
    connect CDD_FordT3T6McuCfg.MotCurrAdcVlyAAdcFaild -> CDD_MotCtrlMgr.MotCurrAdcVlyAAdcFaild
    connect CDD_FordT3T6McuCfg.MotCurrAdcVlyBAdcFaild -> CDD_MotCtrlMgr.MotCurrAdcVlyBAdcFaild
    connect CDD_FordT3T6McuCfg.MotCurrAdcVlyCAdcFaild -> CDD_MotCtrlMgr.MotCurrAdcVlyCAdcFaild
    connect CDD_MotCtrlMgr.MotCurrAdcVlyA -> CDD_CurrMeas.MotCurrAdcVlyA
    connect CDD_MotCtrlMgr.MotCurrAdcVlyB -> CDD_CurrMeas.MotCurrAdcVlyB
    connect CDD_MotCtrlMgr.MotCurrAdcVlyC -> CDD_CurrMeas.MotCurrAdcVlyC
    connect CDD_MotCtrlMgr.Ntc5DErrCnt -> CDD_CurrMeas.Ntc5DErrCnt
    connect CDD_MotCtrlMgr.MotAgCumvAlgndMrfRev -> CDD_MotAgCmp.MotAgCumvAlgndMrfRev
    connect CDD_MotCtrlMgr.MotAgCumvInid -> CDD_MotAgCmp.MotAgCumvInid
    connect CDD_MotCtrlMgr.MotAgBuf -> CDD_MotVel.MotAgBuf
    connect CDD_MotCtrlMgr.MotAgBufIdx -> CDD_MotVel.MotAgBufIdx
    connect CDD_MotCtrlMgr.MotAgTiBuf -> CDD_MotVel.MotAgTiBuf
    connect CDD_MotCtrlMgr.MotCurrCorrdA -> CurrMeasCorrln.MotCurrCorrdA
    connect CDD_MotCtrlMgr.MotCurrCorrdB -> CurrMeasCorrln.MotCurrCorrdB
    connect CDD_MotCtrlMgr.MotCurrCorrdC -> CurrMeasCorrln.MotCurrCorrdC
    connect CDD_MotCtrlMgr.MotCurrRollgCntr1 -> CurrMeasCorrln.MotCurrRollgCntr1
    connect CDD_MotVel.MotVelMrf -> CDD_MotCtrlMgr.MotVelMrf
    connect CurrMeasCorrln.CurrMeasCorrlnSts -> CDD_MotCtrlMgr.CurrMeasCorrlnSts
    connect MotAgCorrln.MotAgMeclCorrlnSt -> CDD_MotCtrlMgr.MotAgMeclCorrlnSt
    connect MotRplCoggCfg.MotAgElecDlyRpl -> CDD_MotCtrlMgr.MotAgElecDlyRpl
    connect MotRplCoggCfg.MotCurrQaxToMotTqGain -> CDD_MotCtrlMgr.MotCurrQaxToMotTqGain
    connect MotRplCoggCfg.MotTqRplCoggOrder1Mgn -> CDD_MotCtrlMgr.MotTqRplCoggOrder1Mgn
    connect MotRplCoggCfg.MotTqRplCoggOrder1Pha -> CDD_MotCtrlMgr.MotTqRplCoggOrder1Pha
    connect MotRplCoggCfg.MotTqRplCoggOrder2Mgn -> CDD_MotCtrlMgr.MotTqRplCoggOrder2Mgn
    connect MotRplCoggCfg.MotTqRplCoggOrder2Pha -> CDD_MotCtrlMgr.MotTqRplCoggOrder2Pha
    connect MotRplCoggCfg.MotTqRplCoggOrder3Mgn -> CDD_MotCtrlMgr.MotTqRplCoggOrder3Mgn
    connect MotRplCoggCfg.MotTqRplCoggOrder3Pha -> CDD_MotCtrlMgr.MotTqRplCoggOrder3Pha
    connect PolarityCfg.MotElecMeclPolarity -> CDD_MotCtrlMgr.MotElecMeclPolarity
    connect SysStMod.SysSt -> CDD_MotCtrlMgr.SysSt
    connect AssiSumLim.MotTqCmd -> Swp.MotTqCmd
    connect CDD_DmaCfgAndUse.DmaEna2MilliSecToMotCtrlTrf -> CDD_MotCtrlMgr.DmaEna2MilliSecToMotCtrlTrf
    connect CDD_DmaCfgAndUse.DmaWaitForMotCtrlTo2MilliSecTrf -> CDD_MotCtrlMgr.DmaWaitForMotCtrlTo2MilliSecTrf
    connect CDD_NxtrTi.GetRefTmr1MicroSec32bit -> CDD_DmaCfgAndUse.GetRefTmr1MicroSec32bit
    connect CDD_NxtrTi.GetTiSpan1MicroSec32bit -> CDD_DmaCfgAndUse.GetTiSpan1MicroSec32bit
    connect CDD_NxtrTi.GetRefTmr1MicroSec32bit -> CDD_FordT3T6McuCfg.GetRefTmr1MicroSec32bit
    connect CDD_NxtrTi.GetTiSpan1MicroSec32bit -> CDD_FordT3T6McuCfg.GetTiSpan1MicroSec32bit
    connect CDD_NxtrTi.GetRefTmr100MicroSec32bit -> EotLrng.GetRefTmr100MicroSec32bit
    connect CDD_NxtrTi.GetTiSpan100MicroSec32bit -> EotLrng.GetTiSpan100MicroSec32bit
    connect CDD_NxtrTi.GetRefTmr100MicroSec32bit -> FltInj.GetRefTmr100MicroSec32bit
    connect CDD_NxtrTi.GetTiSpan100MicroSec32bit -> FltInj.GetTiSpan100MicroSec32bit
    connect CDD_NxtrTi.GetRefTmr100MicroSec32bit -> HwAgSnsrls.GetRefTmr100MicroSec32bit
    connect CDD_NxtrTi.GetTiSpan100MicroSec32bit -> HwAgSnsrls.GetTiSpan100MicroSec32bit
    connect CDD_NxtrTi.GetRefTmr100MicroSec32bit -> HwAgSysArbn.GetRefTmr100MicroSec32bit
    connect CDD_NxtrTi.GetTiSpan100MicroSec32bit -> HwAgSysArbn.GetTiSpan100MicroSec32bit
    connect CDD_NxtrTi.GetRefTmr100MicroSec32bit -> Swp.GetRefTmr100MicroSec32bit
    connect CDD_NxtrTi.GetTiSpan100MicroSec32bit -> Swp.GetTiSpan100MicroSec32bit
    connect CDD_NxtrTi.GetRefTmr100MicroSec32bit -> SysFricLrng.GetRefTmr100MicroSec32bit
    connect CDD_NxtrTi.GetTiSpan100MicroSec32bit -> SysFricLrng.GetTiSpan100MicroSec32bit
    connect DiagcMgr.DiagcStsCtrldShtDwnFltPrsnt -> StOutpCtrl.DiagcStsCtrldShtDwnFltPrsnt
    connect DiagcMgr.SysDiMotTqCmdSca -> StOutpCtrl.SysDiMotTqCmdSca
    connect DiagcMgr.SysDiRampRate -> StOutpCtrl.SysDiRampRate
    connect DiagcMgrProxyAppl10.SetNtcSts10 -> CDD_NxtrTi.SetNtcSts
    connect StOutpCtrl.SysMotTqCmdSca -> EotProtn.SysMotTqCmdSca
    connect Swp.HwTqSwp -> VehSigCdng.HwTq
    connect VehSigCdng.VehSpd -> Swp.VehSpd
    connect VehSigCdng.VehSpdVld -> Swp.VehSpdVld
    connect CalRegn01CmnGroupA.TunSelnAuthyHwTqY -> TunSelnAuthy.TunSelnAuthyHwTqY
    connect CalRegn01CmnGroupA.TunSelnAuthyHwVelY -> TunSelnAuthy.TunSelnAuthyHwVelY
    connect CalRegn01CmnGroupA.TunSelnAuthyTunSelnRtDiCmd -> TunSelnAuthy.TunSelnAuthyTunSelnRtDiCmd
    connect CalRegn01Inin00GroupA.TunSelnAuthyVehSpdX -> TunSelnAuthy.TunSelnAuthyVehSpdX
    connect DiagcMgrProxyAppl10.SetNtcSts10 -> CDD_VrfyCritReg.SetNtcSts
    connect HwAgSysArbn.HwVel -> TunSelnAuthy.HwVel
    connect NvMProxy.PSProxy_Rte_NvmBlock_CDD_VrfyCritReg_MCalReadVrfyCritRegFltNvmInfo -> CDD_VrfyCritReg.MCalWrVrfyRegFltInfoStorg
    connect CDD_FordT3T6McuCfg.HwAg1SnsrTyp -> HwAg1Meas.HwAg1SnsrTyp
    connect CDD_McuDiagc.LoopCntr2MilliSec -> CDD_MotCtrlMgr.LoopCntr2MilliSec
    connect CDD_MotCtrlMgr.FastLoopCntr -> CDD_McuDiagc.FastLoopCntr
    connect CDD_MotCtrlMgr.SlowLoopCntr -> CDD_McuDiagc.SlowLoopCntr
    connect CDD_NxtrTi.GetRefTmr1MicroSec32bit -> HwAg1Meas.GetRefTmr1MicroSec32bit
    connect CDD_NxtrTi.GetTiSpan1MicroSec32bit -> HwAg1Meas.GetTiSpan1MicroSec32bit
    connect DiagcMgrProxyAppl10.SetNtcSts10 -> CDD_McuDiagc.SetNtcSts
    connect DiagcMgrProxyAppl10.GetNtcQlfrSts10 -> HwAg1Meas.GetNtcQlfrSts
    connect DiagcMgrProxyAppl10.SetNtcSts10 -> HwAg1Meas.SetNtcSts
    connect IoHwAb.SetFctPrphlHwAg1 -> HwAg1Meas.IoHwAb_SetFctPrphlHwAg1
    connect PolarityCfg.HwAg1Polarity -> HwAg1Meas.HwAg1Polarity
    connect NvMProxy.PSProxy_Rte_NvmBlock_HwAg1Meas_HwAg1IfFltLtch -> HwAg1Meas.HwAg1IfFltLtch
    connect NvMProxy.PSProxy_Rte_NvmBlock_HwAg1Meas_HwAg1Offs -> HwAg1Meas.HwAg1Offs
    connect BattVltg.BrdgVltg -> MotRefMdl.BrdgVltg
    connect CDD_CurrMeas.MotCurrEolCalSt -> MotCurrRegCfg.MotCurrEolCalSt
    connect CDD_MotVel.MotVelMrf -> MotCurrRegCfg.MotVelMrf
    connect CDD_MotVel.MotVelMrf -> MotRefMdl.MotVelMrf
    connect MotCtrlPrmEstimn.MotInduDaxEstimd -> MotCurrRegCfg.MotInduDaxEstimd
    connect MotCtrlPrmEstimn.MotInduQaxEstimd -> MotCurrRegCfg.MotInduQaxEstimd
    connect MotCtrlPrmEstimn.MotREstimd -> MotCurrRegCfg.MotREstimd
    connect MotCtrlPrmEstimn.MotBackEmfConEstimd -> MotRefMdl.MotBackEmfConEstimd
    connect MotCtrlPrmEstimn.MotInduDaxEstimd -> MotRefMdl.MotInduDaxEstimd
    connect MotCtrlPrmEstimn.MotInduQaxEstimd -> MotRefMdl.MotInduQaxEstimd
    connect MotCtrlPrmEstimn.MotREstimd -> MotRefMdl.MotREstimd
    connect MotQuadDetn.MotQuad -> MotRefMdl.MotQuad
    connect MotRefMdl.MotCurrDaxCmd -> MotCtrlPrmEstimn.MotCurrDaxCmd
    connect MotRefMdl.MotCurrQaxCmd -> MotCtrlPrmEstimn.MotCurrQaxCmd
    connect MotRefMdl.MotCurrDaxCmd -> MotCurrPeakEstimn.MotCurrDaxCmd
    connect MotRefMdl.MotCurrQaxCmd -> MotCurrPeakEstimn.MotCurrQaxCmd
    connect MotRefMdl.MotCurrDaxCmd -> MotRplCoggCfg.MotCurrDaxCmd
    connect MotRefMdl.MotCurrQaxCmd -> MotRplCoggCfg.MotCurrQaxCmd
    connect CDD_MotCtrlMgr.MotCurrDax -> MotCurrPeakEstimn.MotCurrDax
    connect CDD_MotCtrlMgr.MotCurrQax -> MotCurrPeakEstimn.MotCurrQax
    connect MotCtrlPrmEstimn.MotInduDaxEstimdIvs -> CDD_MotCtrlMgr.MotInduDaxEstimdIvs
    connect MotCtrlPrmEstimn.MotInduQaxEstimdIvs -> CDD_MotCtrlMgr.MotInduQaxEstimdIvs
    connect MotCtrlPrmEstimn.MotREstimd -> CDD_MotCtrlMgr.MotREstimd
    connect MotCurrRegCfg.MotAgElecDly -> CDD_MotCtrlMgr.MotAgElecDly
    connect MotCurrRegCfg.MotDampgDax -> CDD_MotCtrlMgr.MotDampgDax
    connect MotCurrRegCfg.MotDampgQax -> CDD_MotCtrlMgr.MotDampgQax
    connect MotCurrRegCfg.MotIntglGainDax -> CDD_MotCtrlMgr.MotIntglGainDax
    connect MotCurrRegCfg.MotIntglGainQax -> CDD_MotCtrlMgr.MotIntglGainQax
    connect MotCurrRegCfg.MotPropGainDax -> CDD_MotCtrlMgr.MotPropGainDax
    connect MotCurrRegCfg.MotPropGainQax -> CDD_MotCtrlMgr.MotPropGainQax
    connect MotRefMdl.MotBackEmfVltg -> CDD_MotCtrlMgr.MotBackEmfVltg
    connect MotRefMdl.MotCurrDaxCmd -> CDD_MotCtrlMgr.MotCurrDaxCmd
    connect MotRefMdl.MotCurrDaxMax -> CDD_MotCtrlMgr.MotCurrDaxMax
    connect MotRefMdl.MotCurrQaxCmd -> CDD_MotCtrlMgr.MotCurrQaxCmd
    connect MotRefMdl.MotReacncDax -> CDD_MotCtrlMgr.MotReacncDax
    connect MotRefMdl.MotReacncQax -> CDD_MotCtrlMgr.MotReacncQax
    connect MotRefMdl.MotVltgDaxFf -> CDD_MotCtrlMgr.MotVltgDaxFf
    connect MotRefMdl.MotVltgQaxFf -> CDD_MotCtrlMgr.MotVltgQaxFf
    connect CDD_FordT3T6McuCfg.MotAg5CosAdcFaild -> CDD_MotAg5Meas.MotAg5CosAdcFaild
    connect CDD_FordT3T6McuCfg.MotAg5SinAdcFaild -> CDD_MotAg5Meas.MotAg5SinAdcFaild
    connect CDD_FordT3T6McuCfg.MotAg6CosAdcFaild -> CDD_MotAg6Meas.MotAg6CosAdcFaild
    connect CDD_FordT3T6McuCfg.MotAg6SinAdcFaild -> CDD_MotAg6Meas.MotAg6SinAdcFaild
    connect CDD_MotAg5Meas.MotAg5CosRtAmpRecpr -> CDD_MotCtrlMgr.MotAg5CosRtAmpRecpr
    connect CDD_MotAg5Meas.MotAg5CosRtOffs -> CDD_MotCtrlMgr.MotAg5CosRtOffs
    connect CDD_MotAg5Meas.MotAg5MeclQlfr -> CDD_MotCtrlMgr.MotAg5MeclQlfr
    connect CDD_MotAg5Meas.MotAg5SinRtAmpRecpr -> CDD_MotCtrlMgr.MotAg5SinRtAmpRecpr
    connect CDD_MotAg5Meas.MotAg5SinRtOffs -> CDD_MotCtrlMgr.MotAg5SinRtOffs
    connect CDD_MotAg5Meas.MotAg5MeclQlfr -> MotAgCorrln.MotAgAMeclQlfr
    connect CDD_MotAg5Meas.MotAg5MeclRollgCntr -> MotAgCorrln.MotAgAMeclRollgCntr
    connect CDD_MotAg6Meas.MotAg6CosRtAmpRecpr -> CDD_MotCtrlMgr.MotAg6CosRtAmpRecpr
    connect CDD_MotAg6Meas.MotAg6CosRtOffs -> CDD_MotCtrlMgr.MotAg6CosRtOffs
    connect CDD_MotAg6Meas.MotAg6MeclQlfr -> CDD_MotCtrlMgr.MotAg6MeclQlfr
    connect CDD_MotAg6Meas.MotAg6SinRtAmpRecpr -> CDD_MotCtrlMgr.MotAg6SinRtAmpRecpr
    connect CDD_MotAg6Meas.MotAg6SinRtOffs -> CDD_MotCtrlMgr.MotAg6SinRtOffs
    connect CDD_MotAg6Meas.MotAg6MeclQlfr -> MotAgCorrln.MotAgBMeclQlfr
    connect CDD_MotAg6Meas.MotAg6MeclRollgCntr -> MotAgCorrln.MotAgBMeclRollgCntr
    connect CDD_MotCtrlMgr.MotAg5Cos -> CDD_MotAg5Meas.MotAg5Cos
    connect CDD_MotCtrlMgr.MotAg5Sin -> CDD_MotAg5Meas.MotAg5Sin
    connect CDD_MotCtrlMgr.MotAg6Cos -> CDD_MotAg6Meas.MotAg6Cos
    connect CDD_MotCtrlMgr.MotAg6Sin -> CDD_MotAg6Meas.MotAg6Sin
    connect CDD_MotCtrlMgr.MotAg5Mecl -> MotAgCorrln.MotAgAMecl
    connect CDD_MotCtrlMgr.MotAg6Mecl -> MotAgCorrln.MotAgBMecl
    connect CDD_MotVel.MotVelMrf -> CDD_MotAg5Meas.MotVelMrf
    connect CDD_MotVel.MotVelMrf -> CDD_MotAg6Meas.MotVelMrf
    connect CDD_NxtrTi.GetRefTmr1MicroSec32bit -> CDD_MotAg5Meas.GetRefTmr1MicroSec32bit
    connect CDD_NxtrTi.GetRefTmr1MicroSec32bit -> TmplMonr.GetRefTmr1MicroSec32bit
    connect CDD_NxtrTi.GetTiSpan1MicroSec32bit -> TmplMonr.GetTiSpan1MicroSec32bit
    connect DiagcMgr.CnvSnpshtData_f32 -> CDD_MotAg5Meas.CnvSnpshtData_f32
    connect DiagcMgr.CnvSnpshtData_logl -> CDD_MotAg5Meas.CnvSnpshtData_logl
    connect DiagcMgr.CnvSnpshtData_f32 -> CDD_MotAg6Meas.CnvSnpshtData_f32
    connect DiagcMgr.CnvSnpshtData_logl -> CDD_MotAg6Meas.CnvSnpshtData_logl
    connect DiagcMgrProxyAppl10.GetNtcQlfrSts10 -> CDD_MotAg5Meas.GetNtcQlfrSts
    connect DiagcMgrProxyAppl10.SetNtcStsAndSnpshtData10 -> CDD_MotAg5Meas.SetNtcStsAndSnpshtData
    connect DiagcMgrProxyAppl10.GetNtcQlfrSts10 -> CDD_MotAg6Meas.GetNtcQlfrSts
    connect DiagcMgrProxyAppl10.SetNtcStsAndSnpshtData10 -> CDD_MotAg6Meas.SetNtcStsAndSnpshtData
    connect DiagcMgrProxyAppl10.GetNtcQlfrSts10 -> GateDrv0Ctrl.GetNtcQlfrSts
    connect DiagcMgrProxyAppl10.SetNtcSts10 -> GateDrv0Ctrl.SetNtcSts
    connect DiagcMgrProxyAppl10.SetNtcSts10 -> PwrSply.SetNtcSts
    connect DiagcMgrProxyAppl10.SetNtcSts10 -> TmplMonr.SetNtcSts
    connect GateDrv0Ctrl.DiagcStsIvtr1Inactv -> BattVltgCorrln.DiagcStsIvtr1Inactv
    connect GateDrv0Ctrl.DiagcStsIvtr1Inactv -> CDD_CurrMeas.DiagcStsIvtr1Inactv
    connect GateDrv0Ctrl.DiagcStsIvtr1Inactv -> CDD_MotCtrlMgr.DiagcStsIvtr1Inactv
    connect GateDrv0Ctrl.DiagcStsIvtr1Inactv -> CurrMeasCorrln.DiagcStsIvtr1Inactv
    connect GateDrv0Ctrl.MotDrvr0IninTestCmpl -> PwrUpSeq.MotDrvr0IninTestCmpl
    connect GateDrv0Ctrl.DiagcStsIvtr1Inactv -> ShtdwnMech.DiagcStsIvtr1Inactv
    connect IoHwAb.SetGpioSysFlt2A -> GateDrv0Ctrl.IoHwAb_SetGpioSysFlt2A
    connect IoHwAb.GetGpioPwrOutpEnaFb -> TmplMonr.IoHwAb_GetGpioPwrOutpEnaFb
    connect IoHwAb.SetGpioTmplMonrWdg -> TmplMonr.IoHwAb_SetGpioTmplMonrWdg
    connect PwrUpSeq.StrtUpSt -> GateDrv0Ctrl.StrtUpSt
    connect PwrUpSeq.StrtUpSt -> TmplMonr.StrtUpSt
    connect SysStMod.SysSt -> GateDrv0Ctrl.SysSt
    connect SysStMod.SysSt -> PwrSply.SysSt
    connect SysStMod.SysSt -> TmplMonr.SysSt
    connect TmplMonr.TmplMonrIninTestCmpl -> PwrUpSeq.TmplMonIninTestCmpl
    connect NvMProxy.PSProxy_Rte_NvmBlock_CDD_MotAg5Meas_MotAg5EolPrm -> CDD_MotAg5Meas.MotAg5EolPrm
    connect NvMProxy.PSProxy_Rte_NvmBlock_CDD_MotAg5Meas_MotAg5StVari -> CDD_MotAg5Meas.MotAg5StVari
    connect NvMProxy.PSProxy_Rte_NvmBlock_CDD_MotAg6Meas_MotAg6EolPrm -> CDD_MotAg6Meas.MotAg6EolPrm
    connect NvMProxy.PSProxy_Rte_NvmBlock_CDD_MotAg6Meas_MotAg6StVari -> CDD_MotAg6Meas.MotAg6StVari
    connect CDD_MotAg5Meas.MotAg5MeclRollgCntr -> CDD_MotCtrlMgr.MotAg5MeclRollgCntr
    connect CDD_MotAg6Meas.MotAg6MeclRollgCntr -> CDD_MotCtrlMgr.MotAg6MeclRollgCntr
    connect SysStMod.SysSt -> DiagcMgr.SysSt
    connect CDD_MotVel.MotVelVld -> HwAgSysArbn.MotVelVld
    connect MotAgCorrln.MotAgMeclIdptSig -> CDD_MotVel.MotAgMeclIdptSig
    connect NvMProxy.PSProxy_Rte_NvmBlock_MotCtrlPrmEstimn_MotPrmNom -> MotCtrlPrmEstimn.MotPrmNom
    connect DiagcMgrProxyAppl10.GetNtcQlfrSts10 -> HwTqCorrln.GetNtcQlfrSts
    connect DiagcMgrProxyAppl10.SetNtcSts10 -> HwTqCorrln.SetNtcSts
    connect FltInj.FltInj_u08 -> HwTqCorrln.FltInj_u08
    connect HwTqArbn.HwTq -> Swp.HwTq
    connect HwTqCorrln.HwTqCorrlnSts -> HwTqArbn.HwTqCorrlnSts
    connect AssiSumLim.MotTqCmdLimdPreStall -> HiLoadStallLimr.MotTqCmdLimdPreStall
    connect BattVltg.BrdgVltg -> PwrLimr.BrdgVltg
    connect CDD_MotVel.MotVelMrf -> PwrLimr.MotVelMrf
    connect CDD_NxtrTi.GetRefTmr100MicroSec32bit -> PwrLimr.GetRefTmr100MicroSec32bit
    connect CDD_NxtrTi.GetTiSpan100MicroSec32bit -> PwrLimr.GetTiSpan100MicroSec32bit
    connect DiagcMgr.SysStFltOutpReqDi -> StOutpCtrl.SysStFltOutpReqDi
    connect DiagcMgrProxyAppl10.SetNtcSts10 -> DutyCycThermProtn.SetNtcSts
    connect DiagcMgrProxyAppl10.SetNtcSts10 -> EotProtnFwl.SetNtcSts
    connect DiagcMgrProxyAppl10.SetNtcSts10 -> PwrLimr.SetNtcSts
    connect DutyCycThermProtn.ThermLimSlowFilMax -> Assi.ThermLimSlowFilMax
    connect DutyCycThermProtn.ThermRednFac -> AssiSumLim.ThermRednFac
    connect DutyCycThermProtn.ThermMotTqLim -> LimrCdng.ThermMotTqLim
    connect DutyCycThermProtn.DutyCycThermProtnMaxOutp -> SysPrfmncSts.DutyCycThermProtnMaxOutp
    connect DutyCycThermProtn.ThermDutyCycProtnLoadDptLim -> SysPrfmncSts.ThermDutyCycProtnLoadDptLim
    connect DutyCycThermProtn.ThermDutyCycProtnTDptLim -> SysPrfmncSts.ThermDutyCycProtnTDptLim
    connect EotProtn.EotActvCmd -> EotProtnFwl.EotActvCmd
    connect EotProtn.EotAssiSca -> LimrCdng.EotAssiSca
    connect EotProtn.EotMotTqLim -> LimrCdng.EotMotTqLim
    connect EotProtnFwl.EotActvCmdLimd -> AssiSumLim.EotActvCmd
    connect EotProtnFwl.EotDampgCmdLimd -> AssiSumLim.EotDampgCmd
    connect FltInj.FltInj_f32 -> LimrCdng.FltInj_f32
    connect HiLoadStallLimr.StallMotTqLim -> LimrCdng.StallMotTqLim
    connect HiLoadStallLimr.StallMotTqLim -> SysPrfmncSts.StallMotTqLim
    connect HwAgSysArbn.PinionAgConf -> EotProtnFwl.PinionAgConf
    connect HwAgSysArbn.HwVel -> TEstimn.HwVel
    connect LimrCdng.EotAssiScaCdnd -> AssiSumLim.EotAssiSca
    connect LimrCdng.EotMotTqLimCdnd -> AssiSumLim.EotMotTqLim
    connect LimrCdng.StallMotTqLimCdnd -> AssiSumLim.StallMotTqLim
    connect LimrCdng.SysMotTqCmdScaCdnd -> AssiSumLim.SysMotTqCmdSca
    connect LimrCdng.ThermMotTqLimCdnd -> AssiSumLim.ThermMotTqLim
    connect LimrCdng.VehSpdMotTqLimCdnd -> AssiSumLim.VehSpdMotTqLim
    connect MotCtrlPrmEstimn.MotBackEmfConEstimd -> PwrLimr.MotBackEmfConEstimd
    connect MotCurrPeakEstimn.MotCurrPeakEstimd -> DutyCycThermProtn.MotCurrPeakEstimd
    connect MotCurrPeakEstimn.MotCurrPeakEstimdFild -> DutyCycThermProtn.MotCurrPeakEstimdFild
    connect MotCurrPeakEstimn.MotCurrPeakEstimd -> TEstimn.MotCurrPeakEstimd
    connect PwrLimr.PwrLimrRednFac -> AssiSumLim.PwrLimrRednFac
    connect PwrLimr.MotTqCmdPwrLimd -> DrvrTqEstimn.MotTqCmdPwrLimd
    connect StOutpCtrl.SysMotTqCmdSca -> LimrCdng.SysMotTqCmdSca
    connect TEstimn.AssiMechT -> Dampg.AssiMechT
    connect TEstimn.MotFetT -> DutyCycThermProtn.MotFetT
    connect TEstimn.MotMagT -> DutyCycThermProtn.MotMagT
    connect TEstimn.MotWidgT -> DutyCycThermProtn.MotWidgT
    connect TEstimn.AssiMechT -> HysCmp.AssiMechT
    connect TEstimn.MotFetT -> MotCtrlPrmEstimn.MotFetT
    connect TEstimn.MotMagT -> MotCtrlPrmEstimn.MotMagT
    connect TEstimn.MotWidgT -> MotCtrlPrmEstimn.MotWidgT
    connect TEstimn.AssiMechT -> Rtn.AssiMechT
    connect TEstimn.AssiMechT -> SysFricLrng.AssiMechT
    connect VehSpdLimr.VehSpdMotTqLim -> LimrCdng.VehSpdMotTqLim
    connect CDD_NxtrTi.GetRefTmr100MicroSec32bit -> MotTqTranlDampg.GetRefTmr100MicroSec32bit
    connect CDD_NxtrTi.GetTiSpan100MicroSec32bit -> MotTqTranlDampg.GetTiSpan100MicroSec32bit
    connect DiagcMgr.DiagcStsCtrldShtDwnFltPrsnt -> MotTqTranlDampg.DiagcStsCtrldShtDwnFltPrsnt
    connect MotTqCmdSca.MotTqCmdMrfScad -> DiagcMgr.MotTqCmdMrfScad
    connect MotTqCmdSca.MotTqCmdMrfScad -> MotRefMdl.MotTqCmdMrfScad
    connect MotTqCmdSca.MotTqCmdMrfScad -> MotRplCoggCfg.MotTqCmdMrfScad
    connect MotTqTranlDampg.MotTqCmdCrfDampd -> CmplncErr.MotTqCmdCrf
    connect MotTqTranlDampg.MotTqCmdCrfDampd -> HwAgSnsrls.MotTqCmdCrf
    connect MotTqTranlDampg.MotTqCmdMrfDampd -> PwrLimr.MotTqCmdMrf
    connect MotTqTranlDampg.MotTqTranlDampgCmpl -> StOutpCtrl.MotTqTranlDampgCmpl
    connect MotTqTranlDampg.MotTqCmdCrfDampd -> SysFricLrng.MotTqCmdCrf
    connect PolarityCfg.AssiMechPolarity -> MotTqTranlDampg.AssiMechPolarity
    connect Swp.MotTqCmdSwp -> MotTqTranlDampg.MotTqCmdCrf
    connect SysStMod.SysSt -> MotTqTranlDampg.SysSt
    connect NvMProxy.PSProxy_Rte_NvmBlock_DutyCycThermProtn_FilStVal -> DutyCycThermProtn.FilStVal
    connect NvMProxy.PSProxy_Rte_NvmBlock_MotTqCmdSca_MotTqScaFac -> MotTqCmdSca.MotTqScaFac
    connect AssiSumLim.SetManTqCmd -> CmnMfgSrv.SetManTqCmd
    connect BattVltg.BrdgVltg -> CmnMfgSrv.BrdgVltg
    connect CDD_CurrMeas.CurrMeasEolGainReq -> CmnMfgSrv.CurrMeasEolGainReq
    connect CDD_CurrMeas.CurrMeasEolGainStsReq -> CmnMfgSrv.CurrMeasEolGainStReq
    connect CDD_CurrMeas.CurrMeasEolOffsReq -> CmnMfgSrv.CurrMeasEolOffsReq
    connect CDD_CurrMeas.CurrMeasEolOffsStsReq -> CmnMfgSrv.CurrMeasEolOffsStReq
    connect CDD_MotAgCmp.MotAgCmpBackEmfRead -> CmnMfgSrv.MotAgCmpBackEmfRead
    connect CDD_MotAgCmp.MotAgCmpBackEmfWr -> CmnMfgSrv.MotAgCmpBackEmfWr
    connect CDD_MotAgCmp.MotAgCumvAlgndMrf -> CmnMfgSrv.MotAgCumvAlgndMrf
    connect CDD_MotCtrlMgr.MotCurrDax -> CmnMfgSrv.MotCurrDax
    connect CDD_MotCtrlMgr.MotCurrQax -> CmnMfgSrv.MotCurrQax
    connect CDD_MotRplCoggCmd.GetMotCoggCmdPrm -> CmnMfgSrv.GetMotCoggCmdPrm
    connect CDD_MotRplCoggCmd.SetMotCoggCmdPrm -> CmnMfgSrv.SetMotCoggCmdPrm
    connect CDD_MotVel.MotVelMrf -> CmnMfgSrv.MotVelMrf
    connect CDD_NxtrTi.GetRefTmr100MicroSec32bit -> CmnMfgSrv.GetRefTmr100MicroSec32bit1
    connect CDD_NxtrTi.GetTiSpan100MicroSec32bit -> CmnMfgSrv.GetTiSpan100MicroSec32bit1
    connect CmnMfgSrv.AssiLnrGain -> Assi.AssiLnrGain
    connect CmnMfgSrv.AssiLnrGainEna -> Assi.AssiLnrGainEna
    connect CmnMfgSrv.DampgCmdBasDi -> Dampg.DampgCmdBasDi
    connect CmnMfgSrv.IgnCntr -> DiagcMgr.IgnCntr
    connect CmnMfgSrv.MfgDiagcInhb -> DiagcMgr.MfgDiagcInhb
    connect CmnMfgSrv.MfgEnaSt -> DiagcMgr.MfgEnaSt
    connect CmnMfgSrv.DutyCycThermProtnDi -> DutyCycThermProtn.DutyCycThermProtnDi
    connect CmnMfgSrv.EotProtnDi -> EotProtn.EotProtnDi
    connect CmnMfgSrv.EotProtnDi -> EotProtnFwl.EotProtnDi
    connect CmnMfgSrv.MfgEnaSt -> EotProtnFwl.MfgEnaSt
    connect CmnMfgSrv.StallMotTqLimDi -> HiLoadStallLimr.StallMotTqLimDi
    connect CmnMfgSrv.HysCmpCmdDi -> HysCmp.HysCmpCmdDi
    connect CmnMfgSrv.InertiaCmpVelCmdDi -> InertiaCmpVel.InertiaCmpVelCmdDi
    connect CmnMfgSrv.RtnCmdDi -> Rtn.RtnCmdDi
    connect CmnMfgSrv.MfgEnaSt -> RtnPahFwl.MfgEnaSt
    connect CmnMfgSrv.RtnCmdDi -> RtnPahFwl.RtnCmdDi
    connect CmnMfgSrv.SysMotTqCmdRampRateDi -> StOutpCtrl.SysMotTqCmdRampRateDi
    connect CmnMfgSrv.FricLrngDi -> SysFricLrng.FricLrngDi
    connect CmnMfgSrv.SysStImdtTranReqOff -> SysStMod.SysStImdtTranReqOff
    connect CmnMfgSrv.AssiMechTEstimnDi -> TEstimn.AssiMechTEstimnDi
    connect CmnMfgSrv.VehSpdOvrd -> VehSigCdng.VehSpdOvrd
    connect CmnMfgSrv.VehSpdOvrdEna -> VehSigCdng.VehSpdOvrdEna
    connect DiagcMgr.ClrAllDiagc -> CmnMfgSrv.ClrAllDiagc
    connect DiagcMgr.ClrSnpshtData -> CmnMfgSrv.ClrSnpshtData
    connect DiagcMgr.ReadNtcFltAry -> CmnMfgSrv.ReadNtcFltAry
    connect DiagcMgr.ReadNtcInfoAndDebCntr -> CmnMfgSrv.ReadNtcInfoAndDebCntr
    connect EotLrng.GetHwAgOverTrvlCnt -> CmnMfgSrv.GetHwAgOverTrvlCnt
    connect EotLrng.RstHwAgOverTrvlCnt -> CmnMfgSrv.RstHwAgOverTrvlCnt
    connect EotLrng.RstMaxHwAgCwAndCcw -> CmnMfgSrv.RstMaxHwAgCwAndCcw
    connect EotLrng.RtnMaxHwAgCwAndCcw -> CmnMfgSrv.RtnMaxHwAgCwAndCcw
    connect EotLrng.SerlComRstEot -> CmnMfgSrv.SerlComRstEot
    connect EotLrng.SetHwAgOverTrvlCnt -> CmnMfgSrv.SetHwAgOverTrvlCnt
    connect HwAg1Meas.HwAg1 -> CmnMfgSrv.HwAg1
    connect HwAg1Meas.HwAg1ClrLtch -> CmnMfgSrv.HwAg1ClrLtch
    connect HwAg1Meas.HwAg1ClrTrim -> CmnMfgSrv.HwAg1MeasHwAg1ClrTrim
    connect HwAg1Meas.HwAg1ReadTrim -> CmnMfgSrv.HwAg1MeasHwAg1ReadTrim
    connect HwAg1Meas.HwAg1TrimPrfmdSts -> CmnMfgSrv.HwAg1MeasHwAg1TrimPrfmdSts
    connect HwAg1Meas.HwAg1WrTrim -> CmnMfgSrv.HwAg1MeasHwAg1WrTrim
    connect HwAgSnsrls.FSnsrlsHwCentr -> CmnMfgSrv.FSnsrlsHwCentr
    connect HwAgSnsrls.RstSnsrlsHwCentr -> CmnMfgSrv.RstSnsrlsHwCentr
    connect HwAgSysArbn.PinionAg -> CmnMfgSrv.PinionAg
    connect MotAg2Meas.MotAg2Mecl -> CmnMfgSrv.MotAg2Mecl
    connect MotCtrlPrmEstimn.GetMotPrmNomEol -> CmnMfgSrv.GetMotPrmNomEol
    connect MotCtrlPrmEstimn.SetMotPrmNomEol -> CmnMfgSrv.SetMotPrmNomEol
    connect MotRplCoggCfg.GetMotRplCoggPrm -> CmnMfgSrv.GetMotRplCoggPrm
    connect MotRplCoggCfg.SetMotRplCoggPrm -> CmnMfgSrv.SetMotRplCoggPrm
    connect MotTqCmdSca.GetMotTqCmdSca -> CmnMfgSrv.GetMotTqCmdSca
    connect MotTqCmdSca.SetMotTqCmdSca -> CmnMfgSrv.SetMotTqCmdSca
    connect PolarityCfg.PolarityCfgRead -> CmnMfgSrv.PolarityCfgRead
    connect PolarityCfg.PolarityCfgWr -> CmnMfgSrv.PolarityCfgWr
    connect SysFricLrng.ClrFricLrngOperMod -> CmnMfgSrv.ClrFricLrngOperMod
    connect SysFricLrng.GetFricData -> CmnMfgSrv.GetFricData
    connect SysFricLrng.GetFricLrngData -> CmnMfgSrv.GetFricLrngData
    connect SysFricLrng.GetFricOffsOutpDi -> CmnMfgSrv.GetFricOffsOutpDi
    connect SysFricLrng.InitFricLrngTbl -> CmnMfgSrv.InitFricLrngTbl
    connect SysFricLrng.SetFricData -> CmnMfgSrv.SetFricData
    connect SysFricLrng.SetFricLrngData -> CmnMfgSrv.SetFricLrngData
    connect SysFricLrng.SetFricOffsOutpDi -> CmnMfgSrv.SetFricOffsOutpDi
    connect SysStMod.SysSt -> CmnMfgSrv.SysSt
    connect NvMProxy.PSProxy_Rte_NvmBlock_CmnMfgSrv_CcaHwPartNr -> CmnMfgSrv.NvmCcaHwPartNr
    connect NvMProxy.PSProxy_Rte_NvmBlock_CmnMfgSrv_CcaSerlNr -> CmnMfgSrv.NvmCcaSerlNr
    connect NvMProxy.PSProxy_Rte_NvmBlock_CmnMfgSrv_DiRestore -> CmnMfgSrv.NvmDiRestore
    connect NvMProxy.PSProxy_Rte_NvmBlock_CmnMfgSrv_EpsSysSerlNr -> CmnMfgSrv.NvmEpsSysSerlNr
    connect NvMProxy.PSProxy_Rte_NvmBlock_CmnMfgSrv_IgnCntr -> CmnMfgSrv.NvmIgnCntr
    connect NvMProxy.PSProxy_Rte_NvmBlock_CmnMfgSrv_MfgTmpBuf{0..4} -> CmnMfgSrv.NvmMfgTmpBuf{0..4}
    connect NvMProxy.PSProxy_Rte_NvmBlock_CmnMfgSrv_NxtrMfgEnaCntr -> CmnMfgSrv.NvmMfgEnaCntr
    connect NvMProxy.PSProxy_Rte_NvmBlock_CmnMfgSrv_SeedKey -> CmnMfgSrv.NvmSeedKey
    connect DiagcMgrProxyAppl10.GetNtcSts10 -> CmnMfgSrv.GetNtcSts
    connect HwAg1Meas.HwAg1AutTrim -> CmnMfgSrv.HwAg1MeasHwAg1AutoTrim
    connect CmnMfgSrv.CmnMfgSrvCmnMfgSrvMaiFct -> DiagSrv.CmnMfgSrvCmnMfgSrvMaiFct
    connect DiagSrv.DataServices_DIDRange_NexteerDidRangeFD00toFD39 -> Dcm.DataServices_DIDRange_NexteerDidRangeFD00toFD39
    connect DiagSrv.DataServices_DIDRange_NexteerDidRangeFD43toFEFF -> Dcm.DataServices_DIDRange_NexteerDidRangeFD43toFEFF
    connect DiagcMgrProxyAppl10.SetNtcSts10 -> TunSelnMngt.SetNtcSts
    connect NxtrSwIds.NxtrSwIdsPsrInfoRd -> CmnMfgSrv.NxtrSwIdsPsrInfoRd
    connect NxtrSwIds.NxtrSwIdsSwBuildDateTiRd -> CmnMfgSrv.NxtrSwIdsSwBuildDateTiRd
    connect NxtrSwIds.NxtrSwIdsSwRelInfoRd -> CmnMfgSrv.NxtrSwIdsSwRelInfoRd
    connect NxtrSwIds.NxtrSwIdsSwRelNrRd -> CmnMfgSrv.NxtrSwIdsSwRelNrRd
    connect NxtrSwIds.NxtrSwIdsSwRelVerRd -> CmnMfgSrv.NxtrSwIdsSwRelVerRd
    connect TunSelnAuthy.RtCalChgReq -> TunSelnMngt.RtCalChgReq
    connect CmnMfgSrv.MfgEnaSt -> CDD_XcpIf.MfgEnaSt
    connect TunSelnAuthy.XcpCalChgReq -> CDD_XcpIf.XcpCalChgReq
    connect TunSelnMngt.ActvGroup -> CDD_XcpIf.ActvGroup
    connect TunSelnMngt.ActvIninIdx -> CDD_XcpIf.ActvIninIdx
    connect TunSelnMngt.ActvRtIdx -> CDD_XcpIf.ActvRtIdx
    connect TunSelnMngt.CalCopySts -> CDD_XcpIf.CalCopySts
    connect TunSelnMngt.CopyCalPageReq -> CDD_XcpIf.CopyCalPageReq
    connect TunSelnMngt.GetCalPageReq -> CDD_XcpIf.GetCalPageReq
    connect TunSelnMngt.GetSegInfoReq -> CDD_XcpIf.GetSegInfoReq
    connect TunSelnMngt.OnlineTunRamAdrMpg -> CDD_XcpIf.OnlineTunRamAdrMpg
    connect TunSelnMngt.SetCalPageReq -> CDD_XcpIf.SetCalPageReq
    connect NvMProxy.PSProxy_Rte_NvmBlock_DiagcMgr_DiagcMgrApplCrc -> DiagcMgr.DiagcMgrApplCrc
    connect DiagSrv.RoutineServices_RTN_Nexteer_FD70_Clear_Nexteer_Trouble_Codes -> Dcm.RoutineServices_RTN_Nexteer_FD70_Clear_Nexteer_Trouble_Codes
    connect DiagSrv.RoutineServices_RTN_Nexteer_FDF0_Current_Gain_Auto_Trim -> Dcm.RoutineServices_RTN_Nexteer_FDF0_Current_Gain_Auto_Trim
    connect DiagSrv.RoutineServices_RTN_Nexteer_FDF1_Current_Offset_Auto_Trim -> Dcm.RoutineServices_RTN_Nexteer_FDF1_Current_Offset_Auto_Trim
    connect CDD_FordT3T6McuCfg.MotDrvr1IninTestCmpl -> PwrUpSeq.MotDrvr1IninTestCmpl
    connect IoHwAb.GetGpioMotDrvr0Diag -> GateDrv0Ctrl.IoHwAb_GetGpioMotDrvr0Diag
    connect IoHwAb.SetGpioGateDrv0Rst -> GateDrv0Ctrl.IoHwAb_SetGpioGateDrv0Rst
    connect CalRegn01Inin00GroupA.ImcSigArbnPullCmpLongTermArbnOffsLim -> ImcSigArbn.ImcSigArbnPullCmpLongTermArbnOffsLim
    connect CalRegn01Inin00GroupA.ImcSigArbnPullCmpShoTermArbnOffsLim -> ImcSigArbn.ImcSigArbnPullCmpShoTermArbnOffsLim
    connect CDD_MotVel.MotVelCrf -> ImcSigArbn.MotVelCrf
    connect CDD_NxtrTi.GetRefTmr100MicroSec32bit -> ImcArbn.GetRefTmr100MicroSec32bit
    connect CDD_NxtrTi.GetTiSpan100MicroSec32bit -> ImcArbn.GetTiSpan100MicroSec32bit
    connect CDD_NxtrTi.GetRefTmr100MicroSec32bit -> ImcSigArbn.GetRefTmr100MicroSec32bit
    connect CDD_NxtrTi.GetTiSpan100MicroSec32bit -> ImcSigArbn.GetTiSpan100MicroSec32bit
    connect DiagcMgrProxyAppl10.SetNtcSts10 -> ImcArbn.SetNtcSts
    connect DiagcMgrProxyAppl10.SetNtcSts10 -> ImcSigArbn.SetNtcSts
    connect DualEcuIdn.EcuId -> ImcSigArbn.EcuIdn
    connect ImcArbn.GetTxRateGroup -> CDD_Uart0CfgAndUse.GetTxRateGroup
    connect ImcArbn.SetRxSigGroup -> CDD_Uart0CfgAndUse.SetRxSigGroup
    connect ImcArbn.GetTxRateGroup -> CDD_Uart1CfgAndUse.GetTxRateGroup
    connect ImcArbn.SetRxSigGroup -> CDD_Uart1CfgAndUse.SetRxSigGroup
    connect ImcArbn.GetSigImcData_u08 -> DualEcuIdn.GetSigImcData_u08
    connect ImcArbn.GetSigImcData_f32 -> ImcSigArbn.GetImcSigData_f32
    connect ImcArbn.GetSigImcData_logl -> ImcSigArbn.GetImcSigData_logl
    connect ImcArbn.GetSigImcData_u08 -> ImcSigArbn.GetImcSigData_u08
    connect PosnTrakgServo.PosnServoIntgtrSt -> ImcSigArbn.PosnServoIntgtrSt
    connect VehSigCdng.VehSpd -> ImcSigArbn.VehSpd
    connect DualEcuIdn.EcuId -> ImcArbn.EcuId
    connect SysStMod.SysSt -> ImcArbn.SysSt
    connect VehSigCdng.VehSpd -> ImcArbn.VehSpd
    connect PolarityCfg.MotElecMeclPolarity -> CDD_SinVltgGenn.MotElecMeclPolarity
    connect CDD_MotCtrlMgr.PhaOnTiSumA -> GateDrv0Ctrl.PhaOnTiSumA
    connect CDD_MotCtrlMgr.PhaOnTiSumB -> GateDrv0Ctrl.PhaOnTiSumB
    connect CDD_MotCtrlMgr.PhaOnTiSumC -> GateDrv0Ctrl.PhaOnTiSumC
    connect VehSigCdng.VehSpd -> CDD_MotCtrlMgr.VehSpd
    connect BattVltg.BrdgVltg -> ElecPwrCns.BrdgVltg
    connect CalRegn01CmnGroupA.ElecPwrCnsPrstcPwrLoss -> ElecPwrCns.ElecPwrCnsPrstcPwrLoss
    connect CDD_MotCtrlMgr.MotCurrDax -> ElecPwrCns.MotCurrDax
    connect CDD_MotCtrlMgr.MotCurrQax -> ElecPwrCns.MotCurrQax
    connect CDD_NxtrTi.GetRefTmr100MicroSec32bit -> DualCtrlrOutpMgr.GetRefTmr100MicroSec32bit
    connect CDD_NxtrTi.GetTiSpan100MicroSec32bit -> DualCtrlrOutpMgr.GetTiSpan100MicroSec32bit
    connect CmnMfgSrv.LoaScaDi -> LoaMgr.LoaScaDi
    connect CurrMeasCorrln.CurrMeasIdptSig -> LoaMgr.CurrMeasIdptSig
    connect DiagcMgrProxyAppl10.SetNtcSts10 -> LoaMgr.SetNtcSts
    connect FltInj.FltInj_u08 -> HwAgCorrln.FltInj_u08
    connect GateDrv0Ctrl.DiagcStsIvtr1Inactv -> LoaMgr.DiagcStsIvtr1Inactv
    connect HwAg1Meas.HwAg1 -> HwAgArbn.HwAgA
    connect HwAg1Meas.HwAg1Qlfr -> HwAgArbn.HwAgAQlfr
    connect HwAg1Meas.HwAg1RollgCntr -> HwAgArbn.HwAgARollgCntr
    connect HwAg1Meas.HwAg1Qlfr -> HwAgCorrln.HwAgAQlfr
    connect HwAg1Meas.HwAg1RollgCntr -> HwAgCorrln.HwAgARollgCntr
    connect HwAgCorrln.HwAgCorrlnSt -> HwAgArbn.HwAgCorrlnSt
    connect HwAgCorrln.HwAgIdptSig -> HwAgSysArbn.HwAgIdptSig
    connect HwTqCorrln.HwTqIdptSig -> LoaMgr.HwTqIdptSig
    connect ImcArbn.GetSigImcData_logl -> DualCtrlrOutpMgr.GetSigImcData_logl
    connect ImcSigArbn.ImcSysSt -> DualCtrlrOutpMgr.ImcSysSt
    connect LoaMgr.HwTqLoaMtgtnEna -> AssiSumLim.HwTqLoaMtgtnEna
    connect LoaMgr.LoaSt -> MotTqTranlDampg.LoaSt
    connect LoaMgr.LoaRateLim -> StOutpCtrl.LoaRateLim
    connect LoaMgr.LoaSca -> StOutpCtrl.LoaSca
    connect LoaMgr.LoaSt -> SysPrfmncSts.LoaSt
    connect LoaMgr.MotAgLoaMtgtnEna -> TqLoa.MotAgLoaMtgtnEna
    connect MotAgCorrln.MotAgMeclIdptSig -> LoaMgr.MotAgMeclIdptSig
    connect MotRefMdl.MotCurrDaxCmd -> ElecPwrCns.MotCurrDaxCmd
    connect MotRefMdl.MotCurrQaxCmd -> ElecPwrCns.MotCurrQaxCmd
    connect SysStMod.SysSt -> DualCtrlrOutpMgr.SysSt
    connect TqLoa.TqLoaAvl -> LoaMgr.TqLoaAvl
    connect CDD_FordT3T6McuCfg.EcuT -> EcuTMeas.EcuT
    connect CDD_FordT3T6McuCfg.EcuTAdcFaild -> EcuTMeas.EcuTAdcFaild
    connect CDD_NxtrTi.GetRefTmr1MicroSec32bit -> CDD_HwTq1Meas.GetRefTmr1MicroSec32bit
    connect CDD_NxtrTi.GetTiSpan1MicroSec32bit -> CDD_HwTq1Meas.GetTiSpan1MicroSec32bit
    connect DiagcMgr.CnvSnpshtData_f32 -> EcuTMeas.CnvSnpshtData_f32
    connect DiagcMgr.CnvSnpshtData_logl -> EcuTMeas.CnvSnpshtData_logl
    connect DiagcMgrProxyAppl10.GetNtcQlfrSts10 -> CDD_HwTq1Meas.GetNtcQlfrSts
    connect DiagcMgrProxyAppl10.SetNtcSts10 -> CDD_HwTq1Meas.SetNtcSts
    connect DiagcMgrProxyAppl10.GetNtcActv10 -> EcuTMeas.GetNtcActv
    connect DiagcMgrProxyAppl10.SetNtcStsAndSnpshtData10 -> EcuTMeas.SetNtcStsAndSnpshtData
    connect DiagcMgrProxyAppl10.SetNtcStsAndSnpshtData10 -> GateDrv0Ctrl.SetNtcStsAndSnpshtData
    connect EcuTMeas.EcuTFild -> CmnMfgSrv.EcuTFild
    connect EcuTMeas.EcuTFild -> DiagcMgr.EcuTFild
    connect EcuTMeas.DiagcStsLimdTPrfmnc -> DutyCycThermProtn.DiagcStsLimdTPrfmnc
    connect EcuTMeas.EcuTFild -> DutyCycThermProtn.EcuTFild
    connect EcuTMeas.EcuTFild -> SysPrfmncSts.EcuTFild
    connect EcuTMeas.EcuTFild -> TEstimn.EcuTFild
    connect CDD_FordT3T6McuCfg.MotAg2Cos -> CDD_MotCtrlMgr.MotAg2Cos
    connect CDD_FordT3T6McuCfg.MotAg2CosAdcFaild -> CDD_MotCtrlMgr.MotAg2CosAdcFaild
    connect CDD_FordT3T6McuCfg.MotAg2Sin -> CDD_MotCtrlMgr.MotAg2Sin
    connect CDD_FordT3T6McuCfg.MotAg2SinAdcFaild -> CDD_MotCtrlMgr.MotAg2SinAdcFaild
    connect CDD_FordT3T6McuCfg.MotAg5CosAdcFaild -> CDD_MotCtrlMgr.MotAg5CosAdcFaild
    connect CDD_FordT3T6McuCfg.MotAg5SinAdcFaild -> CDD_MotCtrlMgr.MotAg5SinAdcFaild
    connect CDD_FordT3T6McuCfg.MotAg6CosAdcFaild -> CDD_MotCtrlMgr.MotAg6CosAdcFaild
    connect CDD_FordT3T6McuCfg.MotAg6SinAdcFaild -> CDD_MotCtrlMgr.MotAg6SinAdcFaild
    connect EcuTMeas.EcuTFild -> CDD_MotCtrlMgr.EcuTFild
    connect GateDrv0Ctrl.IvtrFetFltPha -> CDD_MotCtrlMgr.IvtrFetFltPha
    connect GateDrv0Ctrl.IvtrFetFltTyp -> CDD_MotCtrlMgr.IvtrFetFltTyp
    connect NvMProxy.PSProxy_Rte_NvmBlock_CDD_HwTq1Meas_HwTq1Offs -> CDD_HwTq1Meas.HwTq1Offs
    connect CDD_CurrMeas.CurrMeasGainReadReqSngIvtr -> CmnMfgSrv.CurrMeasGainReadReqSngIvtr
    connect CDD_CurrMeas.CurrMeasGainWrReqSngIvtr -> CmnMfgSrv.CurrMeasGainWrReqSngIvtr
    connect CDD_CurrMeas.CurrMeasOffsReadReqSngIvtr -> CmnMfgSrv.CurrMeasOffsReadReqSngIvtr
    connect CDD_CurrMeas.CurrMeasOffsWrReqSngIvtr -> CmnMfgSrv.CurrMeasOffsWrReqSngIvtr
    connect CDD_MotAg5Meas.MotAg5EolPrmRead -> CmnMfgSrv.MotAg5EolPrmRead
    connect CDD_MotAg5Meas.MotAg5EolPrmWr -> CmnMfgSrv.MotAg5EolPrmWr
    connect CDD_MotAg6Meas.MotAg6EolPrmRead -> CmnMfgSrv.MotAg6EolPrmRead
    connect CDD_MotAg6Meas.MotAg6EolPrmWr -> CmnMfgSrv.MotAg6EolPrmWr
    connect CDD_MotAgSwCal.SwCalGetPrm -> CmnMfgSrv.SwCalGetPrm
    connect CDD_MotAgSwCal.SwCalSetPrm -> CmnMfgSrv.SwCalSetPrm
    connect CDD_MotAgSwCal.SwCalStop -> CmnMfgSrv.SwCalStop
    connect CDD_MotAgSwCal.SwCalStrt -> CmnMfgSrv.SwCalStrt
    connect CmnMfgSrv.SwCalStsCallBack -> CDD_MotAgSwCal.SwCalStsCallBack
    connect DiagSrv.DataServices_Data_Nexteer_IoControl_FD40_Manual_Torque_Command -> Dcm.DataServices_Data_Nexteer_IoControl_FD40_Manual_Torque_Command
    connect DiagSrv.DataServices_Data_Nexteer_IoControl_FD41_Assist_Linear_Gain -> Dcm.DataServices_Data_Nexteer_IoControl_FD41_Assist_Linear_Gain
    connect DiagSrv.RoutineServices_RTN_Nexteer_F100_Request_System_State_Enable -> Dcm.RoutineServices_RTN_Nexteer_F100_Request_System_State_Enable
    connect DiagSrv.RoutineServices_RTN_Nexteer_F151_Defeat_Loss_of_Assist_Scale -> Dcm.RoutineServices_RTN_Nexteer_F151_Defeat_Loss_of_Assist_Scale
    connect DiagSrv.RoutineServices_RTN_Nexteer_FD81_Handwheel_Angle_1_Auto_Trim -> Dcm.RoutineServices_RTN_Nexteer_FD81_Handwheel_Angle_1_Auto_Trim
    connect DiagSrv.RoutineServices_RTN_Nexteer_FD85_Handwheel_Angle_1_Clear_Trim -> Dcm.RoutineServices_RTN_Nexteer_FD85_Handwheel_Angle_1_Clear_Trim
    connect DiagSrv.RoutineServices_RTN_Nexteer_FDA0_Handwheel_Torque_Sensor_0_Auto_Trim -> Dcm.RoutineServices_RTN_Nexteer_FDA0_Handwheel_Torque_Sensor_0_Auto_Trim
    connect DiagSrv.RoutineServices_RTN_Nexteer_FDA1_Handwheel_Torque_Sensor_1_Auto_Trim -> Dcm.RoutineServices_RTN_Nexteer_FDA1_Handwheel_Torque_Sensor_1_Auto_Trim
    connect DiagSrv.RoutineServices_RTN_Nexteer_FDA8_Handwheel_Torque_Sensor_0_Clear_Trim -> Dcm.RoutineServices_RTN_Nexteer_FDA8_Handwheel_Torque_Sensor_0_Clear_Trim
    connect DiagSrv.RoutineServices_RTN_Nexteer_FDA9_Handwheel_Torque_Sensor_1_Clear_Trim -> Dcm.RoutineServices_RTN_Nexteer_FDA9_Handwheel_Torque_Sensor_1_Clear_Trim
    connect DiagSrv.RoutineServices_RTN_Nexteer_FDC2_Software_Based_Motor_Calibration -> Dcm.RoutineServices_RTN_Nexteer_FDC2_Software_Based_Motor_Calibration
    connect DiagSrv.RoutineServices_RTN_Nexteer_FE20_Motor_Velocity_Control -> Dcm.RoutineServices_RTN_Nexteer_FE20_Motor_Velocity_Control
    connect AssiSumLim.SetManTqCmd -> MotVelCtrl.SetManTqCmd
    connect CDD_NxtrTi.GetRefTmr100MicroSec32bit -> MotVelCtrl.GetRefTmr100MicroSec32bit
    connect CDD_NxtrTi.GetTiSpan100MicroSec32bit -> MotVelCtrl.GetTiSpan100MicroSec32bit
    connect MotAg2Meas.MotAg2MeasEolPrmRead -> CmnMfgSrv.MotAgMeasEolPrmRead
    connect MotAg2Meas.MotAg2MeasEolPrmWr -> CmnMfgSrv.MotAgMeasEolPrmWr
    connect MotVelCtrl.GetCtrlPrm -> CmnMfgSrv.GetCtrlPrm
    connect MotVelCtrl.SetCtrlPrm -> CmnMfgSrv.SetCtrlPrm
    connect MotVelCtrl.StopCtrl -> CmnMfgSrv.StopCtrl
    connect MotVelCtrl.StrtCtrl -> CmnMfgSrv.StrtCtrl
    connect CDD_NxtrTi.GetRefTmr1MicroSec32bit -> CDD_HwTq8Meas.GetRefTmr1MicroSec32bit
    connect CDD_NxtrTi.GetTiSpan1MicroSec32bit -> CDD_HwTq8Meas.GetTiSpan1MicroSec32bit
    connect DiagcMgr.CnvSnpshtData_u08 -> CDD_HwTq8Meas.CnvSnpshtData_u08
    connect DiagcMgrProxyAppl10.GetNtcQlfrSts10 -> CDD_HwTq8Meas.GetNtcQlfrSts
    connect DiagcMgrProxyAppl10.SetNtcStsAndSnpshtData10 -> CDD_HwTq8Meas.SetNtcStsAndSnpshtData
    connect FltInj.FltInj_f32 -> CDD_HwTq8Meas.FltInj_f32
    connect FltInj.FltInj_u08 -> CDD_HwTq8Meas.FltInj_u08
    connect NvMProxy.PSProxy_Rte_NvmBlock_CDD_HwTq8Meas_HwTq8Offs -> CDD_HwTq8Meas.HwTq8Offs
    connect HwAgSysArbn.PinionAgConf -> EotLrng.HwAgAuthy
    connect HwAgSysArbn.PinionAgConf -> EotProtn.HwAgAuthy
    connect HwAgSysArbn.PinionAgConf -> Rtn.HwAgAuthySca
    connect HwAgSysArbn.PinionAgConf -> SysFricLrng.HwAgAuthy
    connect HwAgSysArbn.PinionAgConf -> VehSpdLimr.HwAgAuthy
    connect HwAgSysArbn.HwAgFinal -> CmnMfgSrv.HwAg
    connect PwrLimr.MotTqCmdPwrLimd -> MotTqCmdSca.MotTqCmdMrf
    connect DiagSrv.RoutineServices_RTN_Nexteer_F119_Defeat_Duty_Cycle_Thermal_Protection -> Dcm.RoutineServices_RTN_Nexteer_F119_Defeat_Duty_Cycle_Thermal_Protection
    connect CDD_CurrMeas.MotCurrEolCalSt -> CDD_GtmCfgAndUse.MotCurrEolCalSt
    connect CDD_GtmCfgAndUse.PhaOnTiMeasdA -> GateDrv0Ctrl.PhaOnTiMeasdA
    connect CDD_GtmCfgAndUse.PhaOnTiMeasdB -> GateDrv0Ctrl.PhaOnTiMeasdB
    connect CDD_GtmCfgAndUse.PhaOnTiMeasdC -> GateDrv0Ctrl.PhaOnTiMeasdC
    connect IoHwAb.SetFctGpioPhaALowrCmd -> CDD_GtmCfgAndUse.IoHwAb_SetFctGpioPhaALowrCmd
    connect IoHwAb.SetFctGpioPhaAUpprCmd -> CDD_GtmCfgAndUse.IoHwAb_SetFctGpioPhaAUpprCmd
    connect IoHwAb.SetFctGpioPhaBLowrCmd -> CDD_GtmCfgAndUse.IoHwAb_SetFctGpioPhaBLowrCmd
    connect IoHwAb.SetFctGpioPhaBUpprCmd -> CDD_GtmCfgAndUse.IoHwAb_SetFctGpioPhaBUpprCmd
    connect IoHwAb.SetFctGpioPhaCLowrCmd -> CDD_GtmCfgAndUse.IoHwAb_SetFctGpioPhaCLowrCmd
    connect IoHwAb.SetFctGpioPhaCUpprCmd -> CDD_GtmCfgAndUse.IoHwAb_SetFctGpioPhaCUpprCmd
    connect IoHwAb.SetFctPeriphPhaALowrCmd -> CDD_GtmCfgAndUse.IoHwAb_SetFctPeriphPhaALowrCmd
    connect IoHwAb.SetFctPeriphPhaAUpprCmd -> CDD_GtmCfgAndUse.IoHwAb_SetFctPeriphPhaAUpprCmd
    connect IoHwAb.SetFctPeriphPhaBLowrCmd -> CDD_GtmCfgAndUse.IoHwAb_SetFctPeriphPhaBLowrCmd
    connect IoHwAb.SetFctPeriphPhaBUpprCmd -> CDD_GtmCfgAndUse.IoHwAb_SetFctPeriphPhaBUpprCmd
    connect IoHwAb.SetFctPeriphPhaCLowrCmd -> CDD_GtmCfgAndUse.IoHwAb_SetFctPeriphPhaCLowrCmd
    connect IoHwAb.SetFctPeriphPhaCUpprCmd -> CDD_GtmCfgAndUse.IoHwAb_SetFctPeriphPhaCUpprCmd
    connect IoHwAb.SetGpioPhaALowrCmd -> CDD_GtmCfgAndUse.IoHwAb_SetGpioPhaALowrCmd
    connect IoHwAb.SetGpioPhaAUpprCmd -> CDD_GtmCfgAndUse.IoHwAb_SetGpioPhaAUpprCmd
    connect IoHwAb.SetGpioPhaBLowrCmd -> CDD_GtmCfgAndUse.IoHwAb_SetGpioPhaBLowrCmd
    connect IoHwAb.SetGpioPhaBUpprCmd -> CDD_GtmCfgAndUse.IoHwAb_SetGpioPhaBUpprCmd
    connect IoHwAb.SetGpioPhaCLowrCmd -> CDD_GtmCfgAndUse.IoHwAb_SetGpioPhaCLowrCmd
    connect IoHwAb.SetGpioPhaCUpprCmd -> CDD_GtmCfgAndUse.IoHwAb_SetGpioPhaCUpprCmd
    connect SysStMod.SysSt -> CDD_GtmCfgAndUse.SysSt
    connect CDD_CurrMeas.MotCurrEolCalSt -> CDD_MotCtrlMgr.MotCurrEolCalSt
    connect PolarityCfg.MotAgMecl5Polarity -> CDD_MotCtrlMgr.MotAgMecl5Polarity
    connect PolarityCfg.MotAgMecl6Polarity -> CDD_MotCtrlMgr.MotAgMecl6Polarity
    connect StOutpCtrl.SysStReqDi -> SysStMod.SysStReqDi
    connect EotProtn.EotDampgCmd -> EotProtnFwl.EotDampgCmd
    connect GateDrv0Ctrl.IvtrFetFltTyp -> LoaMgr.IvtrFetFltTyp
    connect LoaMgr.MotAndThermProtnLoaMod -> DualCtrlrOutpMgr.MotAndThermProtnLoaMod
    connect CDD_MotCtrlMgr.MotVltgDax -> ElecPwrCns.MotVltgDax
    connect CDD_MotCtrlMgr.MotVltgQax -> ElecPwrCns.MotVltgQax
    connect LoaMgr.MotAndThermProtnLoaMod -> CDD_MotCtrlMgr.MotAndThermProtnLoaMod
    connect LoaMgr.MotAndThermProtnLoaMod -> DutyCycThermProtn.MotAndThermProtnLoaMod
    connect LoaMgr.MotAndThermProtnLoaMod -> ElecPwrCns.MotAndThermProtnLoaMod
    connect LoaMgr.MotAndThermProtnLoaMod -> HiLoadStallLimr.MotAndThermProtnLoaMod
    connect LoaMgr.MotAndThermProtnLoaMod -> MotCtrlPrmEstimn.MotAndThermProtnLoaMod
    connect LoaMgr.MotAndThermProtnLoaMod -> MotCurrPeakEstimn.MotAndThermProtnLoaMod
    connect LoaMgr.MotAndThermProtnLoaMod -> MotCurrRegCfg.MotAndThermProtnLoaMod
    connect LoaMgr.MotAndThermProtnLoaMod -> MotRefMdl.MotAndThermProtnLoaMod
    connect LoaMgr.MotAndThermProtnLoaMod -> PwrLimr.MotAndThermProtnLoaMod
    connect CDD_NxtrTi.GetRefTmr100MicroSec32bit -> FordMsg167BusHiSpd.GetRefTmr100MicroSec32bit
    connect CDD_NxtrTi.GetTiSpan100MicroSec32bit -> FordMsg167BusHiSpd.GetTiSpan100MicroSec32bit
    connect CDD_NxtrTi.GetRefTmr100MicroSec32bit -> FordMsg217BusHiSpd.GetRefTmr100MicroSec32bit
    connect CDD_NxtrTi.GetTiSpan100MicroSec32bit -> FordMsg217BusHiSpd.GetTiSpan100MicroSec32bit
    connect CDD_NxtrTi.GetRefTmr100MicroSec32bit -> FordMsg3B3BusHiSpd.GetRefTmr100MicroSec32bit
    connect CDD_NxtrTi.GetTiSpan100MicroSec32bit -> FordMsg3B3BusHiSpd.GetTiSpan100MicroSec32bit
    connect CDD_NxtrTi.GetRefTmr100MicroSec32bit -> FordMsg40ABusHiSpd.GetRefTmr100MicroSec32bit
    connect CDD_NxtrTi.GetTiSpan100MicroSec32bit -> FordMsg40ABusHiSpd.GetTiSpan100MicroSec32bit
    connect CDD_NxtrTi.GetRefTmr100MicroSec32bit -> FordMsg415BusHiSpd.GetRefTmr100MicroSec32bit
    connect CDD_NxtrTi.GetTiSpan100MicroSec32bit -> FordMsg415BusHiSpd.GetTiSpan100MicroSec32bit
    connect CDD_NxtrTi.GetRefTmr100MicroSec32bit -> FordMsg41ABusHiSpd.GetRefTmr100MicroSec32bit
    connect CDD_NxtrTi.GetTiSpan100MicroSec32bit -> FordMsg41ABusHiSpd.GetTiSpan100MicroSec32bit
    connect CDD_NxtrTi.GetRefTmr100MicroSec32bit -> FordMsg41EBusHiSpd.GetRefTmr100MicroSec32bit
    connect CDD_NxtrTi.GetTiSpan100MicroSec32bit -> FordMsg41EBusHiSpd.GetTiSpan100MicroSec32bit
    connect CDD_NxtrTi.GetRefTmr100MicroSec32bit -> FordMsg430BusHiSpd.GetRefTmr100MicroSec32bit
    connect CDD_NxtrTi.GetTiSpan100MicroSec32bit -> FordMsg430BusHiSpd.GetTiSpan100MicroSec32bit
    connect DiagcMgr.ClrDiagcFlgProxy -> FordMsg167BusHiSpd.ClrDiagcFlgProxy
    connect DiagcMgr.ClrDiagcFlgProxy -> FordMsg217BusHiSpd.ClrDiagcFlgProxy
    connect DiagcMgr.ClrDiagcFlgProxy -> FordMsg3B3BusHiSpd.ClrDiagcFlgProxy
    connect DiagcMgr.ClrDiagcFlgProxy -> FordMsg40ABusHiSpd.ClrDiagcFlgProxy
    connect DiagcMgr.ClrDiagcFlgProxy -> FordMsg415BusHiSpd.ClrDiagcFlgProxy
    connect DiagcMgr.ClrDiagcFlgProxy -> FordMsg41ABusHiSpd.ClrDiagcFlgProxy
    connect DiagcMgr.ClrDiagcFlgProxy -> FordMsg41EBusHiSpd.ClrDiagcFlgProxy
    connect DiagcMgrProxyAppl10.SetNtcSts10 -> FordMsg167BusHiSpd.SetNtcSts
    connect DiagcMgrProxyAppl10.SetNtcSts10 -> FordMsg217BusHiSpd.SetNtcSts
    connect DiagcMgrProxyAppl10.SetNtcSts10 -> FordMsg3B3BusHiSpd.SetNtcSts
    connect DiagcMgrProxyAppl10.SetNtcSts10 -> FordMsg40ABusHiSpd.SetNtcSts
    connect DiagcMgrProxyAppl10.SetNtcSts10 -> FordMsg415BusHiSpd.SetNtcSts
    connect DiagcMgrProxyAppl10.SetNtcSts10 -> FordMsg41ABusHiSpd.SetNtcSts
    connect DiagcMgrProxyAppl10.SetNtcSts10 -> FordMsg41EBusHiSpd.SetNtcSts
    connect DiagcMgrProxyAppl10.SetNtcSts10 -> FordMsg430BusHiSpd.SetNtcSts
    delegate FordMsg082BusHiSpd.Ford_DrvSteActv_B_Stat1 <-> outer port Ford_DrvSteActv_B_Stat
    delegate FordMsg167BusHiSpd.Ford_ElPw_D_Stat1 <-> outer port Ford_ElPw_D_Stat
    delegate FordMsg167BusHiSpd.Ford_ElPw_D_StatStrtStop1 <-> outer port Ford_ElPw_D_StatStrtStop
    delegate FordMsg082BusHiSpd.Ford_EPAS_Failure1 <-> outer port Ford_EPAS_Failure
    delegate FordMsg417BusHiSpd.Ford_EsaOn_B_Stat1 <-> outer port Ford_EsaOn_B_Stat
    delegate FordMsg3B3BusHiSpd.Ford_Ignition_Status1 <-> outer port Ford_Ignition_Status
    delegate FordMsg417BusHiSpd.Ford_LatCtlLim_D_Stat1 <-> outer port Ford_LatCtlLim_D_Stat
    delegate FordMsg417BusHiSpd.Ford_LatCtlSte_D_Stat1 <-> outer port Ford_LatCtlSte_D_Stat
    delegate FordMsg415BusHiSpd.Ford_LsmcBrkDecel_D_Stat1 <-> outer port Ford_LsmcBrkDecel_D_Stat
    delegate FordMsg167BusHiSpd.Ford_PrplWhlTot2_Tq_Actl <-> outer port Ford_PrplWhlTot2_Tq_Actl
    delegate FordMsg167BusHiSpd.Ford_PwPckTq_D_Stat1 <-> outer port Ford_PwPckTq_D_Stat
    delegate FordMsg082BusHiSpd.Ford_SAPPAngleControlStat{1..6}_1 <-> outer port Ford_SAPPAngleControlStat{1..6}
    delegate FordMsg417BusHiSpd.Ford_SelDrvMdeSte_D_Stat1 <-> outer port Ford_SelDrvMdeSte_D_Stat
    delegate FordMsg082BusHiSpd.Ford_SteeringColumnTorque <-> outer port Ford_SteeringColumnTorque
    delegate FordMsg082BusHiSpd.Ford_SteMdule_D_Stat1 <-> outer port Ford_SteMdule_D_Stat
    delegate FordMsg082BusHiSpd.Ford_SteMdule_I_Est <-> outer port Ford_SteMdule_I_Est
    delegate FordMsg082BusHiSpd.Ford_SteMdule_U_Meas <-> outer port Ford_SteMdule_U_Meas
    delegate FordMsg07EBusHiSpd.Ford_StePinAn_No_Cnt <-> outer port Ford_StePinAn_No_Cnt
    delegate FordMsg07EBusHiSpd.Ford_StePinAn_No_Cs <-> outer port Ford_StePinAn_No_Cs
    delegate FordMsg07EBusHiSpd.Ford_StePinComp_An_Est <-> outer port Ford_StePinComp_An_Est
    delegate FordMsg07EBusHiSpd.Ford_StePinCompAnEst_D_Qf <-> outer port Ford_StePinCompAnEst_D_Qf
    delegate FordMsg07EBusHiSpd.Ford_StePinRelInit_An_Sns <-> outer port Ford_StePinRelInit_An_Sns
    delegate FordMsg07EBusHiSpd.Ford_StePw_B_Rq <-> outer port Ford_StePw_B_Rq
    delegate FordMsg082BusHiSpd.Ford_TrlrHitchLamp_D_Rqst1 <-> outer port Ford_TrlrHitchLamp_D_Rqst
    delegate FordMsg415BusHiSpd.Ford_Veh_V_ActlBrk <-> outer port Ford_Veh_V_ActlBrk
    delegate FordMsg082BusHiSpd.Ford_Veh_V_RqMxTrlrAid <-> outer port Ford_Veh_V_RqMxTrlrAid
    delegate FordMsg415BusHiSpd.Ford_VehVActlBrk_D_Qf1 <-> outer port Ford_VehVActlBrk_D_Qf
    delegate FordMsg415BusHiSpd.Ford_VehVActlBrk_No_Cnt <-> outer port Ford_VehVActlBrk_No_Cnt
    delegate FordMsg415BusHiSpd.Ford_VehVActlBrk_No_Cs <-> outer port Ford_VehVActlBrk_No_Cs
    delegate FordMsg082BusHiSpd.Ford_VehVTrlrAid_B_Rq1 <-> outer port Ford_VehVTrlrAid_B_Rq
    connect CDD_EcmOutpAndDiagc.CtrlErrOut -> TmplMonr.CtrlErrOut
    connect CDD_ExcpnHndlg.GetMcuDiagcSpplData -> DiagcMgr.GetMcuDiagcSpplData
    connect CDD_FlsMem.SwApplCrc -> DiagcMgr.SwApplCrc
    connect CDD_FlsMem.CodFlsCrcChkCmpl -> PwrUpSeq.CodFlsCrcChkCmpl
    connect CDD_NxtrTi.GetTiSpan100MicroSec32bit -> CDD_FlsMem.GetTiSpan100MicroSec32bit
    connect CDD_SyncCrc.ResvCrcHwUnit -> CDD_FlsMem.ResvCrcHwUnit
    connect DiagcMgrProxyAppl10.SetNtcSts10 -> CDD_ExcpnHndlg.SetNtcSts
    connect DiagcMgrProxyAppl10.SetNtcStsAndSnpshtData10 -> CDD_ExcpnHndlg.SetNtcStsAndSnpshtData
    connect DiagcMgrProxyAppl10.SetNtcSts10 -> CDD_FlsMem.SetNtcSts
    connect DiagcMgrProxyAppl10.SetNtcSts10 -> CDD_RamMem.SetNtcSts
    connect LoaMgr.MotAndThermProtnLoaMod -> TEstimn.MotAndThermProtnLoaMod
    connect NvMProxy.PSProxy_Rte_NvmBlock_TEstimn_TFilStVal -> TEstimn.TFilStVal
    connect CDD_NxtrTi.GetRefTmr100MicroSec32bit -> FordMsg202BusHiSpd.GetRefTmr100MicroSec32bit
    connect CDD_NxtrTi.GetTiSpan100MicroSec32bit -> FordMsg202BusHiSpd.GetTiSpan100MicroSec32bit
    connect CDD_NxtrTi.GetRefTmr100MicroSec32bit -> FordMsg414BusHiSpd.GetRefTmr100MicroSec32bit
    connect CDD_NxtrTi.GetTiSpan100MicroSec32bit -> FordMsg414BusHiSpd.GetTiSpan100MicroSec32bit
    connect DiagcMgr.ClrDiagcFlgProxy -> FordMsg202BusHiSpd.ClrDiagcFlgProxy
    connect DiagcMgrProxyAppl10.SetNtcSts10 -> FordMsg202BusHiSpd.SetNtcSts
    delegate FordMsg082BusHiSpd.Ford_DrvSte_Tq_Actl <-> outer port Ford_DrvSte_Tq_Actl
    delegate FordMsg202BusHiSpd.Ford_GearRvrse_D_Actl1 <-> outer port Ford_GearRvrse_D_Actl
    delegate FordMsg3B3BusHiSpd.Ford_LifeCycMde_D_Actl1 <-> outer port Ford_LifeCycMde_D_Actl
    delegate FordMsg430BusHiSpd.Ford_OdometerMasterValue <-> outer port Ford_OdometerMasterValue
    delegate FordMsg41EBusHiSpd.Ford_SelDrvMdeChassis2_D_Rq1 <-> outer port Ford_SelDrvMdeChassis2_D_Rq
    delegate FordMsg414BusHiSpd.Ford_StePinOffst_An_Est <-> outer port Ford_StePinOffst_An_Est
    delegate FordMsg414BusHiSpd.Ford_StePinOffst_D_Stat <-> outer port Ford_StePinOffst_D_Stat
    delegate FordMsg414BusHiSpd.Ford_StePinOffst_No_Cnt <-> outer port Ford_StePinOffst_No_Cnt
    delegate FordMsg414BusHiSpd.Ford_StePinOffst_No_Cs <-> outer port Ford_StePinOffst_No_Cs
    delegate FordMsg417BusHiSpd.Ford_TrlrAidEnbl_D2_Stat1 <-> outer port Ford_TrlrAidEnbl_D2_Stat
    delegate FordMsg417BusHiSpd.Ford_TrlrAidMsgTxt_D2_Rq1 <-> outer port Ford_TrlrAidMsgTxt_D2_Rq
    delegate FordMsg202BusHiSpd.Ford_Veh_V_ActlEng <-> outer port Ford_Veh_V_ActlEng
    delegate FordMsg40ABusHiSpd.Ford_VehGGCCData <-> outer port Ford_VehicleGGCCData
    delegate FordMsg202BusHiSpd.Ford_VehVActlEng_D_Qf1 <-> outer port Ford_VehVActlEng_D_Qf
    delegate FordMsg202BusHiSpd.Ford_VehVActlEng_No_Cnt <-> outer port Ford_VehVActlEng_No_Cnt
    delegate FordMsg202BusHiSpd.Ford_VehVActlEng_No_Cs <-> outer port Ford_VehVActlEng_No_Cs
    delegate FordMsg202BusHiSpd.Ford_VehVTrlrAid_B_Avail1 <-> outer port Ford_VehVTrlrAid_B_Avail
    delegate FordMsg217BusHiSpd.Ford_WhlFl_W_Meas <-> outer port Ford_WhlFl_W_Meas
    delegate FordMsg217BusHiSpd.Ford_WhlFr_W_Meas <-> outer port Ford_WhlFr_W_Meas
    delegate FordMsg217BusHiSpd.Ford_WhlRl_W_Meas <-> outer port Ford_WhlRl_W_Meas
    delegate FordMsg217BusHiSpd.Ford_WhlRr_W_Meas <-> outer port Ford_WhlRr_W_Meas
    connect CDD_GtmCfgAndUse.GtmGetSent1Data -> HwTq10Meas.GtmGetSent1Data
    connect CDD_GtmCfgAndUse.GtmGetSent0Data -> HwTq9Meas.GtmGetSent0Data
    connect DiagcMgrProxyAppl10.GetNtcQlfrSts10 -> HwTq10Meas.GetNtcQlfrSts
    connect DiagcMgrProxyAppl10.SetNtcSts10 -> HwTq10Meas.SetNtcSts
    connect DiagcMgrProxyAppl10.SetNtcStsAndSnpshtData10 -> HwTq10Meas.SetNtcStsAndSnpshtData
    connect DiagcMgrProxyAppl10.GetNtcQlfrSts10 -> HwTq9Meas.GetNtcQlfrSts
    connect DiagcMgrProxyAppl10.SetNtcSts10 -> HwTq9Meas.SetNtcSts
    connect DiagcMgrProxyAppl10.SetNtcStsAndSnpshtData10 -> HwTq9Meas.SetNtcStsAndSnpshtData
    connect HwTq10Meas.HwTq10 -> HwTqArbn.HwTqD
    connect HwTq10Meas.HwTq10Qlfr -> HwTqArbn.HwTqDQlfr
    connect HwTq10Meas.HwTq10RollgCntr -> HwTqArbn.HwTqDRollgCntr
    connect HwTq10Meas.HwTq10 -> HwTqCorrln.HwTqD
    connect HwTq10Meas.HwTq10Qlfr -> HwTqCorrln.HwTqDQlfr
    connect HwTq10Meas.HwTq10RollgCntr -> HwTqCorrln.HwTqDRollgCntr
    connect HwTq9Meas.HwTq9 -> HwTqArbn.HwTqC
    connect HwTq9Meas.HwTq9Qlfr -> HwTqArbn.HwTqCQlfr
    connect HwTq9Meas.HwTq9RollgCntr -> HwTqArbn.HwTqCRollgCntr
    connect HwTq9Meas.HwTq9 -> HwTqCorrln.HwTqC
    connect HwTq9Meas.HwTq9Qlfr -> HwTqCorrln.HwTqCQlfr
    connect HwTq9Meas.HwTq9RollgCntr -> HwTqCorrln.HwTqCRollgCntr
    connect PolarityCfg.HwTq3Polarity -> HwTq10Meas.HwTq10Polarity
    connect PolarityCfg.HwTq2Polarity -> HwTq9Meas.HwTq9Polarity
    connect NvMProxy.PSProxy_Rte_NvmBlock_HwTq9Meas_HwTq9Offs -> HwTq9Meas.HwTq9Offs
    connect NvMProxy.PSProxy_Rte_NvmBlock_HwTq10Meas_HwTq10Offs -> HwTq10Meas.HwTq10Offs
    connect CDD_HwTq1Meas.HwTq1 -> CmnMfgSrv.HwTq1
    connect CDD_HwTq1Meas.HwTq1MeasHwTq1AutTrim -> CmnMfgSrv.HwTq1MeasHwTq1AutTrim
    connect CDD_HwTq1Meas.HwTq1MeasHwTq1ClrTrim -> CmnMfgSrv.HwTq1MeasHwTq1ClrTrim
    connect CDD_HwTq1Meas.HwTq1MeasHwTq1ReadTrim -> CmnMfgSrv.HwTq1MeasHwTq1ReadTrim
    connect CDD_HwTq1Meas.HwTq1MeasHwTq1TrimPrfmdSts -> CmnMfgSrv.HwTq1MeasHwTq1TrimPrfmdSts
    connect CDD_HwTq1Meas.HwTq1MeasHwTq1WrTrim -> CmnMfgSrv.HwTq1MeasHwTq1WrTrim
    connect CDD_HwTq1Meas.RackLimrEotSig1Avl -> EotLrng.HwAgEotSig1Avl
    connect CDD_HwTq1Meas.RackLimrCcwEotSig1 -> EotLrng.HwAgEotSig1Ccw
    connect CDD_HwTq1Meas.RackLimrCwEotSig1 -> EotLrng.HwAgEotSig1Cw
    connect CDD_HwTq1Meas.HwTq1 -> HwTqArbn.HwTqB
    connect CDD_HwTq1Meas.HwTq1Qlfr -> HwTqArbn.HwTqBQlfr
    connect CDD_HwTq1Meas.HwTq1RollgCntr -> HwTqArbn.HwTqBRollgCntr
    connect CDD_HwTq1Meas.HwTq1 -> HwTqCorrln.HwTqB
    connect CDD_HwTq1Meas.HwTq1Qlfr -> HwTqCorrln.HwTqBQlfr
    connect CDD_HwTq1Meas.HwTq1RollgCntr -> HwTqCorrln.HwTqBRollgCntr
    connect CDD_HwTq8Meas.HwTq8 -> CmnMfgSrv.HwTq0
    connect CDD_HwTq8Meas.HwTq8AutTrim -> CmnMfgSrv.HwTq0MeasHwTq0AutTrim
    connect CDD_HwTq8Meas.HwTq8ClrTrim -> CmnMfgSrv.HwTq0MeasHwTq0ClrTrim
    connect CDD_HwTq8Meas.HwTq8ReadTrim -> CmnMfgSrv.HwTq0MeasHwTq0ReadTrim
    connect CDD_HwTq8Meas.HwTq8TrimPrfmdSts -> CmnMfgSrv.HwTq0MeasHwTq0TrimPrfmdSts
    connect CDD_HwTq8Meas.HwTq8WrTrim -> CmnMfgSrv.HwTq0MeasHwTq0WrTrim
    connect CDD_HwTq8Meas.RackLimrEotSig8Avl -> EotLrng.HwAgEotSig0Avl
    connect CDD_HwTq8Meas.RackLimrCcwEotSig8 -> EotLrng.HwAgEotSig0Ccw
    connect CDD_HwTq8Meas.RackLimrCwEotSig8 -> EotLrng.HwAgEotSig0Cw
    connect CDD_HwTq8Meas.HwTq8 -> HwTqArbn.HwTqA
    connect CDD_HwTq8Meas.HwTq8Qlfr -> HwTqArbn.HwTqAQlfr
    connect CDD_HwTq8Meas.HwTq8RollgCntr -> HwTqArbn.HwTqARollgCntr
    connect CDD_HwTq8Meas.HwTq8 -> HwTqCorrln.HwTqA
    connect CDD_HwTq8Meas.HwTq8Qlfr -> HwTqCorrln.HwTqAQlfr
    connect CDD_HwTq8Meas.HwTq8RollgCntr -> HwTqCorrln.HwTqARollgCntr
    connect CDD_MotVel.MotVelCrf -> ImcArbn.MotVel
    connect CDD_SyncCrc.Calc32BitCrc_u32 -> TunSelnMngt.Calc32BitCrc_u32
    connect DiagcMgr.DiagcStsNonRcvrlReqDiFltPrsnt -> ImcArbn.DiagcStsNonRcrvlReqDiFltPrsnt
    connect DualCtrlrOutpMgr.DualEcuMotCtrlMtgtnEna -> ImcArbn.DualEcuMotCtrlMtgtnEna
    connect HwTq10Meas.HwTq10 -> CmnMfgSrv.HwTq3
    connect HwTq10Meas.HwTq10MeasHwTq10AutTrim -> CmnMfgSrv.HwTq3MeasHwTq3AutTrim
    connect HwTq10Meas.HwTq10MeasHwTq10ClrTrim -> CmnMfgSrv.HwTq3MeasHwTq3ClrTrim
    connect HwTq10Meas.HwTq10MeasHwTq10ReadTrim -> CmnMfgSrv.HwTq3MeasHwTq3ReadTrim
    connect HwTq10Meas.HwTq10MeasHwTq10TrimPrfmdSts -> CmnMfgSrv.HwTq3MeasHwTq3TrimPrfmdSts
    connect HwTq10Meas.HwTq10MeasHwTq10WrTrim -> CmnMfgSrv.HwTq3MeasHwTq3WrTrim
    connect HwTq9Meas.HwTq9 -> CmnMfgSrv.HwTq2
    connect HwTq9Meas.HwTq9MeasHwTq9AutTrim -> CmnMfgSrv.HwTq2MeasHwTq2AutTrim
    connect HwTq9Meas.HwTq9MeasHwTq9ClrTrim -> CmnMfgSrv.HwTq2MeasHwTq2ClrTrim
    connect HwTq9Meas.HwTq9MeasHwTq9ReadTrim -> CmnMfgSrv.HwTq2MeasHwTq2ReadTrim
    connect HwTq9Meas.HwTq9MeasHwTq9TrimPrfmdSts -> CmnMfgSrv.HwTq2MeasHwTq2TrimPrfmdSts
    connect HwTq9Meas.HwTq9MeasHwTq9WrTrim -> CmnMfgSrv.HwTq2MeasHwTq2WrTrim
    connect ImcSigArbn.HwTqImcCorrd -> Assi.HwTq
    connect ImcSigArbn.VehSpdImcCorrd -> Assi.VehSpd
    connect ImcSigArbn.HwTqImcCorrd -> AssiHiFrq.HwTq
    connect ImcSigArbn.VehSpdImcCorrd -> AssiHiFrq.VehSpd
    connect ImcSigArbn.VehSpdImcCorrd -> AssiSumLim.VehSpd
    connect ImcSigArbn.VehSpdImcCorrd -> CDD_CurrMeas.VehSpd
    connect ImcSigArbn.HwTqImcCorrd -> CmnMfgSrv.HwTq
    connect ImcSigArbn.HwTqImcCorrd -> CmplncErr.HwTq
    connect ImcSigArbn.HwTqImcCorrd -> Dampg.HwTq
    connect ImcSigArbn.MotVelCrfImcCorrd -> Dampg.MotVelCrf
    connect ImcSigArbn.VehSpdImcCorrd -> Dampg.VehSpd
    connect ImcSigArbn.HwTqImcCorrd -> DiagcMgr.HwTq
    connect ImcSigArbn.HwTqImcCorrd -> DrvrTqEstimn.HwTq
    connect ImcSigArbn.MotVelCrfImcCorrd -> DrvrTqEstimn.MotVelCrf
    connect ImcSigArbn.VehSpdImcCorrd -> DualCtrlrOutpMgr.VehSpd
    connect ImcSigArbn.MotVelCrfImcCorrd -> DutyCycThermProtn.MotVelCrf
    connect ImcSigArbn.HwTqImcCorrd -> EotLrng.HwTq
    connect ImcSigArbn.MotVelCrfImcCorrd -> EotLrng.MotVelCrf
    connect ImcSigArbn.HwTqImcCorrd -> EotProtn.HwTq
    connect ImcSigArbn.MotVelCrfImcCorrd -> EotProtn.MotVelCrf
    connect ImcSigArbn.VehSpdImcCorrd -> EotProtn.VehSpd
    connect ImcSigArbn.MotVelCrfImcCorrd -> EotProtnFwl.MotVelCrf
    connect ImcSigArbn.VehSpdImcCorrd -> EotProtnFwl.VehSpd
    connect ImcSigArbn.MotVelCrfImcCorrd -> HiLoadStallLimr.MotVelCrf
    connect ImcSigArbn.HwTqImcCorrd -> HwAgSnsrls.HwTq
    connect ImcSigArbn.MotVelCrfImcCorrd -> HwAgSnsrls.MotVelCrf
    connect ImcSigArbn.VehSpdImcCorrd -> HwAgSnsrls.VehSpd
    connect ImcSigArbn.HwTqImcCorrd -> HwAgSysArbn.HwTq
    connect ImcSigArbn.MotVelCrfImcCorrd -> HwAgSysArbn.MotVelCrf
    connect ImcSigArbn.HwTqImcCorrd -> HysCmp.HwTq
    connect ImcSigArbn.VehSpdImcCorrd -> HysCmp.VehSpd
    connect ImcSigArbn.HwTqImcCorrd -> InertiaCmpVel.HwTq
    connect ImcSigArbn.MotVelCrfImcCorrd -> InertiaCmpVel.MotVelCrf
    connect ImcSigArbn.VehSpdImcCorrd -> InertiaCmpVel.VehSpd
    connect ImcSigArbn.VehSpdImcCorrd -> LimrCdng.VehSpd
    connect ImcSigArbn.VehSpdImcCorrd -> MotCurrRegCfg.VehSpd
    connect ImcSigArbn.MotVelCrfImcCorrd -> MotTqTranlDampg.MotVelCrf
    connect ImcSigArbn.VehSpdImcCorrd -> MotTqTranlDampg.VehSpd
    connect ImcSigArbn.MotVelCrfImcCorrd -> MotVelCtrl.MotVelCrf
    connect ImcSigArbn.HwTqImcCorrd -> PosnTrakgServo.HwTq
    connect ImcSigArbn.MotVelCrfImcCorrd -> PosnTrakgServo.MotVelCrf
    connect ImcSigArbn.VehSpdImcCorrd -> PosnTrakgServo.VehSpd
    connect ImcSigArbn.HwTqImcCorrd -> Rtn.HwTq
    connect ImcSigArbn.VehSpdImcCorrd -> Rtn.VehSpd
    connect ImcSigArbn.VehSpdImcCorrd -> RtnPahFwl.VehSpd
    connect ImcSigArbn.HwTqImcCorrd -> StabyCmp.HwTq
    connect ImcSigArbn.VehSpdImcCorrd -> StabyCmp.VehSpd
    connect ImcSigArbn.HwTqImcCorrd -> SysFricLrng.HwTq
    connect ImcSigArbn.VehSpdImcCorrd -> SysFricLrng.VehSpd
    connect ImcSigArbn.MotVelCrfImcCorrd -> TqLoa.MotVelCrf
    connect ImcSigArbn.VehSpdImcCorrd -> TqLoa.VehSpd
    connect ImcSigArbn.HwTqImcCorrd -> TunSelnAuthy.HwTq
    connect ImcSigArbn.VehSpdImcCorrd -> TunSelnAuthy.VehSpd
    connect ImcSigArbn.VehSpdImcCorrd -> VehSpdLimr.VehSpd
    connect PolarityCfg.HwTq1Polarity -> CDD_HwTq1Meas.HwTq1Polarity
    connect PolarityCfg.HwTq0Polarity -> CDD_HwTq8Meas.HwTq8Polarity
    connect PosnTrakgServo.PosnServoIntgtrSt -> ImcArbn.PosnServoIntgtrSt
    connect Swp.HwTqSwp -> ImcArbn.HwTq
    connect Swp.HwTqSwp -> ImcSigArbn.HwTq
    connect VehSigCdng.VehSpdVld -> ImcArbn.VehSpdVld
    connect DualCtrlrOutpMgr.DualEcuMotCtrlMtgtnEna -> CDD_MotCtrlMgr.DualEcuMotCtrlMtgtnEna
    connect DualCtrlrOutpMgr.DualEcuFltMtgtnEna -> DutyCycThermProtn.DualEcuFltMtgtnEna
    connect DualCtrlrOutpMgr.DualEcuFltMtgtnEna -> HiLoadStallLimr.DualEcuFltMtgtnEna
    connect DualCtrlrOutpMgr.DualEcuFltMtgtnEna -> MotCtrlPrmEstimn.DualEcuFltMtgtnEna
    connect DualCtrlrOutpMgr.DualEcuMotCtrlMtgtnEna -> MotCurrPeakEstimn.DualEcuMotCtrlMtgtnEna
    connect DualCtrlrOutpMgr.DualEcuMotCtrlMtgtnEna -> MotCurrRegCfg.DualEcuMotCtrlMtgtnEna
    connect DualCtrlrOutpMgr.DualEcuMotCtrlMtgtnEna -> MotRefMdl.DualEcuMotCtrlMtgtnEna
    connect DualCtrlrOutpMgr.DualEcuFltMtgtnSca -> PwrLimr.DualEcuFltMtgtnSca
    connect DualCtrlrOutpMgr.DualEcuFltMtgtnEna -> TEstimn.DualEcuFltMtgtnEna
    connect CustDiag.RstReq -> ImcArbn.RstReq
    connect CustDiag.FordActvRtnEnad -> Rtn.RtnCmdDiagcDi
    connect DualEcuIdn.EcuId -> CustDiag.EcuId
    connect ImcArbn.GetSigImcData_u08 -> CustDiag.GetSigImcData_u08
    connect DiagSrv.RoutineServices_RTN_Nexteer_FDA2_Handwheel_Torque_Sensor_2_Auto_Trim -> Dcm.RoutineServices_RTN_Nexteer_FDA2_Handwheel_Torque_Sensor_2_Auto_Trim
    connect DiagSrv.RoutineServices_RTN_Nexteer_FDA3_Handwheel_Torque_Sensor_3_Auto_Trim -> Dcm.RoutineServices_RTN_Nexteer_FDA3_Handwheel_Torque_Sensor_3_Auto_Trim
    connect DiagSrv.RoutineServices_RTN_Nexteer_FDAA_Handwheel_Torque_Sensor_2_Clear_Trim -> Dcm.RoutineServices_RTN_Nexteer_FDAA_Handwheel_Torque_Sensor_2_Clear_Trim
    connect DiagSrv.RoutineServices_RTN_Nexteer_FDAB_Handwheel_Torque_Sensor_3_Clear_Trim -> Dcm.RoutineServices_RTN_Nexteer_FDAB_Handwheel_Torque_Sensor_3_Clear_Trim
    connect CustDiag.ServiceRequestNotification -> Dcm.ServiceRequestManufacturerNotification_DcmDslServiceRequestManufacturerNotification
    connect CustDiag.DataServices_DID_3003_Gear_Hardware_Part_Number -> Dcm.DataServices_DID_3003_Gear_Hardware_Part_Number
    connect CustDiag.DataServices_DID_DE00_VehicleData -> Dcm.DataServices_DID_DE00_VehicleData
    connect CustDiag.DataServices_DID_DE01_FIHSwFeatureConfig -> Dcm.DataServices_DID_DE01_FIHSwFeatureConfig
    connect CustDiag.DataServices_DID_DE02_FeatureConfig -> Dcm.DataServices_DID_DE02_FeatureConfig
    connect CustDiag.DataServices_DID_DE03_Enable_DisableDTCs -> Dcm.DataServices_DID_DE03_Enable_DisableDTCs
    connect CustDiag.DataServices_DID_DE04_PDCResetValue -> Dcm.DataServices_DID_DE04_PDCResetValue
    connect CustDiag.DataServices_DID_EE01_XCP_Enable_Disable -> Dcm.DataServices_DID_EE01_XCP_Enable_Disable
    connect CustDiag.DataServices_DID_EE02_Assist_On_Off -> Dcm.DataServices_DID_EE02_Assist_On_Off
    connect CustDiag.DataServices_DID_F10A_ECU_Cal_Config_Part_Number -> Dcm.DataServices_DID_F10A_ECU_Cal_Config_Part_Number
    connect CustDiag.DataServices_DID_F111_ECU_Core_Assembly_Number -> Dcm.DataServices_DID_F111_ECU_Core_Assembly_Number
    connect CustDiag.DataServices_DID_F113_ECU_Delivery_Assembly_Number -> Dcm.DataServices_DID_F113_ECU_Delivery_Assembly_Number
    connect CustDiag.DataServices_DID_F124_ECU_Calibration_Data_1_Number -> Dcm.DataServices_DID_F124_ECU_Calibration_Data_1_Number
    connect CustDiag.DataServices_DID_F188_Vehicle_Manufacturer_ECU_Software_Number -> Dcm.DataServices_DID_F188_Vehicle_Manufacturer_ECU_Software_Number
    connect NvMProxy.PSProxy_Rte_NvmBlock_CustDiag_Did3003 -> CustDiag.Did3003
    connect NvMProxy.PSProxy_Rte_NvmBlock_CustDiag_DidDE{00..04} -> CustDiag.DidDE{00..04}
    connect NvMProxy.PSProxy_Rte_NvmBlock_CustDiag_DidEE01 -> CustDiag.DidEE01
    connect NvMProxy.PSProxy_Rte_NvmBlock_CustDiag_DidEE02 -> CustDiag.DidEE02
    connect NvMProxy.PSProxy_Rte_NvmBlock_CustDiag_DidF111 -> CustDiag.DidF111
    connect NvMProxy.PSProxy_Rte_NvmBlock_CustDiag_DidF113 -> CustDiag.DidF113
    connect CustDiag.DataServices_DID_D100_Active_Diagnostic_Session -> Dcm.DataServices_DID_D100_Active_Diagnostic_Session
    connect CalRegn02CmnGroupA.AssiThermScaX -> Assi.AssiThermScaX
    connect CalRegn02CmnGroupA.AssiThermScaY -> Assi.AssiThermScaY
    connect CalRegn02Inin00GroupA.AssiHiFrqHpFilFrq -> AssiHiFrq.AssiHiFrqHpFilFrq
    connect CalRegn02Inin00GroupA.DampgHydAssiLim -> Dampg.DampgHydAssiLim
    connect CalRegn02Inin00GroupA.HysCmpAssiCmdLpFilFrq -> HysCmp.HysCmpAssiCmdLpFilFrq
    connect CalRegn02Inin00GroupA.HysCmpAssiInpLim -> HysCmp.HysCmpAssiInpLim
    connect CalRegn02Inin00GroupA.HysCmpFinalOutpLpFilFrq -> HysCmp.HysCmpFinalOutpLpFilFrq
    connect CalRegn02Inin00GroupA.HysCmpFricTScaX -> HysCmp.HysCmpFricTScaX
    connect CalRegn02Inin00GroupA.HysCmpFricTScaY -> HysCmp.HysCmpFricTScaY
    connect CalRegn02Inin00GroupA.HysCmpHwTqLpFilFrq -> HysCmp.HysCmpHwTqLpFilFrq
    connect CalRegn02Inin00GroupA.InertiaCmpVelAssiBasdDampgCoeffX -> InertiaCmpVel.InertiaCmpVelAssiBasdDampgCoeffX
    connect CalRegn02Inin00GroupA.InertiaCmpVelAssiBasdDampgRollgWhlImbRejctnOnY -> InertiaCmpVel.InertiaCmpVelAssiBasdDampgRollgWhlImbRejctnOnY
    connect CalRegn02Inin00GroupA.InertiaCmpVelAssiBasdDampgRollgY -> InertiaCmpVel.InertiaCmpVelAssiBasdDampgRollgY
    connect CalRegn02Inin00GroupA.InertiaCmpVelAssiBasdDampgStatWhlImbRejctnOnY -> InertiaCmpVel.InertiaCmpVelAssiBasdDampgStatWhlImbRejctnOnY
    connect CalRegn02Inin00GroupA.InertiaCmpVelCmdScaY -> InertiaCmpVel.InertiaCmpVelCmdScaY
    connect CalRegn02Inin00GroupA.InertiaCmpVelDampgDecelGain -> InertiaCmpVel.InertiaCmpVelDampgDecelGain
    connect CalRegn02Inin00GroupA.InertiaCmpVelDampgDecelGainFallSlew -> InertiaCmpVel.InertiaCmpVelDampgDecelGainFallSlew
    connect CalRegn02Inin00GroupA.InertiaCmpVelDampgDecelGainRisngSlewX -> InertiaCmpVel.InertiaCmpVelDampgDecelGainRisngSlewX
    connect CalRegn02Inin00GroupA.InertiaCmpVelDampgDecelGainRisngSlewY -> InertiaCmpVel.InertiaCmpVelDampgDecelGainRisngSlewY
    connect CalRegn02Inin00GroupA.InertiaCmpVelDampgGainOffThd -> InertiaCmpVel.InertiaCmpVelDampgGainOffThd
    connect CalRegn02Inin00GroupA.InertiaCmpVelDampgGainOnThd -> InertiaCmpVel.InertiaCmpVelDampgGainOnThd
    connect CalRegn02Inin00GroupA.InertiaCmpVelDecelGainEnaCal -> InertiaCmpVel.InertiaCmpVelDecelGainEnaCal
    connect CalRegn02Inin00GroupA.InertiaCmpVelModWhlImbRejctnBlndX -> InertiaCmpVel.InertiaCmpVelModWhlImbRejctnBlndX
    connect CalRegn02Inin00GroupA.InertiaCmpVelModWhlImbRejctnBlndY -> InertiaCmpVel.InertiaCmpVelModWhlImbRejctnBlndY
    connect CalRegn02Inin00GroupA.InertiaCmpVelMotInertia -> InertiaCmpVel.InertiaCmpVelMotInertia
    connect CalRegn02Inin00GroupA.InertiaCmpVelMotVelBasdOutpScagX -> InertiaCmpVel.InertiaCmpVelMotVelBasdOutpScagX
    connect CalRegn02Inin00GroupA.InertiaCmpVelMotVelBasdOutpScagY -> InertiaCmpVel.InertiaCmpVelMotVelBasdOutpScagY
    connect CalRegn02Inin00GroupA.InertiaCmpVelNotchBlndY -> InertiaCmpVel.InertiaCmpVelNotchBlndY
    connect CalRegn02Inin00GroupA.InertiaCmpVelNotchFilStruct -> InertiaCmpVel.InertiaCmpVelNotchFilStruct
    connect CalRegn02Inin00GroupA.InertiaCmpVelTqSnsrVelFilFrq -> InertiaCmpVel.InertiaCmpVelTqSnsrVelFilFrq
    connect CalRegn02Inin00GroupA.InertiaCmpVelTqSnsrVelSca -> InertiaCmpVel.InertiaCmpVelTqSnsrVelSca
    connect CalRegn02Rt00GroupA.AssiMotTqWhlImbRejctnMaxX -> Assi.AssiMotTqWhlImbRejctnMaxX
    connect CalRegn02Rt00GroupA.AssiMotTqWhlImbRejctnMaxY -> Assi.AssiMotTqWhlImbRejctnMaxY
    connect CalRegn02Rt00GroupA.AssiMotTqWhlImbRejctnMinX -> Assi.AssiMotTqWhlImbRejctnMinX
    connect CalRegn02Rt00GroupA.AssiMotTqWhlImbRejctnMinY -> Assi.AssiMotTqWhlImbRejctnMinY
    connect CalRegn02Rt00GroupA.AssiWhlImbRejctnBlndScaX -> Assi.AssiWhlImbRejctnBlndScaX
    connect CalRegn02Rt00GroupA.AssiWhlImbRejctnBlndScaY -> Assi.AssiWhlImbRejctnBlndScaY
    connect CalRegn02Rt00GroupA.AssiHiFrqGainY -> AssiHiFrq.AssiHiFrqGainY
    connect CalRegn02Rt00GroupA.AssiHiFrqHpFilFrqY -> AssiHiFrq.AssiHiFrqHpFilFrqY
    connect CalRegn02Rt00GroupA.AssiHiFrqTqWhlImbRejctnTqX -> AssiHiFrq.AssiHiFrqTqWhlImbRejctnTqX
    connect CalRegn02Rt00GroupA.AssiHiFrqTqX -> AssiHiFrq.AssiHiFrqTqX
    connect CalRegn02Rt00GroupA.AssiHiFrqWhlImbRejctnBlndX -> AssiHiFrq.AssiHiFrqWhlImbRejctnBlndX
    connect CalRegn02Rt00GroupA.AssiHiFrqWhlImbRejctnBlndY -> AssiHiFrq.AssiHiFrqWhlImbRejctnBlndY
    connect CalRegn02Rt00GroupA.AssiHiFrqWhlImbRejctnGainY -> AssiHiFrq.AssiHiFrqWhlImbRejctnGainY
    connect CalRegn02Rt00GroupA.DampgHwTqX -> Dampg.DampgHwTqX
    connect CalRegn02Rt00GroupA.DampgHwTqY -> Dampg.DampgHwTqY
    connect CalRegn02Rt00GroupA.DampgHydCoeff{1..4}ScaY -> Dampg.DampgHydCoeff{1..4}ScaY
    connect CalRegn02Rt00GroupA.DampgMotVelX -> Dampg.DampgMotVelX
    connect CalRegn02Rt00GroupA.DampgMotVelY -> Dampg.DampgMotVelY
    connect CalRegn02Rt00GroupA.HysCmpEffLossY -> HysCmp.HysCmpEffLossY
    connect CalRegn02Rt00GroupA.HysCmpEffOffsY -> HysCmp.HysCmpEffOffsY
    connect CalRegn02Rt00GroupA.HysCmpFricWhlImbRejctnBlndX -> HysCmp.HysCmpFricWhlImbRejctnBlndX
    connect CalRegn02Rt00GroupA.HysCmpFricWhlImbRejctnBlndY -> HysCmp.HysCmpFricWhlImbRejctnBlndY
    connect CalRegn02Rt00GroupA.HysCmpFricWhlImbRejctnOffY -> HysCmp.HysCmpFricWhlImbRejctnOffY
    connect CalRegn02Rt00GroupA.HysCmpFricWhlImbRejctnOnY -> HysCmp.HysCmpFricWhlImbRejctnOnY
    connect CalRegn02Rt00GroupA.HysCmpHwTqScaX -> HysCmp.HysCmpHwTqScaX
    connect CalRegn02Rt00GroupA.HysCmpHwTqScaY -> HysCmp.HysCmpHwTqScaY
    connect CalRegn02Rt00GroupA.HysCmpHysSatnY -> HysCmp.HysCmpHysSatnY
    connect CalRegn02Rt00GroupA.HysCmpNegHysCmpScaX -> HysCmp.HysCmpNegHysCmpScaX
    connect CalRegn02Rt00GroupA.HysCmpNegHysCmpScaY -> HysCmp.HysCmpNegHysCmpScaY
    connect CalRegn02Rt00GroupA.HysCmpNegHysCmpX -> HysCmp.HysCmpNegHysCmpX
    connect CalRegn02Rt00GroupA.HysCmpNegHysCmpY -> HysCmp.HysCmpNegHysCmpY
    connect CalRegn02Rt00GroupA.HysCmpOutpLim -> HysCmp.HysCmpOutpLim
    connect CalRegn02Rt00GroupA.HysCmpRevGain -> HysCmp.HysCmpRevGain
    connect CalRegn02Rt00GroupA.HysCmpRiseX -> HysCmp.HysCmpRiseX
    connect CalRegn02Rt00GroupA.HysCmpRiseY -> HysCmp.HysCmpRiseY
    connect CalRegn02Rt00GroupA.InertiaCmpVelAssiBasdDampgStatY -> InertiaCmpVel.InertiaCmpVelAssiBasdDampgStatY
    connect CalRegn02Rt00GroupA.InertiaCmpVelDampgFilFrq -> InertiaCmpVel.InertiaCmpVelDampgFilFrq
    connect CalRegn02Rt00GroupA.InertiaCmpVelDampgFilFrqWhlImbRejctnOn -> InertiaCmpVel.InertiaCmpVelDampgFilFrqWhlImbRejctnOn
    connect CalRegn02Rt00GroupA.InertiaCmpVelDampgSpdBlndY -> InertiaCmpVel.InertiaCmpVelDampgSpdBlndY
    connect CalRegn02Rt00GroupA.InertiaCmpVelDampgWhlImbRejctnBlndX -> InertiaCmpVel.InertiaCmpVelDampgWhlImbRejctnBlndX
    connect CalRegn02Rt00GroupA.InertiaCmpVelDampgWhlImbRejctnBlndY -> InertiaCmpVel.InertiaCmpVelDampgWhlImbRejctnBlndY
    connect CalRegn02Rt01GroupA.AssiHiFrqGainY -> AAACalRegn02Rt01GroupA_Dummy.AssiHiFrqGainY
    connect CalRegn02Rt01GroupA.AssiHiFrqHpFilFrqY -> AAACalRegn02Rt01GroupA_Dummy.AssiHiFrqHpFilFrqY
    connect CalRegn02Rt01GroupA.AssiHiFrqTqWhlImbRejctnTqX -> AAACalRegn02Rt01GroupA_Dummy.AssiHiFrqTqWhlImbRejctnTqX
    connect CalRegn02Rt01GroupA.AssiHiFrqTqX -> AAACalRegn02Rt01GroupA_Dummy.AssiHiFrqTqX
    connect CalRegn02Rt01GroupA.AssiHiFrqWhlImbRejctnBlndX -> AAACalRegn02Rt01GroupA_Dummy.AssiHiFrqWhlImbRejctnBlndX
    connect CalRegn02Rt01GroupA.AssiHiFrqWhlImbRejctnBlndY -> AAACalRegn02Rt01GroupA_Dummy.AssiHiFrqWhlImbRejctnBlndY
    connect CalRegn02Rt01GroupA.AssiHiFrqWhlImbRejctnGainY -> AAACalRegn02Rt01GroupA_Dummy.AssiHiFrqWhlImbRejctnGainY
    connect CalRegn02Rt01GroupA.AssiMotTqWhlImbRejctnMaxX -> AAACalRegn02Rt01GroupA_Dummy.AssiMotTqWhlImbRejctnMaxX
    connect CalRegn02Rt01GroupA.AssiMotTqWhlImbRejctnMaxY -> AAACalRegn02Rt01GroupA_Dummy.AssiMotTqWhlImbRejctnMaxY
    connect CalRegn02Rt01GroupA.AssiMotTqWhlImbRejctnMinX -> AAACalRegn02Rt01GroupA_Dummy.AssiMotTqWhlImbRejctnMinX
    connect CalRegn02Rt01GroupA.AssiMotTqWhlImbRejctnMinY -> AAACalRegn02Rt01GroupA_Dummy.AssiMotTqWhlImbRejctnMinY
    connect CalRegn02Rt01GroupA.AssiWhlImbRejctnBlndScaX -> AAACalRegn02Rt01GroupA_Dummy.AssiWhlImbRejctnBlndScaX
    connect CalRegn02Rt01GroupA.AssiWhlImbRejctnBlndScaY -> AAACalRegn02Rt01GroupA_Dummy.AssiWhlImbRejctnBlndScaY
    connect CalRegn02Rt01GroupA.DampgHwTqX -> AAACalRegn02Rt01GroupA_Dummy.DampgHwTqX
    connect CalRegn02Rt01GroupA.DampgHwTqY -> AAACalRegn02Rt01GroupA_Dummy.DampgHwTqY
    connect CalRegn02Rt01GroupA.DampgHydCoeff{1..4}ScaY -> AAACalRegn02Rt01GroupA_Dummy.DampgHydCoeff{1..4}ScaY
    connect CalRegn02Rt01GroupA.DampgMotVelX -> AAACalRegn02Rt01GroupA_Dummy.DampgMotVelX
    connect CalRegn02Rt01GroupA.DampgMotVelY -> AAACalRegn02Rt01GroupA_Dummy.DampgMotVelY
    connect CalRegn02Rt01GroupA.HysCmpEffLossY -> AAACalRegn02Rt01GroupA_Dummy.HysCmpEffLossY
    connect CalRegn02Rt01GroupA.HysCmpEffOffsY -> AAACalRegn02Rt01GroupA_Dummy.HysCmpEffOffsY
    connect CalRegn02Rt01GroupA.HysCmpFricWhlImbRejctnBlndX -> AAACalRegn02Rt01GroupA_Dummy.HysCmpFricWhlImbRejctnBlndX
    connect CalRegn02Rt01GroupA.HysCmpFricWhlImbRejctnBlndY -> AAACalRegn02Rt01GroupA_Dummy.HysCmpFricWhlImbRejctnBlndY
    connect CalRegn02Rt01GroupA.HysCmpFricWhlImbRejctnOffY -> AAACalRegn02Rt01GroupA_Dummy.HysCmpFricWhlImbRejctnOffY
    connect CalRegn02Rt01GroupA.HysCmpFricWhlImbRejctnOnY -> AAACalRegn02Rt01GroupA_Dummy.HysCmpFricWhlImbRejctnOnY
    connect CalRegn02Rt01GroupA.HysCmpHwTqScaX -> AAACalRegn02Rt01GroupA_Dummy.HysCmpHwTqScaX
    connect CalRegn02Rt01GroupA.HysCmpHwTqScaY -> AAACalRegn02Rt01GroupA_Dummy.HysCmpHwTqScaY
    connect CalRegn02Rt01GroupA.HysCmpHysSatnY -> AAACalRegn02Rt01GroupA_Dummy.HysCmpHysSatnY
    connect CalRegn02Rt01GroupA.HysCmpNegHysCmpScaX -> AAACalRegn02Rt01GroupA_Dummy.HysCmpNegHysCmpScaX
    connect CalRegn02Rt01GroupA.HysCmpNegHysCmpScaY -> AAACalRegn02Rt01GroupA_Dummy.HysCmpNegHysCmpScaY
    connect CalRegn02Rt01GroupA.HysCmpNegHysCmpX -> AAACalRegn02Rt01GroupA_Dummy.HysCmpNegHysCmpX
    connect CalRegn02Rt01GroupA.HysCmpNegHysCmpY -> AAACalRegn02Rt01GroupA_Dummy.HysCmpNegHysCmpY
    connect CalRegn02Rt01GroupA.HysCmpOutpLim -> AAACalRegn02Rt01GroupA_Dummy.HysCmpOutpLim
    connect CalRegn02Rt01GroupA.HysCmpRevGain -> AAACalRegn02Rt01GroupA_Dummy.HysCmpRevGain
    connect CalRegn02Rt01GroupA.HysCmpRiseX -> AAACalRegn02Rt01GroupA_Dummy.HysCmpRiseX
    connect CalRegn02Rt01GroupA.HysCmpRiseY -> AAACalRegn02Rt01GroupA_Dummy.HysCmpRiseY
    connect CalRegn02Rt01GroupA.InertiaCmpVelAssiBasdDampgStatY -> AAACalRegn02Rt01GroupA_Dummy.InertiaCmpVelAssiBasdDampgStatY
    connect CalRegn02Rt01GroupA.InertiaCmpVelDampgFilFrq -> AAACalRegn02Rt01GroupA_Dummy.InertiaCmpVelDampgFilFrq
    connect CalRegn02Rt01GroupA.InertiaCmpVelDampgFilFrqWhlImbRejctnOn -> AAACalRegn02Rt01GroupA_Dummy.InertiaCmpVelDampgFilFrqWhlImbRejctnOn
    connect CalRegn02Rt01GroupA.InertiaCmpVelDampgSpdBlndY -> AAACalRegn02Rt01GroupA_Dummy.InertiaCmpVelDampgSpdBlndY
    connect CalRegn02Rt01GroupA.InertiaCmpVelDampgWhlImbRejctnBlndX -> AAACalRegn02Rt01GroupA_Dummy.InertiaCmpVelDampgWhlImbRejctnBlndX
    connect CalRegn02Rt01GroupA.InertiaCmpVelDampgWhlImbRejctnBlndY -> AAACalRegn02Rt01GroupA_Dummy.InertiaCmpVelDampgWhlImbRejctnBlndY
    connect CalRegn02Rt02GroupA.AssiHiFrqGainY -> AAACalRegn02Rt02GroupA_Dummy.AssiHiFrqGainY
    connect CalRegn02Rt02GroupA.AssiHiFrqHpFilFrqY -> AAACalRegn02Rt02GroupA_Dummy.AssiHiFrqHpFilFrqY
    connect CalRegn02Rt02GroupA.AssiHiFrqTqWhlImbRejctnTqX -> AAACalRegn02Rt02GroupA_Dummy.AssiHiFrqTqWhlImbRejctnTqX
    connect CalRegn02Rt02GroupA.AssiHiFrqTqX -> AAACalRegn02Rt02GroupA_Dummy.AssiHiFrqTqX
    connect CalRegn02Rt02GroupA.AssiHiFrqWhlImbRejctnBlndX -> AAACalRegn02Rt02GroupA_Dummy.AssiHiFrqWhlImbRejctnBlndX
    connect CalRegn02Rt02GroupA.AssiHiFrqWhlImbRejctnBlndY -> AAACalRegn02Rt02GroupA_Dummy.AssiHiFrqWhlImbRejctnBlndY
    connect CalRegn02Rt02GroupA.AssiHiFrqWhlImbRejctnGainY -> AAACalRegn02Rt02GroupA_Dummy.AssiHiFrqWhlImbRejctnGainY
    connect CalRegn02Rt02GroupA.AssiMotTqWhlImbRejctnMaxX -> AAACalRegn02Rt02GroupA_Dummy.AssiMotTqWhlImbRejctnMaxX
    connect CalRegn02Rt02GroupA.AssiMotTqWhlImbRejctnMaxY -> AAACalRegn02Rt02GroupA_Dummy.AssiMotTqWhlImbRejctnMaxY
    connect CalRegn02Rt02GroupA.AssiMotTqWhlImbRejctnMinX -> AAACalRegn02Rt02GroupA_Dummy.AssiMotTqWhlImbRejctnMinX
    connect CalRegn02Rt02GroupA.AssiMotTqWhlImbRejctnMinY -> AAACalRegn02Rt02GroupA_Dummy.AssiMotTqWhlImbRejctnMinY
    connect CalRegn02Rt02GroupA.AssiWhlImbRejctnBlndScaX -> AAACalRegn02Rt02GroupA_Dummy.AssiWhlImbRejctnBlndScaX
    connect CalRegn02Rt02GroupA.AssiWhlImbRejctnBlndScaY -> AAACalRegn02Rt02GroupA_Dummy.AssiWhlImbRejctnBlndScaY
    connect CalRegn02Rt02GroupA.DampgHwTqX -> AAACalRegn02Rt02GroupA_Dummy.DampgHwTqX
    connect CalRegn02Rt02GroupA.DampgHwTqY -> AAACalRegn02Rt02GroupA_Dummy.DampgHwTqY
    connect CalRegn02Rt02GroupA.DampgHydCoeff{1..4}ScaY -> AAACalRegn02Rt02GroupA_Dummy.DampgHydCoeff{1..4}ScaY
    connect CalRegn02Rt02GroupA.DampgMotVelX -> AAACalRegn02Rt02GroupA_Dummy.DampgMotVelX
    connect CalRegn02Rt02GroupA.DampgMotVelY -> AAACalRegn02Rt02GroupA_Dummy.DampgMotVelY
    connect CalRegn02Rt02GroupA.HysCmpEffLossY -> AAACalRegn02Rt02GroupA_Dummy.HysCmpEffLossY
    connect CalRegn02Rt02GroupA.HysCmpEffOffsY -> AAACalRegn02Rt02GroupA_Dummy.HysCmpEffOffsY
    connect CalRegn02Rt02GroupA.HysCmpFricWhlImbRejctnBlndX -> AAACalRegn02Rt02GroupA_Dummy.HysCmpFricWhlImbRejctnBlndX
    connect CalRegn02Rt02GroupA.HysCmpFricWhlImbRejctnBlndY -> AAACalRegn02Rt02GroupA_Dummy.HysCmpFricWhlImbRejctnBlndY
    connect CalRegn02Rt02GroupA.HysCmpFricWhlImbRejctnOffY -> AAACalRegn02Rt02GroupA_Dummy.HysCmpFricWhlImbRejctnOffY
    connect CalRegn02Rt02GroupA.HysCmpFricWhlImbRejctnOnY -> AAACalRegn02Rt02GroupA_Dummy.HysCmpFricWhlImbRejctnOnY
    connect CalRegn02Rt02GroupA.HysCmpHwTqScaX -> AAACalRegn02Rt02GroupA_Dummy.HysCmpHwTqScaX
    connect CalRegn02Rt02GroupA.HysCmpHwTqScaY -> AAACalRegn02Rt02GroupA_Dummy.HysCmpHwTqScaY
    connect CalRegn02Rt02GroupA.HysCmpHysSatnY -> AAACalRegn02Rt02GroupA_Dummy.HysCmpHysSatnY
    connect CalRegn02Rt02GroupA.HysCmpNegHysCmpScaX -> AAACalRegn02Rt02GroupA_Dummy.HysCmpNegHysCmpScaX
    connect CalRegn02Rt02GroupA.HysCmpNegHysCmpScaY -> AAACalRegn02Rt02GroupA_Dummy.HysCmpNegHysCmpScaY
    connect CalRegn02Rt02GroupA.HysCmpNegHysCmpX -> AAACalRegn02Rt02GroupA_Dummy.HysCmpNegHysCmpX
    connect CalRegn02Rt02GroupA.HysCmpNegHysCmpY -> AAACalRegn02Rt02GroupA_Dummy.HysCmpNegHysCmpY
    connect CalRegn02Rt02GroupA.HysCmpOutpLim -> AAACalRegn02Rt02GroupA_Dummy.HysCmpOutpLim
    connect CalRegn02Rt02GroupA.HysCmpRevGain -> AAACalRegn02Rt02GroupA_Dummy.HysCmpRevGain
    connect CalRegn02Rt02GroupA.HysCmpRiseX -> AAACalRegn02Rt02GroupA_Dummy.HysCmpRiseX
    connect CalRegn02Rt02GroupA.HysCmpRiseY -> AAACalRegn02Rt02GroupA_Dummy.HysCmpRiseY
    connect CalRegn02Rt02GroupA.InertiaCmpVelAssiBasdDampgStatY -> AAACalRegn02Rt02GroupA_Dummy.InertiaCmpVelAssiBasdDampgStatY
    connect CalRegn02Rt02GroupA.InertiaCmpVelDampgFilFrq -> AAACalRegn02Rt02GroupA_Dummy.InertiaCmpVelDampgFilFrq
    connect CalRegn02Rt02GroupA.InertiaCmpVelDampgFilFrqWhlImbRejctnOn -> AAACalRegn02Rt02GroupA_Dummy.InertiaCmpVelDampgFilFrqWhlImbRejctnOn
    connect CalRegn02Rt02GroupA.InertiaCmpVelDampgSpdBlndY -> AAACalRegn02Rt02GroupA_Dummy.InertiaCmpVelDampgSpdBlndY
    connect CalRegn02Rt02GroupA.InertiaCmpVelDampgWhlImbRejctnBlndX -> AAACalRegn02Rt02GroupA_Dummy.InertiaCmpVelDampgWhlImbRejctnBlndX
    connect CalRegn02Rt02GroupA.InertiaCmpVelDampgWhlImbRejctnBlndY -> AAACalRegn02Rt02GroupA_Dummy.InertiaCmpVelDampgWhlImbRejctnBlndY
    connect CalRegn02Rt03GroupA.AssiHiFrqGainY -> AAACalRegn02Rt03GroupA_Dummy.AssiHiFrqGainY
    connect CalRegn02Rt03GroupA.AssiHiFrqHpFilFrqY -> AAACalRegn02Rt03GroupA_Dummy.AssiHiFrqHpFilFrqY
    connect CalRegn02Rt03GroupA.AssiHiFrqTqWhlImbRejctnTqX -> AAACalRegn02Rt03GroupA_Dummy.AssiHiFrqTqWhlImbRejctnTqX
    connect CalRegn02Rt03GroupA.AssiHiFrqTqX -> AAACalRegn02Rt03GroupA_Dummy.AssiHiFrqTqX
    connect CalRegn02Rt03GroupA.AssiHiFrqWhlImbRejctnBlndX -> AAACalRegn02Rt03GroupA_Dummy.AssiHiFrqWhlImbRejctnBlndX
    connect CalRegn02Rt03GroupA.AssiHiFrqWhlImbRejctnBlndY -> AAACalRegn02Rt03GroupA_Dummy.AssiHiFrqWhlImbRejctnBlndY
    connect CalRegn02Rt03GroupA.AssiHiFrqWhlImbRejctnGainY -> AAACalRegn02Rt03GroupA_Dummy.AssiHiFrqWhlImbRejctnGainY
    connect CalRegn02Rt03GroupA.AssiMotTqWhlImbRejctnMaxX -> AAACalRegn02Rt03GroupA_Dummy.AssiMotTqWhlImbRejctnMaxX
    connect CalRegn02Rt03GroupA.AssiMotTqWhlImbRejctnMaxY -> AAACalRegn02Rt03GroupA_Dummy.AssiMotTqWhlImbRejctnMaxY
    connect CalRegn02Rt03GroupA.AssiMotTqWhlImbRejctnMinX -> AAACalRegn02Rt03GroupA_Dummy.AssiMotTqWhlImbRejctnMinX
    connect CalRegn02Rt03GroupA.AssiMotTqWhlImbRejctnMinY -> AAACalRegn02Rt03GroupA_Dummy.AssiMotTqWhlImbRejctnMinY
    connect CalRegn02Rt03GroupA.AssiWhlImbRejctnBlndScaX -> AAACalRegn02Rt03GroupA_Dummy.AssiWhlImbRejctnBlndScaX
    connect CalRegn02Rt03GroupA.AssiWhlImbRejctnBlndScaY -> AAACalRegn02Rt03GroupA_Dummy.AssiWhlImbRejctnBlndScaY
    connect CalRegn02Rt03GroupA.DampgHwTqX -> AAACalRegn02Rt03GroupA_Dummy.DampgHwTqX
    connect CalRegn02Rt03GroupA.DampgHwTqY -> AAACalRegn02Rt03GroupA_Dummy.DampgHwTqY
    connect CalRegn02Rt03GroupA.DampgHydCoeff{1..4}ScaY -> AAACalRegn02Rt03GroupA_Dummy.DampgHydCoeff{1..4}ScaY
    connect CalRegn02Rt03GroupA.DampgMotVelX -> AAACalRegn02Rt03GroupA_Dummy.DampgMotVelX
    connect CalRegn02Rt03GroupA.DampgMotVelY -> AAACalRegn02Rt03GroupA_Dummy.DampgMotVelY
    connect CalRegn02Rt03GroupA.HysCmpEffLossY -> AAACalRegn02Rt03GroupA_Dummy.HysCmpEffLossY
    connect CalRegn02Rt03GroupA.HysCmpEffOffsY -> AAACalRegn02Rt03GroupA_Dummy.HysCmpEffOffsY
    connect CalRegn02Rt03GroupA.HysCmpFricWhlImbRejctnBlndX -> AAACalRegn02Rt03GroupA_Dummy.HysCmpFricWhlImbRejctnBlndX
    connect CalRegn02Rt03GroupA.HysCmpFricWhlImbRejctnBlndY -> AAACalRegn02Rt03GroupA_Dummy.HysCmpFricWhlImbRejctnBlndY
    connect CalRegn02Rt03GroupA.HysCmpFricWhlImbRejctnOffY -> AAACalRegn02Rt03GroupA_Dummy.HysCmpFricWhlImbRejctnOffY
    connect CalRegn02Rt03GroupA.HysCmpFricWhlImbRejctnOnY -> AAACalRegn02Rt03GroupA_Dummy.HysCmpFricWhlImbRejctnOnY
    connect CalRegn02Rt03GroupA.HysCmpHwTqScaX -> AAACalRegn02Rt03GroupA_Dummy.HysCmpHwTqScaX
    connect CalRegn02Rt03GroupA.HysCmpHwTqScaY -> AAACalRegn02Rt03GroupA_Dummy.HysCmpHwTqScaY
    connect CalRegn02Rt03GroupA.HysCmpHysSatnY -> AAACalRegn02Rt03GroupA_Dummy.HysCmpHysSatnY
    connect CalRegn02Rt03GroupA.HysCmpNegHysCmpScaX -> AAACalRegn02Rt03GroupA_Dummy.HysCmpNegHysCmpScaX
    connect CalRegn02Rt03GroupA.HysCmpNegHysCmpScaY -> AAACalRegn02Rt03GroupA_Dummy.HysCmpNegHysCmpScaY
    connect CalRegn02Rt03GroupA.HysCmpNegHysCmpX -> AAACalRegn02Rt03GroupA_Dummy.HysCmpNegHysCmpX
    connect CalRegn02Rt03GroupA.HysCmpNegHysCmpY -> AAACalRegn02Rt03GroupA_Dummy.HysCmpNegHysCmpY
    connect CalRegn02Rt03GroupA.HysCmpOutpLim -> AAACalRegn02Rt03GroupA_Dummy.HysCmpOutpLim
    connect CalRegn02Rt03GroupA.HysCmpRevGain -> AAACalRegn02Rt03GroupA_Dummy.HysCmpRevGain
    connect CalRegn02Rt03GroupA.HysCmpRiseX -> AAACalRegn02Rt03GroupA_Dummy.HysCmpRiseX
    connect CalRegn02Rt03GroupA.HysCmpRiseY -> AAACalRegn02Rt03GroupA_Dummy.HysCmpRiseY
    connect CalRegn02Rt03GroupA.InertiaCmpVelAssiBasdDampgStatY -> AAACalRegn02Rt03GroupA_Dummy.InertiaCmpVelAssiBasdDampgStatY
    connect CalRegn02Rt03GroupA.InertiaCmpVelDampgFilFrq -> AAACalRegn02Rt03GroupA_Dummy.InertiaCmpVelDampgFilFrq
    connect CalRegn02Rt03GroupA.InertiaCmpVelDampgFilFrqWhlImbRejctnOn -> AAACalRegn02Rt03GroupA_Dummy.InertiaCmpVelDampgFilFrqWhlImbRejctnOn
    connect CalRegn02Rt03GroupA.InertiaCmpVelDampgSpdBlndY -> AAACalRegn02Rt03GroupA_Dummy.InertiaCmpVelDampgSpdBlndY
    connect CalRegn02Rt03GroupA.InertiaCmpVelDampgWhlImbRejctnBlndX -> AAACalRegn02Rt03GroupA_Dummy.InertiaCmpVelDampgWhlImbRejctnBlndX
    connect CalRegn02Rt03GroupA.InertiaCmpVelDampgWhlImbRejctnBlndY -> AAACalRegn02Rt03GroupA_Dummy.InertiaCmpVelDampgWhlImbRejctnBlndY
    connect CalRegn02Rt04GroupA.AssiHiFrqGainY -> AAACalRegn02Rt04GroupA_Dummy.AssiHiFrqGainY
    connect CalRegn02Rt04GroupA.AssiHiFrqHpFilFrqY -> AAACalRegn02Rt04GroupA_Dummy.AssiHiFrqHpFilFrqY
    connect CalRegn02Rt04GroupA.AssiHiFrqTqWhlImbRejctnTqX -> AAACalRegn02Rt04GroupA_Dummy.AssiHiFrqTqWhlImbRejctnTqX
    connect CalRegn02Rt04GroupA.AssiHiFrqTqX -> AAACalRegn02Rt04GroupA_Dummy.AssiHiFrqTqX
    connect CalRegn02Rt04GroupA.AssiHiFrqWhlImbRejctnBlndX -> AAACalRegn02Rt04GroupA_Dummy.AssiHiFrqWhlImbRejctnBlndX
    connect CalRegn02Rt04GroupA.AssiHiFrqWhlImbRejctnBlndY -> AAACalRegn02Rt04GroupA_Dummy.AssiHiFrqWhlImbRejctnBlndY
    connect CalRegn02Rt04GroupA.AssiHiFrqWhlImbRejctnGainY -> AAACalRegn02Rt04GroupA_Dummy.AssiHiFrqWhlImbRejctnGainY
    connect CalRegn02Rt04GroupA.AssiMotTqWhlImbRejctnMaxX -> AAACalRegn02Rt04GroupA_Dummy.AssiMotTqWhlImbRejctnMaxX
    connect CalRegn02Rt04GroupA.AssiMotTqWhlImbRejctnMaxY -> AAACalRegn02Rt04GroupA_Dummy.AssiMotTqWhlImbRejctnMaxY
    connect CalRegn02Rt04GroupA.AssiMotTqWhlImbRejctnMinX -> AAACalRegn02Rt04GroupA_Dummy.AssiMotTqWhlImbRejctnMinX
    connect CalRegn02Rt04GroupA.AssiMotTqWhlImbRejctnMinY -> AAACalRegn02Rt04GroupA_Dummy.AssiMotTqWhlImbRejctnMinY
    connect CalRegn02Rt04GroupA.AssiWhlImbRejctnBlndScaX -> AAACalRegn02Rt04GroupA_Dummy.AssiWhlImbRejctnBlndScaX
    connect CalRegn02Rt04GroupA.AssiWhlImbRejctnBlndScaY -> AAACalRegn02Rt04GroupA_Dummy.AssiWhlImbRejctnBlndScaY
    connect CalRegn02Rt04GroupA.DampgHwTqX -> AAACalRegn02Rt04GroupA_Dummy.DampgHwTqX
    connect CalRegn02Rt04GroupA.DampgHwTqY -> AAACalRegn02Rt04GroupA_Dummy.DampgHwTqY
    connect CalRegn02Rt04GroupA.DampgHydCoeff{1..4}ScaY -> AAACalRegn02Rt04GroupA_Dummy.DampgHydCoeff{1..4}ScaY
    connect CalRegn02Rt04GroupA.DampgMotVelX -> AAACalRegn02Rt04GroupA_Dummy.DampgMotVelX
    connect CalRegn02Rt04GroupA.DampgMotVelY -> AAACalRegn02Rt04GroupA_Dummy.DampgMotVelY
    connect CalRegn02Rt04GroupA.HysCmpEffLossY -> AAACalRegn02Rt04GroupA_Dummy.HysCmpEffLossY
    connect CalRegn02Rt04GroupA.HysCmpEffOffsY -> AAACalRegn02Rt04GroupA_Dummy.HysCmpEffOffsY
    connect CalRegn02Rt04GroupA.HysCmpFricWhlImbRejctnBlndX -> AAACalRegn02Rt04GroupA_Dummy.HysCmpFricWhlImbRejctnBlndX
    connect CalRegn02Rt04GroupA.HysCmpFricWhlImbRejctnBlndY -> AAACalRegn02Rt04GroupA_Dummy.HysCmpFricWhlImbRejctnBlndY
    connect CalRegn02Rt04GroupA.HysCmpFricWhlImbRejctnOffY -> AAACalRegn02Rt04GroupA_Dummy.HysCmpFricWhlImbRejctnOffY
    connect CalRegn02Rt04GroupA.HysCmpFricWhlImbRejctnOnY -> AAACalRegn02Rt04GroupA_Dummy.HysCmpFricWhlImbRejctnOnY
    connect CalRegn02Rt04GroupA.HysCmpHwTqScaX -> AAACalRegn02Rt04GroupA_Dummy.HysCmpHwTqScaX
    connect CalRegn02Rt04GroupA.HysCmpHwTqScaY -> AAACalRegn02Rt04GroupA_Dummy.HysCmpHwTqScaY
    connect CalRegn02Rt04GroupA.HysCmpHysSatnY -> AAACalRegn02Rt04GroupA_Dummy.HysCmpHysSatnY
    connect CalRegn02Rt04GroupA.HysCmpNegHysCmpScaX -> AAACalRegn02Rt04GroupA_Dummy.HysCmpNegHysCmpScaX
    connect CalRegn02Rt04GroupA.HysCmpNegHysCmpScaY -> AAACalRegn02Rt04GroupA_Dummy.HysCmpNegHysCmpScaY
    connect CalRegn02Rt04GroupA.HysCmpNegHysCmpX -> AAACalRegn02Rt04GroupA_Dummy.HysCmpNegHysCmpX
    connect CalRegn02Rt04GroupA.HysCmpNegHysCmpY -> AAACalRegn02Rt04GroupA_Dummy.HysCmpNegHysCmpY
    connect CalRegn02Rt04GroupA.HysCmpOutpLim -> AAACalRegn02Rt04GroupA_Dummy.HysCmpOutpLim
    connect CalRegn02Rt04GroupA.HysCmpRevGain -> AAACalRegn02Rt04GroupA_Dummy.HysCmpRevGain
    connect CalRegn02Rt04GroupA.HysCmpRiseX -> AAACalRegn02Rt04GroupA_Dummy.HysCmpRiseX
    connect CalRegn02Rt04GroupA.HysCmpRiseY -> AAACalRegn02Rt04GroupA_Dummy.HysCmpRiseY
    connect CalRegn02Rt04GroupA.InertiaCmpVelAssiBasdDampgStatY -> AAACalRegn02Rt04GroupA_Dummy.InertiaCmpVelAssiBasdDampgStatY
    connect CalRegn02Rt04GroupA.InertiaCmpVelDampgFilFrq -> AAACalRegn02Rt04GroupA_Dummy.InertiaCmpVelDampgFilFrq
    connect CalRegn02Rt04GroupA.InertiaCmpVelDampgFilFrqWhlImbRejctnOn -> AAACalRegn02Rt04GroupA_Dummy.InertiaCmpVelDampgFilFrqWhlImbRejctnOn
    connect CalRegn02Rt04GroupA.InertiaCmpVelDampgSpdBlndY -> AAACalRegn02Rt04GroupA_Dummy.InertiaCmpVelDampgSpdBlndY
    connect CalRegn02Rt04GroupA.InertiaCmpVelDampgWhlImbRejctnBlndX -> AAACalRegn02Rt04GroupA_Dummy.InertiaCmpVelDampgWhlImbRejctnBlndX
    connect CalRegn02Rt04GroupA.InertiaCmpVelDampgWhlImbRejctnBlndY -> AAACalRegn02Rt04GroupA_Dummy.InertiaCmpVelDampgWhlImbRejctnBlndY
    connect CalRegn02Rt05GroupA.AssiHiFrqGainY -> AAACalRegn02Rt05GroupA_Dummy.AssiHiFrqGainY
    connect CalRegn02Rt05GroupA.AssiHiFrqHpFilFrqY -> AAACalRegn02Rt05GroupA_Dummy.AssiHiFrqHpFilFrqY
    connect CalRegn02Rt05GroupA.AssiHiFrqTqWhlImbRejctnTqX -> AAACalRegn02Rt05GroupA_Dummy.AssiHiFrqTqWhlImbRejctnTqX
    connect CalRegn02Rt05GroupA.AssiHiFrqTqX -> AAACalRegn02Rt05GroupA_Dummy.AssiHiFrqTqX
    connect CalRegn02Rt05GroupA.AssiHiFrqWhlImbRejctnBlndX -> AAACalRegn02Rt05GroupA_Dummy.AssiHiFrqWhlImbRejctnBlndX
    connect CalRegn02Rt05GroupA.AssiHiFrqWhlImbRejctnBlndY -> AAACalRegn02Rt05GroupA_Dummy.AssiHiFrqWhlImbRejctnBlndY
    connect CalRegn02Rt05GroupA.AssiHiFrqWhlImbRejctnGainY -> AAACalRegn02Rt05GroupA_Dummy.AssiHiFrqWhlImbRejctnGainY
    connect CalRegn02Rt05GroupA.AssiMotTqWhlImbRejctnMaxX -> AAACalRegn02Rt05GroupA_Dummy.AssiMotTqWhlImbRejctnMaxX
    connect CalRegn02Rt05GroupA.AssiMotTqWhlImbRejctnMaxY -> AAACalRegn02Rt05GroupA_Dummy.AssiMotTqWhlImbRejctnMaxY
    connect CalRegn02Rt05GroupA.AssiMotTqWhlImbRejctnMinX -> AAACalRegn02Rt05GroupA_Dummy.AssiMotTqWhlImbRejctnMinX
    connect CalRegn02Rt05GroupA.AssiMotTqWhlImbRejctnMinY -> AAACalRegn02Rt05GroupA_Dummy.AssiMotTqWhlImbRejctnMinY
    connect CalRegn02Rt05GroupA.AssiWhlImbRejctnBlndScaX -> AAACalRegn02Rt05GroupA_Dummy.AssiWhlImbRejctnBlndScaX
    connect CalRegn02Rt05GroupA.AssiWhlImbRejctnBlndScaY -> AAACalRegn02Rt05GroupA_Dummy.AssiWhlImbRejctnBlndScaY
    connect CalRegn02Rt05GroupA.DampgHwTqX -> AAACalRegn02Rt05GroupA_Dummy.DampgHwTqX
    connect CalRegn02Rt05GroupA.DampgHwTqY -> AAACalRegn02Rt05GroupA_Dummy.DampgHwTqY
    connect CalRegn02Rt05GroupA.DampgHydCoeff{1..4}ScaY -> AAACalRegn02Rt05GroupA_Dummy.DampgHydCoeff{1..4}ScaY
    connect CalRegn02Rt05GroupA.DampgMotVelX -> AAACalRegn02Rt05GroupA_Dummy.DampgMotVelX
    connect CalRegn02Rt05GroupA.DampgMotVelY -> AAACalRegn02Rt05GroupA_Dummy.DampgMotVelY
    connect CalRegn02Rt05GroupA.HysCmpEffLossY -> AAACalRegn02Rt05GroupA_Dummy.HysCmpEffLossY
    connect CalRegn02Rt05GroupA.HysCmpEffOffsY -> AAACalRegn02Rt05GroupA_Dummy.HysCmpEffOffsY
    connect CalRegn02Rt05GroupA.HysCmpFricWhlImbRejctnBlndX -> AAACalRegn02Rt05GroupA_Dummy.HysCmpFricWhlImbRejctnBlndX
    connect CalRegn02Rt05GroupA.HysCmpFricWhlImbRejctnBlndY -> AAACalRegn02Rt05GroupA_Dummy.HysCmpFricWhlImbRejctnBlndY
    connect CalRegn02Rt05GroupA.HysCmpFricWhlImbRejctnOffY -> AAACalRegn02Rt05GroupA_Dummy.HysCmpFricWhlImbRejctnOffY
    connect CalRegn02Rt05GroupA.HysCmpFricWhlImbRejctnOnY -> AAACalRegn02Rt05GroupA_Dummy.HysCmpFricWhlImbRejctnOnY
    connect CalRegn02Rt05GroupA.HysCmpHwTqScaX -> AAACalRegn02Rt05GroupA_Dummy.HysCmpHwTqScaX
    connect CalRegn02Rt05GroupA.HysCmpHwTqScaY -> AAACalRegn02Rt05GroupA_Dummy.HysCmpHwTqScaY
    connect CalRegn02Rt05GroupA.HysCmpHysSatnY -> AAACalRegn02Rt05GroupA_Dummy.HysCmpHysSatnY
    connect CalRegn02Rt05GroupA.HysCmpNegHysCmpScaX -> AAACalRegn02Rt05GroupA_Dummy.HysCmpNegHysCmpScaX
    connect CalRegn02Rt05GroupA.HysCmpNegHysCmpScaY -> AAACalRegn02Rt05GroupA_Dummy.HysCmpNegHysCmpScaY
    connect CalRegn02Rt05GroupA.HysCmpNegHysCmpX -> AAACalRegn02Rt05GroupA_Dummy.HysCmpNegHysCmpX
    connect CalRegn02Rt05GroupA.HysCmpNegHysCmpY -> AAACalRegn02Rt05GroupA_Dummy.HysCmpNegHysCmpY
    connect CalRegn02Rt05GroupA.HysCmpOutpLim -> AAACalRegn02Rt05GroupA_Dummy.HysCmpOutpLim
    connect CalRegn02Rt05GroupA.HysCmpRevGain -> AAACalRegn02Rt05GroupA_Dummy.HysCmpRevGain
    connect CalRegn02Rt05GroupA.HysCmpRiseX -> AAACalRegn02Rt05GroupA_Dummy.HysCmpRiseX
    connect CalRegn02Rt05GroupA.HysCmpRiseY -> AAACalRegn02Rt05GroupA_Dummy.HysCmpRiseY
    connect CalRegn02Rt05GroupA.InertiaCmpVelAssiBasdDampgStatY -> AAACalRegn02Rt05GroupA_Dummy.InertiaCmpVelAssiBasdDampgStatY
    connect CalRegn02Rt05GroupA.InertiaCmpVelDampgFilFrq -> AAACalRegn02Rt05GroupA_Dummy.InertiaCmpVelDampgFilFrq
    connect CalRegn02Rt05GroupA.InertiaCmpVelDampgFilFrqWhlImbRejctnOn -> AAACalRegn02Rt05GroupA_Dummy.InertiaCmpVelDampgFilFrqWhlImbRejctnOn
    connect CalRegn02Rt05GroupA.InertiaCmpVelDampgSpdBlndY -> AAACalRegn02Rt05GroupA_Dummy.InertiaCmpVelDampgSpdBlndY
    connect CalRegn02Rt05GroupA.InertiaCmpVelDampgWhlImbRejctnBlndX -> AAACalRegn02Rt05GroupA_Dummy.InertiaCmpVelDampgWhlImbRejctnBlndX
    connect CalRegn02Rt05GroupA.InertiaCmpVelDampgWhlImbRejctnBlndY -> AAACalRegn02Rt05GroupA_Dummy.InertiaCmpVelDampgWhlImbRejctnBlndY
    connect CalRegn02Rt00GroupA.AssiHiFrqGainY -> AAACalRegn02Rt00GroupA_Dummy.AssiHiFrqGainY
    connect CalRegn02Rt00GroupA.AssiHiFrqHpFilFrqY -> AAACalRegn02Rt00GroupA_Dummy.AssiHiFrqHpFilFrqY
    connect CalRegn02Rt00GroupA.AssiHiFrqTqWhlImbRejctnTqX -> AAACalRegn02Rt00GroupA_Dummy.AssiHiFrqTqWhlImbRejctnTqX
    connect CalRegn02Rt00GroupA.AssiHiFrqTqX -> AAACalRegn02Rt00GroupA_Dummy.AssiHiFrqTqX
    connect CalRegn02Rt00GroupA.AssiHiFrqWhlImbRejctnBlndX -> AAACalRegn02Rt00GroupA_Dummy.AssiHiFrqWhlImbRejctnBlndX
    connect CalRegn02Rt00GroupA.AssiHiFrqWhlImbRejctnBlndY -> AAACalRegn02Rt00GroupA_Dummy.AssiHiFrqWhlImbRejctnBlndY
    connect CalRegn02Rt00GroupA.AssiHiFrqWhlImbRejctnGainY -> AAACalRegn02Rt00GroupA_Dummy.AssiHiFrqWhlImbRejctnGainY
    connect CalRegn02Rt00GroupA.AssiMotTqWhlImbRejctnMaxX -> AAACalRegn02Rt00GroupA_Dummy.AssiMotTqWhlImbRejctnMaxX
    connect CalRegn02Rt00GroupA.AssiMotTqWhlImbRejctnMaxY -> AAACalRegn02Rt00GroupA_Dummy.AssiMotTqWhlImbRejctnMaxY
    connect CalRegn02Rt00GroupA.AssiMotTqWhlImbRejctnMinX -> AAACalRegn02Rt00GroupA_Dummy.AssiMotTqWhlImbRejctnMinX
    connect CalRegn02Rt00GroupA.AssiMotTqWhlImbRejctnMinY -> AAACalRegn02Rt00GroupA_Dummy.AssiMotTqWhlImbRejctnMinY
    connect CalRegn02Rt00GroupA.AssiWhlImbRejctnBlndScaX -> AAACalRegn02Rt00GroupA_Dummy.AssiWhlImbRejctnBlndScaX
    connect CalRegn02Rt00GroupA.AssiWhlImbRejctnBlndScaY -> AAACalRegn02Rt00GroupA_Dummy.AssiWhlImbRejctnBlndScaY
    connect CalRegn02Rt00GroupA.DampgHwTqX -> AAACalRegn02Rt00GroupA_Dummy.DampgHwTqX
    connect CalRegn02Rt00GroupA.DampgHwTqY -> AAACalRegn02Rt00GroupA_Dummy.DampgHwTqY
    connect CalRegn02Rt00GroupA.DampgHydCoeff{1..4}ScaY -> AAACalRegn02Rt00GroupA_Dummy.DampgHydCoeff{1..4}ScaY
    connect CalRegn02Rt00GroupA.DampgMotVelX -> AAACalRegn02Rt00GroupA_Dummy.DampgMotVelX
    connect CalRegn02Rt00GroupA.DampgMotVelY -> AAACalRegn02Rt00GroupA_Dummy.DampgMotVelY
    connect CalRegn02Rt00GroupA.HysCmpEffLossY -> AAACalRegn02Rt00GroupA_Dummy.HysCmpEffLossY
    connect CalRegn02Rt00GroupA.HysCmpEffOffsY -> AAACalRegn02Rt00GroupA_Dummy.HysCmpEffOffsY
    connect CalRegn02Rt00GroupA.HysCmpFricWhlImbRejctnBlndX -> AAACalRegn02Rt00GroupA_Dummy.HysCmpFricWhlImbRejctnBlndX
    connect CalRegn02Rt00GroupA.HysCmpFricWhlImbRejctnBlndY -> AAACalRegn02Rt00GroupA_Dummy.HysCmpFricWhlImbRejctnBlndY
    connect CalRegn02Rt00GroupA.HysCmpFricWhlImbRejctnOffY -> AAACalRegn02Rt00GroupA_Dummy.HysCmpFricWhlImbRejctnOffY
    connect CalRegn02Rt00GroupA.HysCmpFricWhlImbRejctnOnY -> AAACalRegn02Rt00GroupA_Dummy.HysCmpFricWhlImbRejctnOnY
    connect CalRegn02Rt00GroupA.HysCmpHwTqScaX -> AAACalRegn02Rt00GroupA_Dummy.HysCmpHwTqScaX
    connect CalRegn02Rt00GroupA.HysCmpHwTqScaY -> AAACalRegn02Rt00GroupA_Dummy.HysCmpHwTqScaY
    connect CalRegn02Rt00GroupA.HysCmpHysSatnY -> AAACalRegn02Rt00GroupA_Dummy.HysCmpHysSatnY
    connect CalRegn02Rt00GroupA.HysCmpNegHysCmpScaX -> AAACalRegn02Rt00GroupA_Dummy.HysCmpNegHysCmpScaX
    connect CalRegn02Rt00GroupA.HysCmpNegHysCmpScaY -> AAACalRegn02Rt00GroupA_Dummy.HysCmpNegHysCmpScaY
    connect CalRegn02Rt00GroupA.HysCmpNegHysCmpX -> AAACalRegn02Rt00GroupA_Dummy.HysCmpNegHysCmpX
    connect CalRegn02Rt00GroupA.HysCmpNegHysCmpY -> AAACalRegn02Rt00GroupA_Dummy.HysCmpNegHysCmpY
    connect CalRegn02Rt00GroupA.HysCmpOutpLim -> AAACalRegn02Rt00GroupA_Dummy.HysCmpOutpLim
    connect CalRegn02Rt00GroupA.HysCmpRevGain -> AAACalRegn02Rt00GroupA_Dummy.HysCmpRevGain
    connect CalRegn02Rt00GroupA.HysCmpRiseX -> AAACalRegn02Rt00GroupA_Dummy.HysCmpRiseX
    connect CalRegn02Rt00GroupA.HysCmpRiseY -> AAACalRegn02Rt00GroupA_Dummy.HysCmpRiseY
    connect CalRegn02Rt00GroupA.InertiaCmpVelAssiBasdDampgStatY -> AAACalRegn02Rt00GroupA_Dummy.InertiaCmpVelAssiBasdDampgStatY
    connect CalRegn02Rt00GroupA.InertiaCmpVelDampgFilFrq -> AAACalRegn02Rt00GroupA_Dummy.InertiaCmpVelDampgFilFrq
    connect CalRegn02Rt00GroupA.InertiaCmpVelDampgFilFrqWhlImbRejctnOn -> AAACalRegn02Rt00GroupA_Dummy.InertiaCmpVelDampgFilFrqWhlImbRejctnOn
    connect CalRegn02Rt00GroupA.InertiaCmpVelDampgSpdBlndY -> AAACalRegn02Rt00GroupA_Dummy.InertiaCmpVelDampgSpdBlndY
    connect CalRegn02Rt00GroupA.InertiaCmpVelDampgWhlImbRejctnBlndX -> AAACalRegn02Rt00GroupA_Dummy.InertiaCmpVelDampgWhlImbRejctnBlndX
    connect CalRegn02Rt00GroupA.InertiaCmpVelDampgWhlImbRejctnBlndY -> AAACalRegn02Rt00GroupA_Dummy.InertiaCmpVelDampgWhlImbRejctnBlndY
    connect DiagcMgrProxyAppl10.GetNtcQlfrSts10 -> HwAgSysArbn.GetNtcQlfrSts
    connect Assi.AssiCmdBas -> FordHwTqCdng.AssiCmdBas
    connect BattVltg.BrdgVltg -> FordCanDtcInhb.FordBattVltgEstimn
    connect BattVltg.BrdgVltg -> FordVltgIf.BattVltg
    connect CDD_MotAgCmp.MotAgCumvAlgndMrf -> FordHwAgArbn.FordMotPosn
    connect CDD_MotVel.MotVelVld -> FordHwAgArbn.FordMotVelVld
    connect CDD_NxtrTi.GetRefTmr100MicroSec32bit -> FordCanDtcInhb.GetRefTmr100MicroSec32bit
    connect CDD_NxtrTi.GetTiSpan100MicroSec32bit -> FordCanDtcInhb.GetTiSpan100MicroSec32bit
    connect CDD_NxtrTi.GetRefTmr100MicroSec32bit -> FordHwAgArbn.GetRefTmr100MicroSec32bit
    connect CDD_NxtrTi.GetTiSpan100MicroSec32bit -> FordHwAgArbn.GetTiSpan100MicroSec32bit
    connect CDD_NxtrTi.GetRefTmr100MicroSec32bit -> FordHwTqCdng.GetRefTmr100MicroSec32bit
    connect CDD_NxtrTi.GetTiSpan100MicroSec32bit -> FordHwTqCdng.GetTiSpan100MicroSec32bit
    connect CDD_NxtrTi.GetRefTmr100MicroSec32bit -> FordVltgIf.GetRefTmr100MicroSec32bit
    connect CDD_NxtrTi.GetTiSpan100MicroSec32bit -> FordVltgIf.GetTiSpan100MicroSec32bit
    connect CmnMfgSrv.SysStReqEnaOvrd -> FordSysSt.EngOnSerlComSrvDft
    connect CustDiag.FordAbsPrsnt -> FordHwAgArbn.FordAbsPrsnt
    connect CustDiag.FordAbsPrsnt -> FordVehSpdArbn.FordAbsModlPrsnt
    connect CustDiag.FordEscPrsnt -> FordVehSpdArbn.FordEscModlPrsnt
    connect CustDiag.FordActvParkAssiEnad -> FordVltgIf.FordActvParkAssiEnad
    connect CustDiag.FordEvasSteerAssiEnad -> FordVltgIf.FordEvasSteerAssiEnad
    connect CustDiag.FordLaneCentrAssiEnad -> FordVltgIf.FordLaneCentrAssiEnad
    connect CustDiag.FordLaneDprtrWarnEnad -> FordVltgIf.FordLaneDprtrWarnEnad
    connect CustDiag.FordLaneKeepAssiEnad -> FordVltgIf.FordLaneKeepAssiEnad
    connect CustDiag.FordTrfcJamAssiEnad -> FordVltgIf.FordTrfcJamAssiEnad
    connect DiagcMgrProxyAppl10.SetNtcSts10 -> FordHwAgArbn.SetNtcSts
    connect DiagcMgrProxyAppl10.GetNtcQlfrSts10 -> FordHwTqCdng.GetNtcQlfrSts
    connect DiagcMgrProxyAppl10.GetNtcQlfrSts10 -> FordSysSt.GetNtcQlfrSts
    connect DiagcMgrProxyAppl10.SetNtcSts10 -> FordVltgIf.SetNtcSts
    connect ElecPwrCns.SplyCurrEstim -> FordVltgIf.BattRtnCurr
    connect FordCanDtcInhb.FordEpsLifeCycMod -> FordMsg167BusHiSpd.FordEpsLifeCycMod
    connect FordCanDtcInhb.FordEpsLifeCycMod -> FordMsg202BusHiSpd.FordEpsLifeCycMod
    connect FordCanDtcInhb.FordEpsLifeCycMod -> FordMsg217BusHiSpd.FordEpsLifeCycMod
    connect FordCanDtcInhb.FordEpsLifeCycMod -> FordMsg3B3BusHiSpd.FordEpsLifeCycMod
    connect FordCanDtcInhb.FordEpsLifeCycMod -> FordMsg40ABusHiSpd.FordEpsLifeCycMod
    connect FordCanDtcInhb.FordEpsLifeCycMod -> FordMsg415BusHiSpd.FordEpsLifeCycMod
    connect FordCanDtcInhb.FordEpsLifeCycMod -> FordMsg41ABusHiSpd.FordEpsLifeCycMod
    connect FordCanDtcInhb.FordEpsLifeCycMod -> FordMsg41EBusHiSpd.FordEpsLifeCycMod
    connect FordCanDtcInhb.FordEpsLifeCycMod -> FordMsg430BusHiSpd.FordEpsLifeCycMod
    connect FordHwAgArbn.FordCmpdHwPosnQlyFac -> FordMsg07EBusHiSpd.CmpdSteerPinionAgQlyFac
    connect FordMsg167BusHiSpd.FordVehElecPwrSts -> FordCanDtcInhb.FordVehElecPwrSts
    connect FordMsg167BusHiSpd.FordVehPwrpkTqSts -> FordCanDtcInhb.FordVehPwrpkTqSts
    connect FordMsg167BusHiSpd.FordVehPwrpkTqSts -> FordSysSt.FordVehPwrpkTqSts
    connect FordMsg167BusHiSpd.FordVehElecPwrSts -> FordVltgIf.FordVehElecPwrSts
    connect FordMsg167BusHiSpd.FordVehPwrpkTqSts -> FordVltgIf.FordVehPwrpkTqSts
    connect FordMsg202BusHiSpd.FordVehSpdEngModl -> FordHwAgArbn.FordEngVehSpd
    connect FordMsg202BusHiSpd.FordVehSpdEngModl -> FordVehSpdArbn.FordVehSpdEngModl
    connect FordMsg202BusHiSpd.FordVehSpdEngModLoQlyVld -> FordVehSpdArbn.FordVehSpdEngModlLoQlyVld
    connect FordMsg202BusHiSpd.FordVehSpdEngModlVld -> FordVehSpdArbn.FordVehSpdEngModlVld
    connect FordMsg217BusHiSpd.FordVehFrntLeWhlSpd -> FordVehSpdArbn.FordVehFrntLeWhlSpd
    connect FordMsg217BusHiSpd.FordVehFrntLeWhlSpdVld -> FordVehSpdArbn.FordVehFrntLeWhlSpdVld
    connect FordMsg217BusHiSpd.FordVehFrntRiWhlSpd -> FordVehSpdArbn.FordVehFrntRiWhlSpd
    connect FordMsg217BusHiSpd.FordVehFrntRiWhlSpdVld -> FordVehSpdArbn.FordVehFrntRiWhlSpdVld
    connect FordMsg217BusHiSpd.FordVehReLeWhlSpd -> FordVehSpdArbn.FordVehReLeWhlSpd
    connect FordMsg217BusHiSpd.FordVehReLeWhlSpdVld -> FordVehSpdArbn.FordVehReLeWhlSpdVld
    connect FordMsg217BusHiSpd.FordVehReRiWhlSpd -> FordVehSpdArbn.FordVehReRiWhlSpd
    connect FordMsg217BusHiSpd.FordVehReRiWhlSpdVld -> FordVehSpdArbn.FordVehReRiWhlSpdVld
    connect FordMsg3B3BusHiSpd.FordVehIgnSts -> FordCanDtcInhb.FordVehIgnStsQly
    connect FordMsg3B3BusHiSpd.FordVehLifeCycMod -> FordCanDtcInhb.FordVehLifeCycModQly
    connect FordMsg40ABusHiSpd.FordVehTireCircum -> FordVehSpdArbn.FordVehTireCircumIn
    connect FordMsg414BusHiSpd.FordVehSteerPinionAgOffs -> FordHwAgArbn.FordSteerPinionOffs
    connect FordMsg414BusHiSpd.FordVehSteerPinionOffsSts -> FordHwAgArbn.FordSteerPinionOffsSts
    connect FordMsg415BusHiSpd.FordVehSpdBrkModl -> FordVehSpdArbn.FordVehSpdBrkModl
    connect FordMsg415BusHiSpd.FordVehSpdBrkModlLoQlyVld -> FordVehSpdArbn.FordVehSpdBrkModlLoQlyVld
    connect FordMsg415BusHiSpd.FordVehSpdBrkModlVld -> FordVehSpdArbn.FordVehSpdBrkModlVld
    connect FordSysSt.FordEpsSysSt -> FordCanDtcInhb.FordEpsSysSt
    connect FordSysSt.FordSteerModlSts -> FordMsg082BusHiSpd.FordSteerModlSts
    connect FordSysSt.FordEpsSysSt -> FordVltgIf.FordEpsSysSt
    connect FordSysSt.OperScaFctr -> StOutpCtrl.SysOperMotTqCmdSca
    connect FordSysSt.OperRampRate -> StOutpCtrl.SysOperRampRate
    connect FordSysSt.FordPwrSplyEnaReq -> SysStMod.PwrSplyEnaReq
    connect FordSysSt.SysStReqEna -> SysStMod.SysStReqEna
    connect FordVehSpdArbn.FordVehSpd -> VehSigCdng.VehSpdSerlCom
    connect FordVehSpdArbn.FordVehSpdVld -> VehSigCdng.VehSpdVldSerlCom
    connect FordVltgIf.FordInhbBattVltgDiagc -> BattVltgCorrln.InhbBattVltgDiagc
    connect FordVltgIf.FordEpsCurr -> FordMsg082BusHiSpd.ElecPwrSteerCurr
    connect FordVltgIf.FordEpsVltg -> FordMsg082BusHiSpd.ElecPwrSteerVltg
    connect FordVltgIf.FordVltgOperRamp -> FordSysSt.FordVltgOperRamp
    connect FordVltgIf.FordVltgOperScar -> FordSysSt.FordVltgOperScar
    connect FordVltgIf.FordVltgOperSt -> FordSysSt.FordVltgOperSt
    connect ImcArbn.GetSigImcData_f32 -> FordVltgIf.GetSigImcData_f32
    connect ImcSigArbn.HwTqImcCorrd -> FordHwAgArbn.FordInpTq
    connect ImcSigArbn.HwTqImcCorrd -> FordHwTqCdng.HwTq
    connect IoHwAb.GetGpioMcuEna -> FordCanDtcInhb.GetGpioMcuEna
    connect IoHwAb.GetGpioMcuEna -> FordHwAgArbn.GetGpioMcuEna
    connect IoHwAb.GetGpioMcuEna -> FordSysSt.GetGpioMcuEna
    connect LoaMgr.LoaSt -> FordSysSt.LoaSt
    connect PwrLimr.MotTqCmdPwrLimd -> FordHwTqCdng.MotTqCmdPwrLimd
    connect StabyCmp.AssiCmd -> FordHwTqCdng.AssiCmd
    connect Swp.MotTqCmdSwp -> FordHwTqCdng.MotTqCmd
    connect SysStMod.SysSt -> FordSysSt.SysSt
    connect SysStMod.SysSt -> FordVltgIf.FordSysSt
    connect VehSigCdng.VehSpdVld -> FordSysSt.FordVehSpdVld
    connect VehSigCdng.VehSpdVld -> FordVltgIf.FordVehSpdVld
    connect NvMProxy.PSProxy_Rte_NvmBlock_FordHwAgArbn_NonAbsOffs -> FordHwAgArbn.NonAbsOffs
    connect NvMProxy.PSProxy_Rte_NvmBlock_FordHwAgArbn_NonAbsOffsVldFlg -> FordHwAgArbn.NonAbsOffsVldFlg
    connect NvMProxy.PSProxy_Rte_NvmBlock_FordHwAgArbn_PrevIgnCycVal -> FordHwAgArbn.PrevIgnCycVal
    connect NvMProxy.PSProxy_Rte_NvmBlock_FordVehSpdArbn_FordVehTireCircum -> FordVehSpdArbn.FordVehTireCircum
    connect FordMsg3B3BusHiSpd.FordVehIgnSts -> FordVltgIf.FordVehIgnStsQly
    connect CustDiag.DataServices_DID_205A_Torque_Steer_Compensation_Activation_Counter -> Dcm.DataServices_DID_205A_Torque_Steer_Compensation_Activation_Counter
    connect CustDiag.DataServices_DID_205B_Brake_Pull_Reduction_Activation_Counter -> Dcm.DataServices_DID_205B_Brake_Pull_Reduction_Activation_Counter
    connect CustDiag.DataServices_DID_301A_Pull_Drift_Compensation_Value -> Dcm.DataServices_DID_301A_Pull_Drift_Compensation_Value
    connect CustDiag.DataServices_DID_301F_Steering_Pinion_Rotation_Speed -> Dcm.DataServices_DID_301F_Steering_Pinion_Rotation_Speed
    connect CustDiag.DataServices_DID_330C_Steering_Shaft_Torque_Sensor_2 -> Dcm.DataServices_DID_330C_Steering_Shaft_Torque_Sensor_2
    connect CustDiag.DataServices_DID_3B4B_Steering_wheel_angle_alignment_offset -> Dcm.DataServices_DID_3B4B_Steering_wheel_angle_alignment_offset
    connect CustDiag.DataServices_DID_630F_Multiple_VIN_Storage_Original_VIN -> Dcm.DataServices_DID_630F_Multiple_VIN_Storage_Original_VIN
    connect CustDiag.DataServices_DID_D111_ECU_Power_Supply_Voltage -> Dcm.DataServices_DID_D111_ECU_Power_Supply_Voltage
    connect CustDiag.DataServices_DID_D117_ECU_Internal_Temperature -> Dcm.DataServices_DID_D117_ECU_Internal_Temperature
    connect CustDiag.DataServices_DID_D118_Motor_Current -> Dcm.DataServices_DID_D118_Motor_Current
    connect CustDiag.DataServices_DID_DD00_Global_Real_Time -> Dcm.DataServices_DID_DD00_Global_Real_Time
    connect CustDiag.DataServices_DID_DD01_Total_Distance -> Dcm.DataServices_DID_DD01_Total_Distance
    connect CustDiag.DataServices_DID_DD09_Vehicle_Speed -> Dcm.DataServices_DID_DD09_Vehicle_Speed
    connect CustDiag.DataServices_DID_EE03_IgnCycleCounter -> Dcm.DataServices_DID_EE03_IgnCycleCounter
    connect CustDiag.DataServices_DID_EE04_IgnOnTime -> Dcm.DataServices_DID_EE04_IgnOnTime
    connect CustDiag.DataServices_DID_EE05_FinalMotTq -> Dcm.DataServices_DID_EE05_FinalMotTq
    connect CustDiag.DataServices_DID_EE06_VINChanged -> Dcm.DataServices_DID_EE06_VINChanged
    connect CustDiag.DataServices_DID_EE07_EPSSystemState -> Dcm.DataServices_DID_EE07_EPSSystemState
    connect CustDiag.DataServices_DID_EE20_LoAFaultReporting -> Dcm.DataServices_DID_EE20_LoAFaultReporting
    connect CustDiag.DataServices_DID_EE21_CurrentLvlCounter -> Dcm.DataServices_DID_EE21_CurrentLvlCounter
    connect CustDiag.DataServices_DID_EE22_VoltageLvlCounters -> Dcm.DataServices_DID_EE22_VoltageLvlCounters
    connect CustDiag.DataServices_DID_EE23_TempLvlCounters -> Dcm.DataServices_DID_EE23_TempLvlCounters
    connect CustDiag.DataServices_DID_EE40_ResearchMessConfig -> Dcm.DataServices_DID_EE40_ResearchMessConfig
    connect CustDiag.DataServices_DID_EE41_ResearchFeatureSwitch -> Dcm.DataServices_DID_EE41_ResearchFeatureSwitch
    connect CustDiag.DataServices_DID_EE42_ActiveFeatures -> Dcm.DataServices_DID_EE42_ActiveFeatures
    connect CustDiag.DataServices_DID_EE43_SDMSteeringMode -> Dcm.DataServices_DID_EE43_SDMSteeringMode
    connect CustDiag.DataServices_DID_EE80_FIHSwVer -> Dcm.DataServices_DID_EE80_FIHSwVer
    connect CustDiag.DataServices_DID_EE81_FIHSwReserved0 -> Dcm.DataServices_DID_EE81_FIHSwReserved0
    connect CustDiag.DataServices_DID_EE82_FIHSwReserved1 -> Dcm.DataServices_DID_EE82_FIHSwReserved1
    connect CustDiag.DataServices_DID_EE83_FIHSwReserved2 -> Dcm.DataServices_DID_EE83_FIHSwReserved2
    connect CustDiag.DataServices_DID_EE84_FIHSwReserved3 -> Dcm.DataServices_DID_EE84_FIHSwReserved3
    connect CustDiag.DataServices_DID_EE85_FIHSwReserved4 -> Dcm.DataServices_DID_EE85_FIHSwReserved4
    connect CustDiag.DataServices_DID_EE86_FIHSwReserved5 -> Dcm.DataServices_DID_EE86_FIHSwReserved5
    connect CustDiag.DataServices_DID_EE87_FIHSwReserved6 -> Dcm.DataServices_DID_EE87_FIHSwReserved6
    connect CustDiag.DataServices_DID_EE88_FIHSwReserved7 -> Dcm.DataServices_DID_EE88_FIHSwReserved7
    connect CustDiag.DataServices_DID_EED0_SupplierFactoryMode -> Dcm.DataServices_DID_EED0_SupplierFactoryMode
    connect CustDiag.DataServices_DID_EED1_SupplierInternalFaultCode -> Dcm.DataServices_DID_EED1_SupplierInternalFaultCode
